VERSION ""

NS_ :

BS_:

BU_: WPC2 PSB SHVU_RR FCS EMCU SLB GW_APSU GW_DLBCU ARS RCM CGW_CCU GW_RLPSU ATS RLHV SGU PFSU ALBCU GW_RRPSU DSAU SWRC SHVU_FR RCS GW_DPSU BLTN_CAM SCM OHCL RWPC RRHV WPC HOD ASAU

BO_ 2214658050 EMS_02_10ms_2: 8 CGW_CCU
 SG_ ENG_AccelPdlVal : 24|10@1+ (0.09784,0) [0|0] "%"  BLTN_CAM,EMCU

BO_ 2210462210 HCU_03_10ms_2: 8 CGW_CCU
 SG_ HCU_HevRdySta : 6|2@1+ (1,0) [0|0] ""  BLTN_CAM,GW_APSU,GW_DLBCU,GW_DPSU,GW_RLPSU,GW_RRPSU,HOD,PFSU,PSB,RCM,RLHV,RRHV,RWPC,SCM,SHVU_FR,SHVU_RR,SWRC,WPC,WPC2

BO_ 1167 ICU_11_1000ms: 8 CGW_CCU
 SG_ ICU_BattAutoCutPreWrng : 36|2@1+ (1,0) [0|0] ""  BLTN_CAM

BO_ 1015 HU_GNSS_13_1000ms: 8 CGW_CCU
 SG_ HU_MM_Altitude : 0|32@1- (0.01,0) [0|0] "m"  BLTN_CAM
 SG_ HU_MM_Heading : 32|32@1+ (1,0) [0|0] "˚"  BLTN_CAM

BO_ 763 SBCM_DRV_03_200ms: 8 CGW_CCU
 SG_ Warn_HoodSwSta_SBCM : 36|2@1+ (1,0) [0|0] ""  BLTN_CAM
 SG_ Hood_TypeOption : 38|2@1+ (1,0) [0|0] ""  BLTN_CAM

BO_ 1048 ICU_08_200ms: 8 CGW_CCU
 SG_ DriveTypeOption : 16|2@1+ (1,0) [0|0] ""  ATS,BLTN_CAM,GW_APSU,GW_DLBCU,GW_DPSU,GW_RLPSU,GW_RRPSU,SHVU_FR,SHVU_RR
 SG_ ICU_PowerAutoCutModSta : 35|2@1+ (1,0) [0|0] ""  BLTN_CAM,GW_APSU,GW_DPSU,GW_RLPSU,GW_RRPSU,PFSU,RLHV,RRHV,SHVU_FR,SHVU_RR

BO_ 1050 BCM_07_200ms: 8 CGW_CCU
 SG_ Lamp_ExtrnlTailLmpOnReq : 38|2@1+ (1,0) [0|0] ""  BLTN_CAM

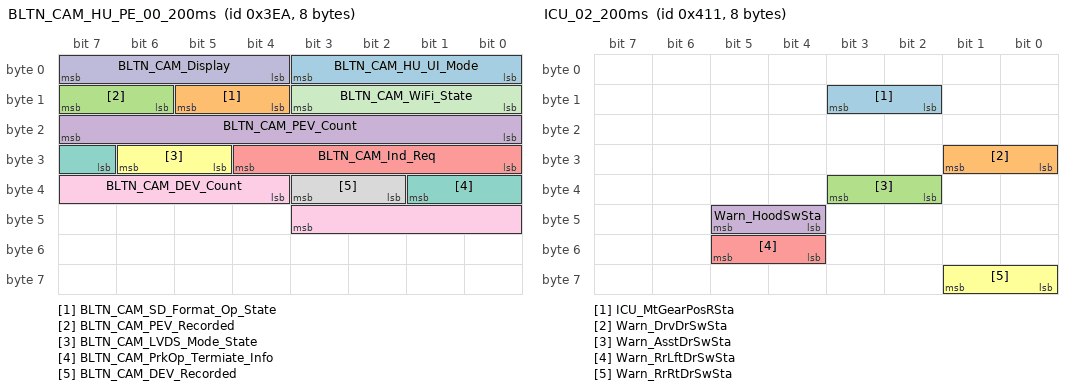
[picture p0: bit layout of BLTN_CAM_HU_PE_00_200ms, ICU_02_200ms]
BO_ 1002 BLTN_CAM_HU_PE_00_200ms: 8 BLTN_CAM
 SG_ BLTN_CAM_HU_UI_Mode : 0|4@1+ (1,0) [0|0] ""  CGW_CCU
 SG_ BLTN_CAM_SD_Format_Op_State : 12|2@1+ (1,0) [0|0] ""  CGW_CCU
 SG_ BLTN_CAM_PEV_Recorded : 14|2@1+ (1,0) [0|0] ""  CGW_CCU
 SG_ BLTN_CAM_PEV_Count : 16|8@1+ (1,0) [0|0] ""  CGW_CCU
 SG_ BLTN_CAM_Ind_Req : 24|5@1+ (1,0) [0|0] ""  CGW_CCU
 SG_ BLTN_CAM_LVDS_Mode_State : 29|2@1+ (1,0) [0|0] ""  CGW_CCU
 SG_ BLTN_CAM_PrkOp_Termiate_Info : 31|3@1+ (1,0) [0|0] ""  CGW_CCU
 SG_ BLTN_CAM_DEV_Recorded : 34|2@1+ (1,0) [0|0] ""  CGW_CCU
 SG_ BLTN_CAM_DEV_Count : 36|8@1+ (1,0) [0|0] ""  CGW_CCU
 SG_ BLTN_CAM_Display : 4|4@1+ (1,0) [0|0] ""  CGW_CCU
 SG_ BLTN_CAM_WiFi_State : 8|4@1+ (1,0) [0|0] ""  CGW_CCU

BO_ 1041 ICU_02_200ms: 8 CGW_CCU
 SG_ ICU_MtGearPosRSta : 10|2@1+ (1,0) [0|0] ""  BLTN_CAM
 SG_ Warn_DrvDrSwSta : 24|2@1+ (1,0) [0|0] ""  BLTN_CAM,GW_DPSU,PSB,RWPC,WPC,WPC2
 SG_ Warn_AsstDrSwSta : 34|2@1+ (1,0) [0|0] ""  ALBCU,BLTN_CAM,GW_APSU,GW_RLPSU,GW_RRPSU,PSB,RWPC,WPC,WPC2
 SG_ Warn_HoodSwSta : 44|2@1+ (1,0) [0|0] ""  BLTN_CAM
 SG_ Warn_RrLftDrSwSta : 52|2@1+ (1,0) [0|0] ""  BLTN_CAM,GW_APSU,GW_RLPSU,GW_RRPSU,RLHV,RWPC,WPC,WPC2
 SG_ Warn_RrRtDrSwSta : 56|2@1+ (1,0) [0|0] ""  BLTN_CAM,GW_APSU,GW_RLPSU,GW_RRPSU,RRHV,RWPC,WPC,WPC2

BO_ 992 BCM_02_200ms: 8 CGW_CCU
 SG_ BAlarm_BglrAlrmCurrentSta : 16|4@1+ (1,0) [0|0] ""  BLTN_CAM

BO_ 1040 ICU_10_200ms: 8 CGW_CCU
 SG_ ICU_BS2SoC : 16|8@1+ (1,0) [0|0] ""  BLTN_CAM

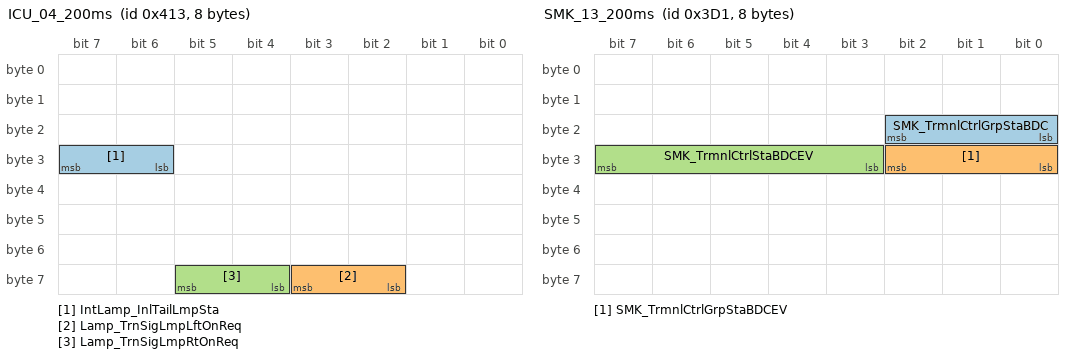
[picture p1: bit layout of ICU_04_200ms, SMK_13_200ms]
BO_ 1043 ICU_04_200ms: 8 CGW_CCU
 SG_ IntLamp_InlTailLmpSta : 30|2@1+ (1,0) [0|0] ""  SWRC,BLTN_CAM,WPC2
 SG_ Lamp_TrnSigLmpLftOnReq : 58|2@1+ (1,0) [0|0] ""  BLTN_CAM
 SG_ Lamp_TrnSigLmpRtOnReq : 60|2@1+ (1,0) [0|0] ""  BLTN_CAM

BO_ 1044 ICU_05_200ms: 8 CGW_CCU
 SG_ Trunk_TrnkTlgtSwSta : 20|2@1+ (1,0) [0|0] ""  BLTN_CAM,GW_APSU,GW_RLPSU,GW_RRPSU,PFSU,RLHV,RRHV
 SG_ C_CrashUnlockState : 58|2@1+ (1,0) [0|0] ""  BLTN_CAM

BO_ 1186 HU_GW_E_02: 8 CGW_CCU
 SG_ C_PreCrankReq : 30|2@1+ (1,0) [0|0] ""  BLTN_CAM

BO_ 1058 BCM_10_200ms: 8 CGW_CCU
 SG_ Wiper_PrkngPosSta : 16|2@1+ (1,0) [0|0] ""  BLTN_CAM
 SG_ Wiper_RainSnsrSta : 22|4@1+ (1,0) [0|0] ""  BLTN_CAM

BO_ 1195 HU_USM_E_04: 8 CGW_CCU
 SG_ CF_AVN_CluUSMReset : 62|2@1+ (1,0) [0|0] ""  ALBCU,ARS,ASAU,ATS,BLTN_CAM,DSAU,GW_APSU,GW_DLBCU,GW_DPSU,GW_RLPSU,GW_RRPSU,PFSU,RCM,RLHV,RRHV,RWPC,SGU,SHVU_FR,SHVU_RR,SLB,WPC,WPC2

BO_ 858 SBCM_AST_02_200ms: 8 CGW_CCU
 SG_ AST_CrashUnlockCmd : 10|1@1+ (1,0) [0|0] ""  BLTN_CAM
 SG_ Warn_AsstDrSwSta_SBCM : 20|2@1+ (1,0) [0|0] ""  ALBCU,ATS,BLTN_CAM,GW_APSU,GW_RLPSU,GW_RRPSU,PSB,RWPC,WPC,WPC2

BO_ 977 SMK_13_200ms: 8 CGW_CCU
 SG_ SMK_TrmnlCtrlGrpStaBDC : 16|3@1+ (1,0) [0|0] ""  BLTN_CAM
 SG_ SMK_TrmnlCtrlGrpStaBDCEV : 24|3@1+ (1,0) [0|0] ""  BLTN_CAM
 SG_ SMK_TrmnlCtrlStaBDCEV : 27|5@1+ (1,0) [0|0] ""  BLTN_CAM

BO_ 862 SBCM_RL_01_200ms: 8 CGW_CCU
 SG_ RL_CrashUnlockCmd : 10|1@1+ (1,0) [0|0] ""  BLTN_CAM
 SG_ Warn_RrLftDrSwSta_SBCM : 16|2@1+ (1,0) [0|0] ""  ATS,BLTN_CAM,GW_APSU,GW_RLPSU,GW_RRPSU,RWPC,WPC,WPC2

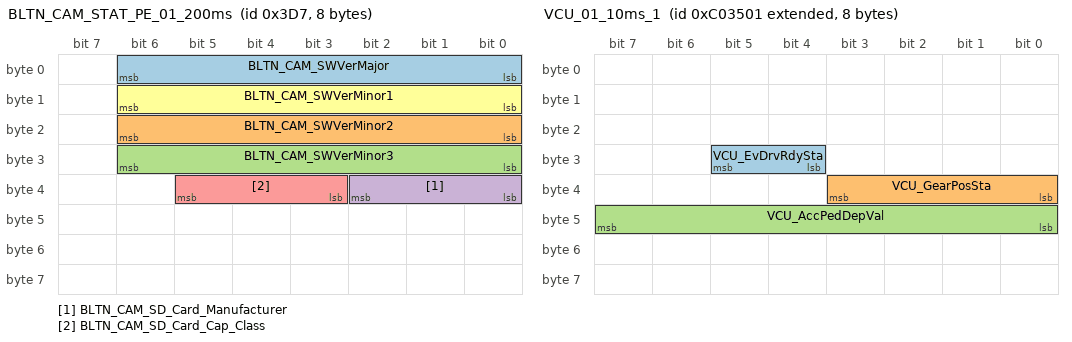
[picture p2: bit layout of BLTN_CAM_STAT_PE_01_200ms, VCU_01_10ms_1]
BO_ 983 BLTN_CAM_STAT_PE_01_200ms: 8 BLTN_CAM
 SG_ BLTN_CAM_SWVerMajor : 0|7@1+ (1,0) [0|0] ""  CGW_CCU
 SG_ BLTN_CAM_SWVerMinor2 : 16|7@1+ (1,0) [0|0] ""  CGW_CCU
 SG_ BLTN_CAM_SWVerMinor3 : 24|7@1+ (1,0) [0|0] ""  CGW_CCU
 SG_ BLTN_CAM_SD_Card_Manufacturer : 32|3@1+ (1,0) [0|0] ""  CGW_CCU
 SG_ BLTN_CAM_SD_Card_Cap_Class : 35|3@1+ (1,1) [0|0] ""  CGW_CCU
 SG_ BLTN_CAM_SWVerMinor1 : 8|7@1+ (1,0) [0|0] ""  CGW_CCU

BO_ 2160080132 VCU_01_10ms_4: 8 CGW_CCU
 SG_ VCU_GearPosStaDisp : 0|4@1+ (1,0) [0|0] ""  SWRC,BLTN_CAM

BO_ 721 HU_GNSS_15_100ms: 8 CGW_CCU
 SG_ HU_DR_Altitude : 17|16@1- (1,0) [0|0] "m"  BLTN_CAM

BO_ 722 HU_GNSS_16_100ms: 8 CGW_CCU
 SG_ HU_DR_Latitude : 0|32@1- (1,0) [0|0] "˚"  BLTN_CAM
 SG_ HU_DR_Longitude : 32|32@1- (1,0) [0|0] "˚"  BLTN_CAM

BO_ 723 HU_GNSS_17_100ms: 8 CGW_CCU
 SG_ HU_DR_Heading : 0|16@1+ (1,0) [0|0] "˚"  BLTN_CAM

BO_ 2160080129 VCU_01_10ms_1: 8 CGW_CCU
 SG_ VCU_EvDrvRdySta : 28|2@1+ (1,0) [0|3] ""  BLTN_CAM,GW_APSU,GW_DLBCU,GW_DPSU,GW_RLPSU,GW_RRPSU,HOD,PFSU,PSB,RCM,RLHV,RRHV,RWPC,SCM,SHVU_FR,SHVU_RR,SWRC,WPC,WPC2
 SG_ VCU_GearPosSta : 32|4@1+ (1,0) [0|15] ""  BLTN_CAM,GW_APSU,GW_DPSU,GW_RLPSU,GW_RRPSU,PFSU,SGU,WPC2
 SG_ VCU_AccPedDepVal : 40|8@1+ (0.3921568627,0) [0|100] "%"  BLTN_CAM

BO_ 1079 CTM_01_200ms: 8 CGW_CCU
 SG_ CTM_TrailerAct : 0|2@1+ (1,0) [0|0] ""  BLTN_CAM

BO_ 2164278529 HTCU_04_10ms_1: 8 CGW_CCU
 SG_ HTCU_GearSlctrDis : 44|4@1+ (1,0) [0|0] ""  BLTN_CAM,GW_APSU,GW_DPSU,GW_RLPSU,GW_RRPSU,PFSU,SWRC

BO_ 1076 IAU_16_200ms: 8 CGW_CCU
 SG_ IAU_ProfileIDRVal : 10|4@1+ (1,0) [0|0] ""  BLTN_CAM,GW_DLBCU,GW_DPSU,RCM,RWPC,SGU,WPC,WPC2

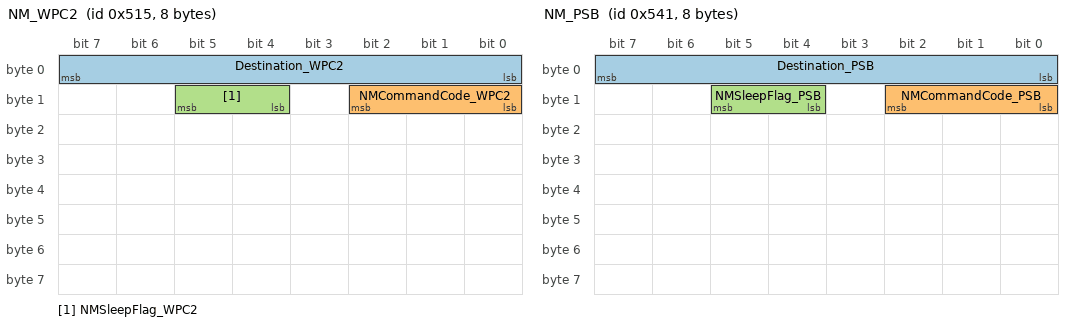
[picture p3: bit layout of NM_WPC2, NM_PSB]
BO_ 1301 NM_WPC2: 8 WPC2
 SG_ Destination_WPC2 : 0|8@1+ (1,0) [0|0] ""  PSB,SHVU_RR,FCS,EMCU,SLB,GW_APSU,GW_DLBCU,ARS,RCM,CGW_CCU,GW_RLPSU,ATS,RLHV,SGU,PFSU,ALBCU,GW_RRPSU,DSAU,SWRC,SHVU_FR,RCS,GW_DPSU,BLTN_CAM,SCM,OHCL,RWPC,RRHV,WPC,HOD,ASAU
 SG_ NMCommandCode_WPC2 : 8|3@1+ (1,0) [0|0] ""  PSB,SHVU_RR,FCS,EMCU,SLB,GW_APSU,GW_DLBCU,ARS,RCM,CGW_CCU,GW_RLPSU,ATS,RLHV,SGU,PFSU,ALBCU,GW_RRPSU,DSAU,SWRC,SHVU_FR,RCS,GW_DPSU,BLTN_CAM,SCM,OHCL,RWPC,RRHV,WPC,HOD,ASAU
 SG_ NMSleepFlag_WPC2 : 12|2@1+ (1,0) [0|0] ""  PSB,SHVU_RR,FCS,EMCU,SLB,GW_APSU,GW_DLBCU,ARS,RCM,CGW_CCU,GW_RLPSU,ATS,RLHV,SGU,PFSU,ALBCU,GW_RRPSU,DSAU,SWRC,SHVU_FR,RCS,GW_DPSU,BLTN_CAM,SCM,OHCL,RWPC,RRHV,WPC,HOD,ASAU

BO_ 1345 NM_PSB: 8 PSB
 SG_ Destination_PSB : 0|8@1+ (1,0) [0|0] ""  WPC2,SHVU_RR,FCS,EMCU,SLB,GW_APSU,GW_DLBCU,ARS,RCM,CGW_CCU,GW_RLPSU,ATS,RLHV,SGU,PFSU,ALBCU,GW_RRPSU,DSAU,SWRC,SHVU_FR,RCS,GW_DPSU,BLTN_CAM,SCM,OHCL,RWPC,RRHV,WPC,HOD,ASAU
 SG_ NMCommandCode_PSB : 8|3@1+ (1,0) [0|0] ""  WPC2,SHVU_RR,FCS,EMCU,SLB,GW_APSU,GW_DLBCU,ARS,RCM,CGW_CCU,GW_RLPSU,ATS,RLHV,SGU,PFSU,ALBCU,GW_RRPSU,DSAU,SWRC,SHVU_FR,RCS,GW_DPSU,BLTN_CAM,SCM,OHCL,RWPC,RRHV,WPC,HOD,ASAU
 SG_ NMSleepFlag_PSB : 12|2@1+ (1,0) [0|0] ""  WPC2,SHVU_RR,FCS,EMCU,SLB,GW_APSU,GW_DLBCU,ARS,RCM,CGW_CCU,GW_RLPSU,ATS,RLHV,SGU,PFSU,ALBCU,GW_RRPSU,DSAU,SWRC,SHVU_FR,RCS,GW_DPSU,BLTN_CAM,SCM,OHCL,RWPC,RRHV,WPC,HOD,ASAU

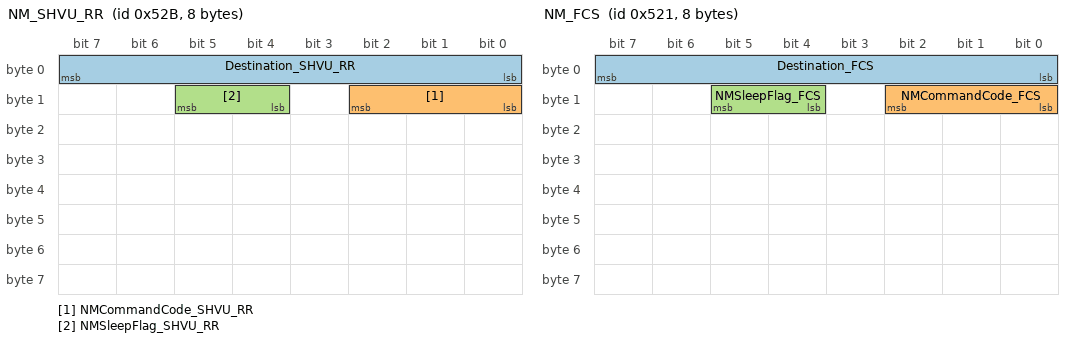
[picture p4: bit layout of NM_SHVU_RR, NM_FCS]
BO_ 1323 NM_SHVU_RR: 8 SHVU_RR
 SG_ Destination_SHVU_RR : 0|8@1+ (1,0) [0|0] ""  WPC2,PSB,FCS,EMCU,SLB,GW_APSU,GW_DLBCU,ARS,RCM,CGW_CCU,GW_RLPSU,ATS,RLHV,SGU,PFSU,ALBCU,GW_RRPSU,DSAU,SWRC,SHVU_FR,RCS,GW_DPSU,BLTN_CAM,SCM,OHCL,RWPC,RRHV,WPC,HOD,ASAU
 SG_ NMCommandCode_SHVU_RR : 8|3@1+ (1,0) [0|0] ""  WPC2,PSB,FCS,EMCU,SLB,GW_APSU,GW_DLBCU,ARS,RCM,CGW_CCU,GW_RLPSU,ATS,RLHV,SGU,PFSU,ALBCU,GW_RRPSU,DSAU,SWRC,SHVU_FR,RCS,GW_DPSU,BLTN_CAM,SCM,OHCL,RWPC,RRHV,WPC,HOD,ASAU
 SG_ NMSleepFlag_SHVU_RR : 12|2@1+ (1,0) [0|0] ""  WPC2,PSB,FCS,EMCU,SLB,GW_APSU,GW_DLBCU,ARS,RCM,CGW_CCU,GW_RLPSU,ATS,RLHV,SGU,PFSU,ALBCU,GW_RRPSU,DSAU,SWRC,SHVU_FR,RCS,GW_DPSU,BLTN_CAM,SCM,OHCL,RWPC,RRHV,WPC,HOD,ASAU

BO_ 1313 NM_FCS: 8 FCS
 SG_ Destination_FCS : 0|8@1+ (1,0) [0|0] ""  WPC2,PSB,SHVU_RR,EMCU,SLB,GW_APSU,GW_DLBCU,ARS,RCM,CGW_CCU,GW_RLPSU,ATS,RLHV,SGU,PFSU,ALBCU,GW_RRPSU,DSAU,SWRC,SHVU_FR,RCS,GW_DPSU,BLTN_CAM,SCM,OHCL,RWPC,RRHV,WPC,HOD,ASAU
 SG_ NMCommandCode_FCS : 8|3@1+ (1,0) [0|0] ""  WPC2,PSB,SHVU_RR,EMCU,SLB,GW_APSU,GW_DLBCU,ARS,RCM,CGW_CCU,GW_RLPSU,ATS,RLHV,SGU,PFSU,ALBCU,GW_RRPSU,DSAU,SWRC,SHVU_FR,RCS,GW_DPSU,BLTN_CAM,SCM,OHCL,RWPC,RRHV,WPC,HOD,ASAU
 SG_ NMSleepFlag_FCS : 12|2@1+ (1,0) [0|0] ""  WPC2,PSB,SHVU_RR,EMCU,SLB,GW_APSU,GW_DLBCU,ARS,RCM,CGW_CCU,GW_RLPSU,ATS,RLHV,SGU,PFSU,ALBCU,GW_RRPSU,DSAU,SWRC,SHVU_FR,RCS,GW_DPSU,BLTN_CAM,SCM,OHCL,RWPC,RRHV,WPC,HOD,ASAU

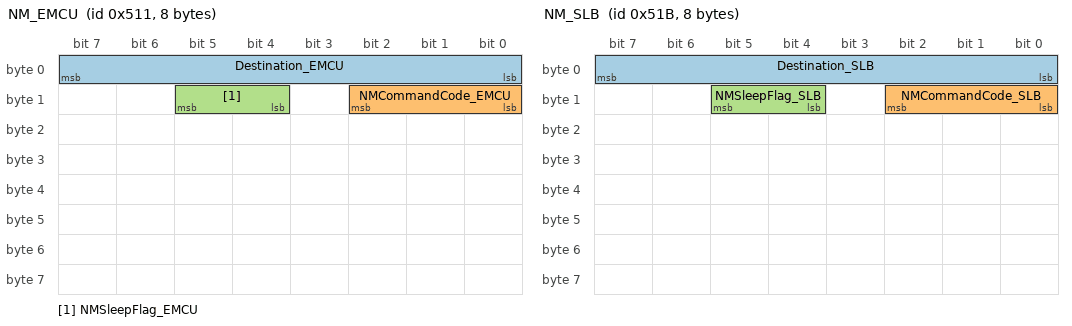
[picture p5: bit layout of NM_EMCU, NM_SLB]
BO_ 1297 NM_EMCU: 8 EMCU
 SG_ Destination_EMCU : 0|8@1+ (1,0) [0|0] ""  WPC2,PSB,SHVU_RR,FCS,SLB,GW_APSU,GW_DLBCU,ARS,RCM,CGW_CCU,GW_RLPSU,ATS,RLHV,SGU,PFSU,ALBCU,GW_RRPSU,DSAU,SWRC,SHVU_FR,RCS,GW_DPSU,BLTN_CAM,SCM,OHCL,RWPC,RRHV,WPC,HOD,ASAU
 SG_ NMCommandCode_EMCU : 8|3@1+ (1,0) [0|0] ""  WPC2,PSB,SHVU_RR,FCS,SLB,GW_APSU,GW_DLBCU,ARS,RCM,CGW_CCU,GW_RLPSU,ATS,RLHV,SGU,PFSU,ALBCU,GW_RRPSU,DSAU,SWRC,SHVU_FR,RCS,GW_DPSU,BLTN_CAM,SCM,OHCL,RWPC,RRHV,WPC,HOD,ASAU
 SG_ NMSleepFlag_EMCU : 12|2@1+ (1,0) [0|0] ""  WPC2,PSB,SHVU_RR,FCS,SLB,GW_APSU,GW_DLBCU,ARS,RCM,CGW_CCU,GW_RLPSU,ATS,RLHV,SGU,PFSU,ALBCU,GW_RRPSU,DSAU,SWRC,SHVU_FR,RCS,GW_DPSU,BLTN_CAM,SCM,OHCL,RWPC,RRHV,WPC,HOD,ASAU

BO_ 1307 NM_SLB: 8 SLB
 SG_ Destination_SLB : 0|8@1+ (1,0) [0|0] ""  WPC2,PSB,SHVU_RR,FCS,EMCU,GW_APSU,GW_DLBCU,ARS,RCM,CGW_CCU,GW_RLPSU,ATS,RLHV,SGU,PFSU,ALBCU,GW_RRPSU,DSAU,SWRC,SHVU_FR,RCS,GW_DPSU,BLTN_CAM,SCM,OHCL,RWPC,RRHV,WPC,HOD,ASAU
 SG_ NMCommandCode_SLB : 8|3@1+ (1,0) [0|0] ""  WPC2,PSB,SHVU_RR,FCS,EMCU,GW_APSU,GW_DLBCU,ARS,RCM,CGW_CCU,GW_RLPSU,ATS,RLHV,SGU,PFSU,ALBCU,GW_RRPSU,DSAU,SWRC,SHVU_FR,RCS,GW_DPSU,BLTN_CAM,SCM,OHCL,RWPC,RRHV,WPC,HOD,ASAU
 SG_ NMSleepFlag_SLB : 12|2@1+ (1,0) [0|0] ""  WPC2,PSB,SHVU_RR,FCS,EMCU,GW_APSU,GW_DLBCU,ARS,RCM,CGW_CCU,GW_RLPSU,ATS,RLHV,SGU,PFSU,ALBCU,GW_RRPSU,DSAU,SWRC,SHVU_FR,RCS,GW_DPSU,BLTN_CAM,SCM,OHCL,RWPC,RRHV,WPC,HOD,ASAU

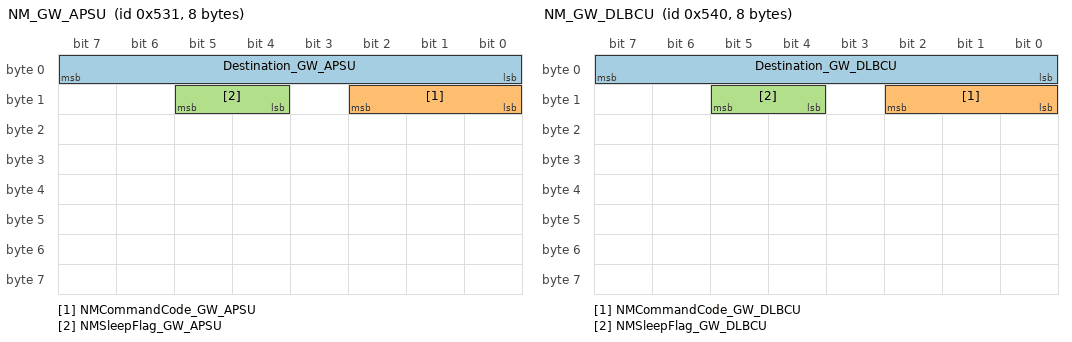
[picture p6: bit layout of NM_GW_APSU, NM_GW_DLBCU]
BO_ 1329 NM_GW_APSU: 8 GW_APSU
 SG_ Destination_GW_APSU : 0|8@1+ (1,0) [0|0] ""  WPC2,PSB,SHVU_RR,FCS,EMCU,SLB,GW_DLBCU,ARS,RCM,CGW_CCU,GW_RLPSU,ATS,RLHV,SGU,PFSU,ALBCU,GW_RRPSU,DSAU,SWRC,SHVU_FR,RCS,GW_DPSU,BLTN_CAM,SCM,OHCL,RWPC,RRHV,WPC,HOD,ASAU
 SG_ NMCommandCode_GW_APSU : 8|3@1+ (1,0) [0|0] ""  WPC2,PSB,SHVU_RR,FCS,EMCU,SLB,GW_DLBCU,ARS,RCM,CGW_CCU,GW_RLPSU,ATS,RLHV,SGU,PFSU,ALBCU,GW_RRPSU,DSAU,SWRC,SHVU_FR,RCS,GW_DPSU,BLTN_CAM,SCM,OHCL,RWPC,RRHV,WPC,HOD,ASAU
 SG_ NMSleepFlag_GW_APSU : 12|2@1+ (1,0) [0|0] ""  WPC2,PSB,SHVU_RR,FCS,EMCU,SLB,GW_DLBCU,ARS,RCM,CGW_CCU,GW_RLPSU,ATS,RLHV,SGU,PFSU,ALBCU,GW_RRPSU,DSAU,SWRC,SHVU_FR,RCS,GW_DPSU,BLTN_CAM,SCM,OHCL,RWPC,RRHV,WPC,HOD,ASAU

BO_ 1344 NM_GW_DLBCU: 8 GW_DLBCU
 SG_ Destination_GW_DLBCU : 0|8@1+ (1,0) [0|0] ""  WPC2,PSB,SHVU_RR,FCS,EMCU,SLB,GW_APSU,ARS,RCM,CGW_CCU,GW_RLPSU,ATS,RLHV,SGU,PFSU,ALBCU,GW_RRPSU,DSAU,SWRC,SHVU_FR,RCS,GW_DPSU,BLTN_CAM,SCM,OHCL,RWPC,RRHV,WPC,HOD,ASAU
 SG_ NMCommandCode_GW_DLBCU : 8|3@1+ (1,0) [0|0] ""  WPC2,PSB,SHVU_RR,FCS,EMCU,SLB,GW_APSU,ARS,RCM,CGW_CCU,GW_RLPSU,ATS,RLHV,SGU,PFSU,ALBCU,GW_RRPSU,DSAU,SWRC,SHVU_FR,RCS,GW_DPSU,BLTN_CAM,SCM,OHCL,RWPC,RRHV,WPC,HOD,ASAU
 SG_ NMSleepFlag_GW_DLBCU : 12|2@1+ (1,0) [0|0] ""  WPC2,PSB,SHVU_RR,FCS,EMCU,SLB,GW_APSU,ARS,RCM,CGW_CCU,GW_RLPSU,ATS,RLHV,SGU,PFSU,ALBCU,GW_RRPSU,DSAU,SWRC,SHVU_FR,RCS,GW_DPSU,BLTN_CAM,SCM,OHCL,RWPC,RRHV,WPC,HOD,ASAU

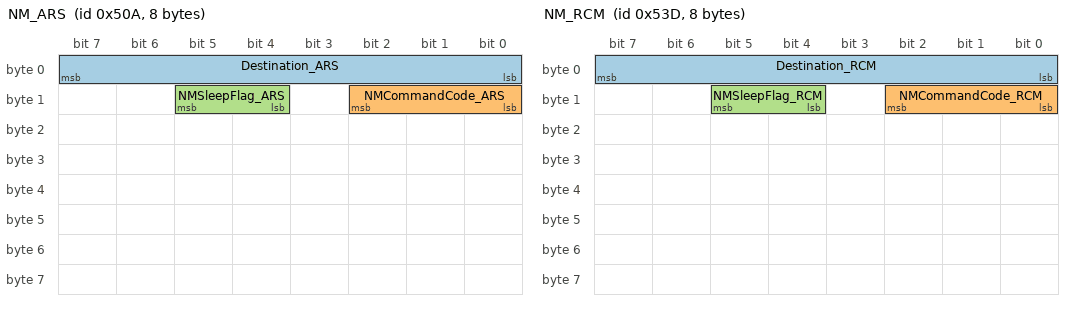
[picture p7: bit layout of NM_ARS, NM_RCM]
BO_ 1290 NM_ARS: 8 ARS
 SG_ Destination_ARS : 0|8@1+ (1,0) [0|0] ""  WPC2,PSB,SHVU_RR,FCS,EMCU,SLB,GW_APSU,GW_DLBCU,RCM,CGW_CCU,GW_RLPSU,ATS,RLHV,SGU,PFSU,ALBCU,GW_RRPSU,DSAU,SWRC,SHVU_FR,RCS,GW_DPSU,BLTN_CAM,SCM,OHCL,RWPC,RRHV,WPC,HOD,ASAU
 SG_ NMCommandCode_ARS : 8|3@1+ (1,0) [0|0] ""  WPC2,PSB,SHVU_RR,FCS,EMCU,SLB,GW_APSU,GW_DLBCU,RCM,CGW_CCU,GW_RLPSU,ATS,RLHV,SGU,PFSU,ALBCU,GW_RRPSU,DSAU,SWRC,SHVU_FR,RCS,GW_DPSU,BLTN_CAM,SCM,OHCL,RWPC,RRHV,WPC,HOD,ASAU
 SG_ NMSleepFlag_ARS : 12|2@1+ (1,0) [0|0] ""  WPC2,PSB,SHVU_RR,FCS,EMCU,SLB,GW_APSU,GW_DLBCU,RCM,CGW_CCU,GW_RLPSU,ATS,RLHV,SGU,PFSU,ALBCU,GW_RRPSU,DSAU,SWRC,SHVU_FR,RCS,GW_DPSU,BLTN_CAM,SCM,OHCL,RWPC,RRHV,WPC,HOD,ASAU

BO_ 1341 NM_RCM: 8 RCM
 SG_ Destination_RCM : 0|8@1+ (1,0) [0|0] ""  WPC2,PSB,SHVU_RR,FCS,EMCU,SLB,GW_APSU,GW_DLBCU,ARS,CGW_CCU,GW_RLPSU,ATS,RLHV,SGU,PFSU,ALBCU,GW_RRPSU,DSAU,SWRC,SHVU_FR,RCS,GW_DPSU,BLTN_CAM,SCM,OHCL,RWPC,RRHV,WPC,HOD,ASAU
 SG_ NMCommandCode_RCM : 8|3@1+ (1,0) [0|0] ""  WPC2,PSB,SHVU_RR,FCS,EMCU,SLB,GW_APSU,GW_DLBCU,ARS,CGW_CCU,GW_RLPSU,ATS,RLHV,SGU,PFSU,ALBCU,GW_RRPSU,DSAU,SWRC,SHVU_FR,RCS,GW_DPSU,BLTN_CAM,SCM,OHCL,RWPC,RRHV,WPC,HOD,ASAU
 SG_ NMSleepFlag_RCM : 12|2@1+ (1,0) [0|0] ""  WPC2,PSB,SHVU_RR,FCS,EMCU,SLB,GW_APSU,GW_DLBCU,ARS,CGW_CCU,GW_RLPSU,ATS,RLHV,SGU,PFSU,ALBCU,GW_RRPSU,DSAU,SWRC,SHVU_FR,RCS,GW_DPSU,BLTN_CAM,SCM,OHCL,RWPC,RRHV,WPC,HOD,ASAU

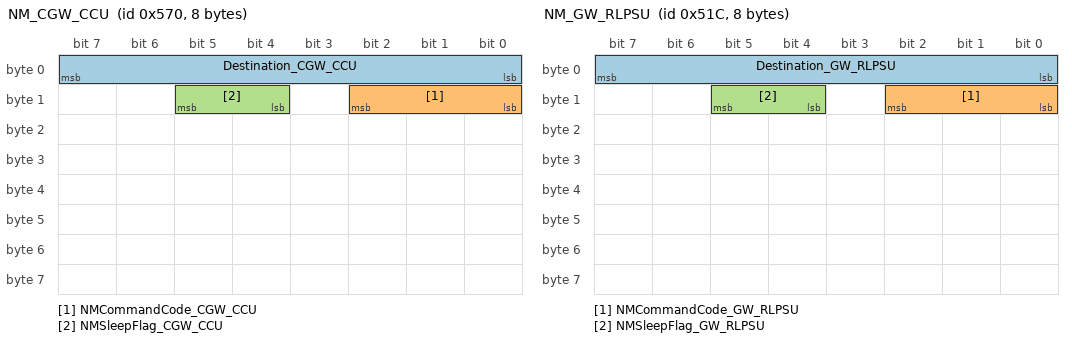
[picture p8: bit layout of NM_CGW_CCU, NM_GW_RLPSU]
BO_ 1392 NM_CGW_CCU: 8 CGW_CCU
 SG_ Destination_CGW_CCU : 0|8@1+ (1,0) [0|0] ""  WPC2,PSB,SHVU_RR,FCS,EMCU,SLB,GW_APSU,GW_DLBCU,ARS,RCM,GW_RLPSU,ATS,RLHV,SGU,PFSU,ALBCU,GW_RRPSU,DSAU,SWRC,SHVU_FR,RCS,GW_DPSU,BLTN_CAM,SCM,OHCL,RWPC,RRHV,WPC,HOD,ASAU
 SG_ NMCommandCode_CGW_CCU : 8|3@1+ (1,0) [0|0] ""  WPC2,PSB,SHVU_RR,FCS,EMCU,SLB,GW_APSU,GW_DLBCU,ARS,RCM,GW_RLPSU,ATS,RLHV,SGU,PFSU,ALBCU,GW_RRPSU,DSAU,SWRC,SHVU_FR,RCS,GW_DPSU,BLTN_CAM,SCM,OHCL,RWPC,RRHV,WPC,HOD,ASAU
 SG_ NMSleepFlag_CGW_CCU : 12|2@1+ (1,0) [0|0] ""  WPC2,PSB,SHVU_RR,FCS,EMCU,SLB,GW_APSU,GW_DLBCU,ARS,RCM,GW_RLPSU,ATS,RLHV,SGU,PFSU,ALBCU,GW_RRPSU,DSAU,SWRC,SHVU_FR,RCS,GW_DPSU,BLTN_CAM,SCM,OHCL,RWPC,RRHV,WPC,HOD,ASAU

BO_ 1308 NM_GW_RLPSU: 8 GW_RLPSU
 SG_ Destination_GW_RLPSU : 0|8@1+ (1,0) [0|0] ""  WPC2,PSB,SHVU_RR,FCS,EMCU,SLB,GW_APSU,GW_DLBCU,ARS,RCM,CGW_CCU,ATS,RLHV,SGU,PFSU,ALBCU,GW_RRPSU,DSAU,SWRC,SHVU_FR,RCS,GW_DPSU,BLTN_CAM,SCM,OHCL,RWPC,RRHV,WPC,HOD,ASAU
 SG_ NMCommandCode_GW_RLPSU : 8|3@1+ (1,0) [0|0] ""  WPC2,PSB,SHVU_RR,FCS,EMCU,SLB,GW_APSU,GW_DLBCU,ARS,RCM,CGW_CCU,ATS,RLHV,SGU,PFSU,ALBCU,GW_RRPSU,DSAU,SWRC,SHVU_FR,RCS,GW_DPSU,BLTN_CAM,SCM,OHCL,RWPC,RRHV,WPC,HOD,ASAU
 SG_ NMSleepFlag_GW_RLPSU : 12|2@1+ (1,0) [0|0] ""  WPC2,PSB,SHVU_RR,FCS,EMCU,SLB,GW_APSU,GW_DLBCU,ARS,RCM,CGW_CCU,ATS,RLHV,SGU,PFSU,ALBCU,GW_RRPSU,DSAU,SWRC,SHVU_FR,RCS,GW_DPSU,BLTN_CAM,SCM,OHCL,RWPC,RRHV,WPC,HOD,ASAU

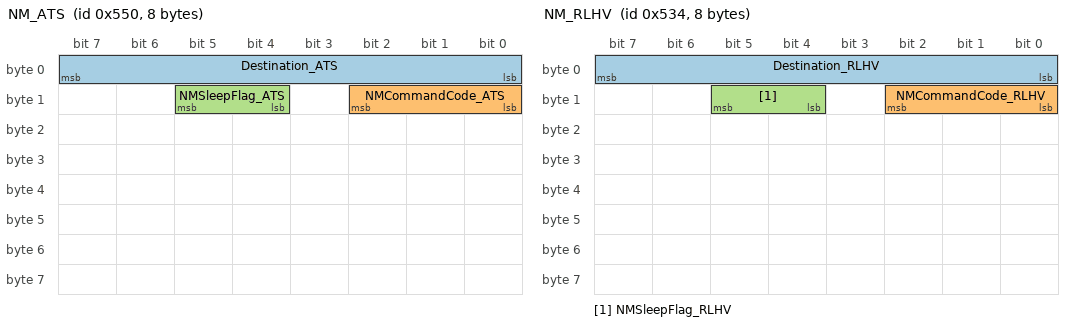
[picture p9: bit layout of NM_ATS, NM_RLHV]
BO_ 1360 NM_ATS: 8 ATS
 SG_ Destination_ATS : 0|8@1+ (1,0) [0|0] ""  WPC2,PSB,SHVU_RR,FCS,EMCU,SLB,GW_APSU,GW_DLBCU,ARS,RCM,CGW_CCU,GW_RLPSU,RLHV,SGU,PFSU,ALBCU,GW_RRPSU,DSAU,SWRC,SHVU_FR,RCS,GW_DPSU,BLTN_CAM,SCM,OHCL,RWPC,RRHV,WPC,HOD,ASAU
 SG_ NMCommandCode_ATS : 8|3@1+ (1,0) [0|0] ""  WPC2,PSB,SHVU_RR,FCS,EMCU,SLB,GW_APSU,GW_DLBCU,ARS,RCM,CGW_CCU,GW_RLPSU,RLHV,SGU,PFSU,ALBCU,GW_RRPSU,DSAU,SWRC,SHVU_FR,RCS,GW_DPSU,BLTN_CAM,SCM,OHCL,RWPC,RRHV,WPC,HOD,ASAU
 SG_ NMSleepFlag_ATS : 12|2@1+ (1,0) [0|0] ""  WPC2,PSB,SHVU_RR,FCS,EMCU,SLB,GW_APSU,GW_DLBCU,ARS,RCM,CGW_CCU,GW_RLPSU,RLHV,SGU,PFSU,ALBCU,GW_RRPSU,DSAU,SWRC,SHVU_FR,RCS,GW_DPSU,BLTN_CAM,SCM,OHCL,RWPC,RRHV,WPC,HOD,ASAU

BO_ 1332 NM_RLHV: 8 RLHV
 SG_ Destination_RLHV : 0|8@1+ (1,0) [0|0] ""  WPC2,PSB,SHVU_RR,FCS,EMCU,SLB,GW_APSU,GW_DLBCU,ARS,RCM,CGW_CCU,GW_RLPSU,ATS,SGU,PFSU,ALBCU,GW_RRPSU,DSAU,SWRC,SHVU_FR,RCS,GW_DPSU,BLTN_CAM,SCM,OHCL,RWPC,RRHV,WPC,HOD,ASAU
 SG_ NMCommandCode_RLHV : 8|3@1+ (1,0) [0|0] ""  WPC2,PSB,SHVU_RR,FCS,EMCU,SLB,GW_APSU,GW_DLBCU,ARS,RCM,CGW_CCU,GW_RLPSU,ATS,SGU,PFSU,ALBCU,GW_RRPSU,DSAU,SWRC,SHVU_FR,RCS,GW_DPSU,BLTN_CAM,SCM,OHCL,RWPC,RRHV,WPC,HOD,ASAU
 SG_ NMSleepFlag_RLHV : 12|2@1+ (1,0) [0|0] ""  WPC2,PSB,SHVU_RR,FCS,EMCU,SLB,GW_APSU,GW_DLBCU,ARS,RCM,CGW_CCU,GW_RLPSU,ATS,SGU,PFSU,ALBCU,GW_RRPSU,DSAU,SWRC,SHVU_FR,RCS,GW_DPSU,BLTN_CAM,SCM,OHCL,RWPC,RRHV,WPC,HOD,ASAU

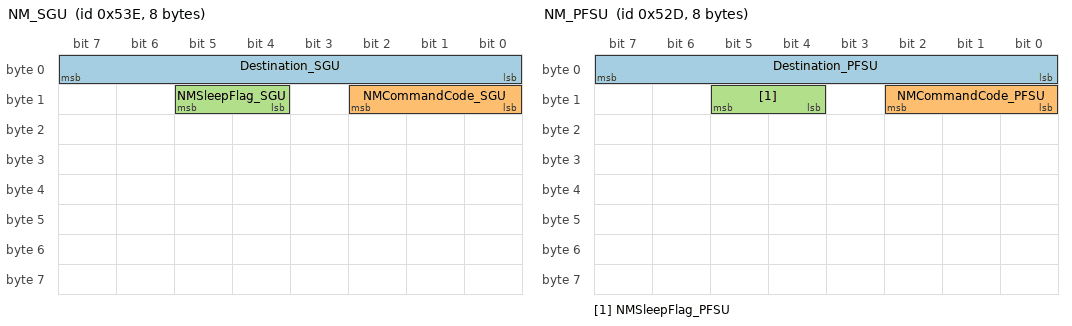
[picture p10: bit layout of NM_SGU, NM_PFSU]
BO_ 1342 NM_SGU: 8 SGU
 SG_ Destination_SGU : 0|8@1+ (1,0) [0|0] ""  WPC2,PSB,SHVU_RR,FCS,EMCU,SLB,GW_APSU,GW_DLBCU,ARS,RCM,CGW_CCU,GW_RLPSU,ATS,RLHV,PFSU,ALBCU,GW_RRPSU,DSAU,SWRC,SHVU_FR,RCS,GW_DPSU,BLTN_CAM,SCM,OHCL,RWPC,RRHV,WPC,HOD,ASAU
 SG_ NMCommandCode_SGU : 8|3@1+ (1,0) [0|0] ""  WPC2,PSB,SHVU_RR,FCS,EMCU,SLB,GW_APSU,GW_DLBCU,ARS,RCM,CGW_CCU,GW_RLPSU,ATS,RLHV,PFSU,ALBCU,GW_RRPSU,DSAU,SWRC,SHVU_FR,RCS,GW_DPSU,BLTN_CAM,SCM,OHCL,RWPC,RRHV,WPC,HOD,ASAU
 SG_ NMSleepFlag_SGU : 12|2@1+ (1,0) [0|0] ""  WPC2,PSB,SHVU_RR,FCS,EMCU,SLB,GW_APSU,GW_DLBCU,ARS,RCM,CGW_CCU,GW_RLPSU,ATS,RLHV,PFSU,ALBCU,GW_RRPSU,DSAU,SWRC,SHVU_FR,RCS,GW_DPSU,BLTN_CAM,SCM,OHCL,RWPC,RRHV,WPC,HOD,ASAU

BO_ 1325 NM_PFSU: 8 PFSU
 SG_ Destination_PFSU : 0|8@1+ (1,0) [0|0] ""  WPC2,PSB,SHVU_RR,FCS,EMCU,SLB,GW_APSU,GW_DLBCU,ARS,RCM,CGW_CCU,GW_RLPSU,ATS,RLHV,SGU,ALBCU,GW_RRPSU,DSAU,SWRC,SHVU_FR,RCS,GW_DPSU,BLTN_CAM,SCM,OHCL,RWPC,RRHV,WPC,HOD,ASAU
 SG_ NMCommandCode_PFSU : 8|3@1+ (1,0) [0|0] ""  WPC2,PSB,SHVU_RR,FCS,EMCU,SLB,GW_APSU,GW_DLBCU,ARS,RCM,CGW_CCU,GW_RLPSU,ATS,RLHV,SGU,ALBCU,GW_RRPSU,DSAU,SWRC,SHVU_FR,RCS,GW_DPSU,BLTN_CAM,SCM,OHCL,RWPC,RRHV,WPC,HOD,ASAU
 SG_ NMSleepFlag_PFSU : 12|2@1+ (1,0) [0|0] ""  WPC2,PSB,SHVU_RR,FCS,EMCU,SLB,GW_APSU,GW_DLBCU,ARS,RCM,CGW_CCU,GW_RLPSU,ATS,RLHV,SGU,ALBCU,GW_RRPSU,DSAU,SWRC,SHVU_FR,RCS,GW_DPSU,BLTN_CAM,SCM,OHCL,RWPC,RRHV,WPC,HOD,ASAU

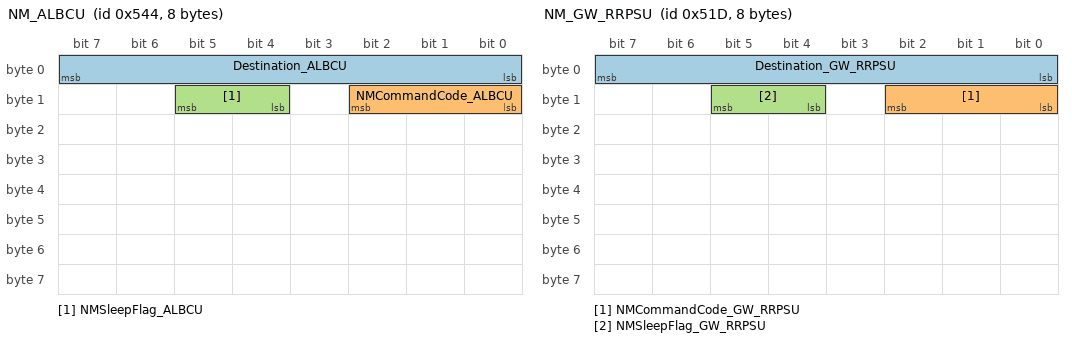
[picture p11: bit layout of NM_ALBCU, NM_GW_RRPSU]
BO_ 1348 NM_ALBCU: 8 ALBCU
 SG_ Destination_ALBCU : 0|8@1+ (1,0) [0|0] ""  WPC2,PSB,SHVU_RR,FCS,EMCU,SLB,GW_APSU,GW_DLBCU,ARS,RCM,CGW_CCU,GW_RLPSU,ATS,RLHV,SGU,PFSU,GW_RRPSU,DSAU,SWRC,SHVU_FR,RCS,GW_DPSU,BLTN_CAM,SCM,OHCL,RWPC,RRHV,WPC,HOD,ASAU
 SG_ NMCommandCode_ALBCU : 8|3@1+ (1,0) [0|0] ""  WPC2,PSB,SHVU_RR,FCS,EMCU,SLB,GW_APSU,GW_DLBCU,ARS,RCM,CGW_CCU,GW_RLPSU,ATS,RLHV,SGU,PFSU,GW_RRPSU,DSAU,SWRC,SHVU_FR,RCS,GW_DPSU,BLTN_CAM,SCM,OHCL,RWPC,RRHV,WPC,HOD,ASAU
 SG_ NMSleepFlag_ALBCU : 12|2@1+ (1,0) [0|0] ""  WPC2,PSB,SHVU_RR,FCS,EMCU,SLB,GW_APSU,GW_DLBCU,ARS,RCM,CGW_CCU,GW_RLPSU,ATS,RLHV,SGU,PFSU,GW_RRPSU,DSAU,SWRC,SHVU_FR,RCS,GW_DPSU,BLTN_CAM,SCM,OHCL,RWPC,RRHV,WPC,HOD,ASAU

BO_ 1309 NM_GW_RRPSU: 8 GW_RRPSU
 SG_ Destination_GW_RRPSU : 0|8@1+ (1,0) [0|0] ""  WPC2,PSB,SHVU_RR,FCS,EMCU,SLB,GW_APSU,GW_DLBCU,ARS,RCM,CGW_CCU,GW_RLPSU,ATS,RLHV,SGU,PFSU,ALBCU,DSAU,SWRC,SHVU_FR,RCS,GW_DPSU,BLTN_CAM,SCM,OHCL,RWPC,RRHV,WPC,HOD,ASAU
 SG_ NMCommandCode_GW_RRPSU : 8|3@1+ (1,0) [0|0] ""  WPC2,PSB,SHVU_RR,FCS,EMCU,SLB,GW_APSU,GW_DLBCU,ARS,RCM,CGW_CCU,GW_RLPSU,ATS,RLHV,SGU,PFSU,ALBCU,DSAU,SWRC,SHVU_FR,RCS,GW_DPSU,BLTN_CAM,SCM,OHCL,RWPC,RRHV,WPC,HOD,ASAU
 SG_ NMSleepFlag_GW_RRPSU : 12|2@1+ (1,0) [0|0] ""  WPC2,PSB,SHVU_RR,FCS,EMCU,SLB,GW_APSU,GW_DLBCU,ARS,RCM,CGW_CCU,GW_RLPSU,ATS,RLHV,SGU,PFSU,ALBCU,DSAU,SWRC,SHVU_FR,RCS,GW_DPSU,BLTN_CAM,SCM,OHCL,RWPC,RRHV,WPC,HOD,ASAU

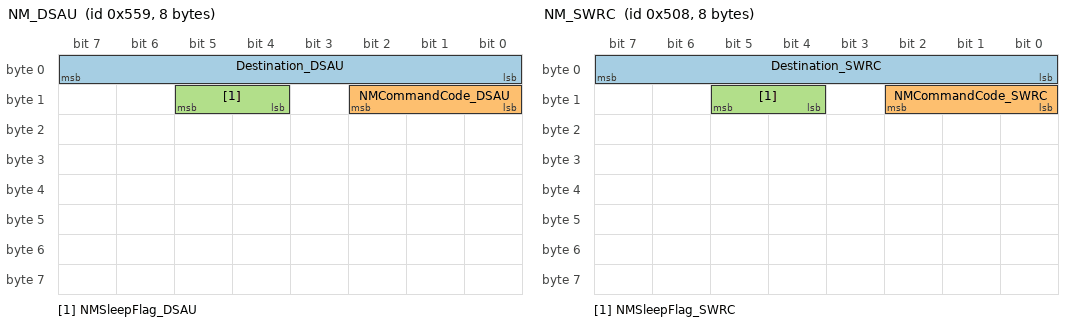
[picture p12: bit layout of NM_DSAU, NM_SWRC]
BO_ 1369 NM_DSAU: 8 DSAU
 SG_ Destination_DSAU : 0|8@1+ (1,0) [0|0] ""  WPC2,PSB,SHVU_RR,FCS,EMCU,SLB,GW_APSU,GW_DLBCU,ARS,RCM,CGW_CCU,GW_RLPSU,ATS,RLHV,SGU,PFSU,ALBCU,GW_RRPSU,SWRC,SHVU_FR,RCS,GW_DPSU,BLTN_CAM,SCM,OHCL,RWPC,RRHV,WPC,HOD,ASAU
 SG_ NMCommandCode_DSAU : 8|3@1+ (1,0) [0|0] ""  WPC2,PSB,SHVU_RR,FCS,EMCU,SLB,GW_APSU,GW_DLBCU,ARS,RCM,CGW_CCU,GW_RLPSU,ATS,RLHV,SGU,PFSU,ALBCU,GW_RRPSU,SWRC,SHVU_FR,RCS,GW_DPSU,BLTN_CAM,SCM,OHCL,RWPC,RRHV,WPC,HOD,ASAU
 SG_ NMSleepFlag_DSAU : 12|2@1+ (1,0) [0|0] ""  WPC2,PSB,SHVU_RR,FCS,EMCU,SLB,GW_APSU,GW_DLBCU,ARS,RCM,CGW_CCU,GW_RLPSU,ATS,RLHV,SGU,PFSU,ALBCU,GW_RRPSU,SWRC,SHVU_FR,RCS,GW_DPSU,BLTN_CAM,SCM,OHCL,RWPC,RRHV,WPC,HOD,ASAU

BO_ 1288 NM_SWRC: 8 SWRC
 SG_ Destination_SWRC : 0|8@1+ (1,0) [0|0] ""  WPC2,PSB,SHVU_RR,FCS,EMCU,SLB,GW_APSU,GW_DLBCU,ARS,RCM,CGW_CCU,GW_RLPSU,ATS,RLHV,SGU,PFSU,ALBCU,GW_RRPSU,DSAU,SHVU_FR,RCS,GW_DPSU,BLTN_CAM,SCM,OHCL,RWPC,RRHV,WPC,HOD,ASAU
 SG_ NMCommandCode_SWRC : 8|3@1+ (1,0) [0|0] ""  WPC2,PSB,SHVU_RR,FCS,EMCU,SLB,GW_APSU,GW_DLBCU,ARS,RCM,CGW_CCU,GW_RLPSU,ATS,RLHV,SGU,PFSU,ALBCU,GW_RRPSU,DSAU,SHVU_FR,RCS,GW_DPSU,BLTN_CAM,SCM,OHCL,RWPC,RRHV,WPC,HOD,ASAU
 SG_ NMSleepFlag_SWRC : 12|2@1+ (1,0) [0|0] ""  WPC2,PSB,SHVU_RR,FCS,EMCU,SLB,GW_APSU,GW_DLBCU,ARS,RCM,CGW_CCU,GW_RLPSU,ATS,RLHV,SGU,PFSU,ALBCU,GW_RRPSU,DSAU,SHVU_FR,RCS,GW_DPSU,BLTN_CAM,SCM,OHCL,RWPC,RRHV,WPC,HOD,ASAU

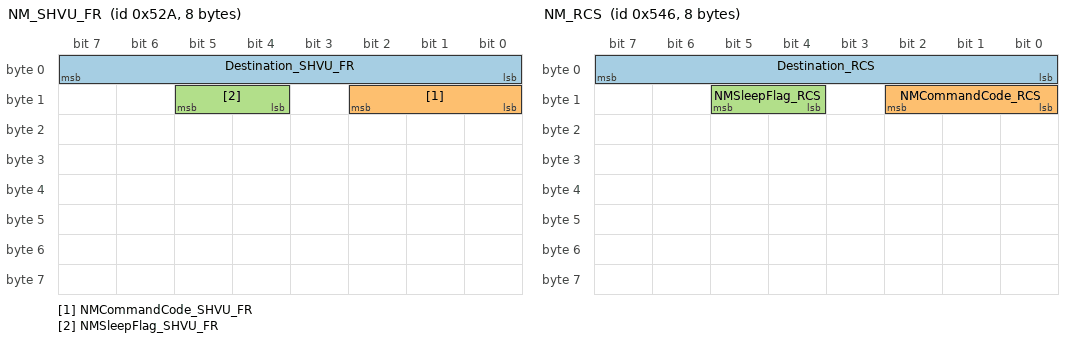
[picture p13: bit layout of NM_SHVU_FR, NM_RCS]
BO_ 1322 NM_SHVU_FR: 8 SHVU_FR
 SG_ Destination_SHVU_FR : 0|8@1+ (1,0) [0|0] ""  WPC2,PSB,SHVU_RR,FCS,EMCU,SLB,GW_APSU,GW_DLBCU,ARS,RCM,CGW_CCU,GW_RLPSU,ATS,RLHV,SGU,PFSU,ALBCU,GW_RRPSU,DSAU,SWRC,RCS,GW_DPSU,BLTN_CAM,SCM,OHCL,RWPC,RRHV,WPC,HOD,ASAU
 SG_ NMCommandCode_SHVU_FR : 8|3@1+ (1,0) [0|0] ""  WPC2,PSB,SHVU_RR,FCS,EMCU,SLB,GW_APSU,GW_DLBCU,ARS,RCM,CGW_CCU,GW_RLPSU,ATS,RLHV,SGU,PFSU,ALBCU,GW_RRPSU,DSAU,SWRC,RCS,GW_DPSU,BLTN_CAM,SCM,OHCL,RWPC,RRHV,WPC,HOD,ASAU
 SG_ NMSleepFlag_SHVU_FR : 12|2@1+ (1,0) [0|0] ""  WPC2,PSB,SHVU_RR,FCS,EMCU,SLB,GW_APSU,GW_DLBCU,ARS,RCM,CGW_CCU,GW_RLPSU,ATS,RLHV,SGU,PFSU,ALBCU,GW_RRPSU,DSAU,SWRC,RCS,GW_DPSU,BLTN_CAM,SCM,OHCL,RWPC,RRHV,WPC,HOD,ASAU

BO_ 1350 NM_RCS: 8 RCS
 SG_ Destination_RCS : 0|8@1+ (1,0) [0|0] ""  WPC2,PSB,SHVU_RR,FCS,EMCU,SLB,GW_APSU,GW_DLBCU,ARS,RCM,CGW_CCU,GW_RLPSU,ATS,RLHV,SGU,PFSU,ALBCU,GW_RRPSU,DSAU,SWRC,SHVU_FR,GW_DPSU,BLTN_CAM,SCM,OHCL,RWPC,RRHV,WPC,HOD,ASAU
 SG_ NMCommandCode_RCS : 8|3@1+ (1,0) [0|0] ""  WPC2,PSB,SHVU_RR,FCS,EMCU,SLB,GW_APSU,GW_DLBCU,ARS,RCM,CGW_CCU,GW_RLPSU,ATS,RLHV,SGU,PFSU,ALBCU,GW_RRPSU,DSAU,SWRC,SHVU_FR,GW_DPSU,BLTN_CAM,SCM,OHCL,RWPC,RRHV,WPC,HOD,ASAU
 SG_ NMSleepFlag_RCS : 12|2@1+ (1,0) [0|0] ""  WPC2,PSB,SHVU_RR,FCS,EMCU,SLB,GW_APSU,GW_DLBCU,ARS,RCM,CGW_CCU,GW_RLPSU,ATS,RLHV,SGU,PFSU,ALBCU,GW_RRPSU,DSAU,SWRC,SHVU_FR,GW_DPSU,BLTN_CAM,SCM,OHCL,RWPC,RRHV,WPC,HOD,ASAU

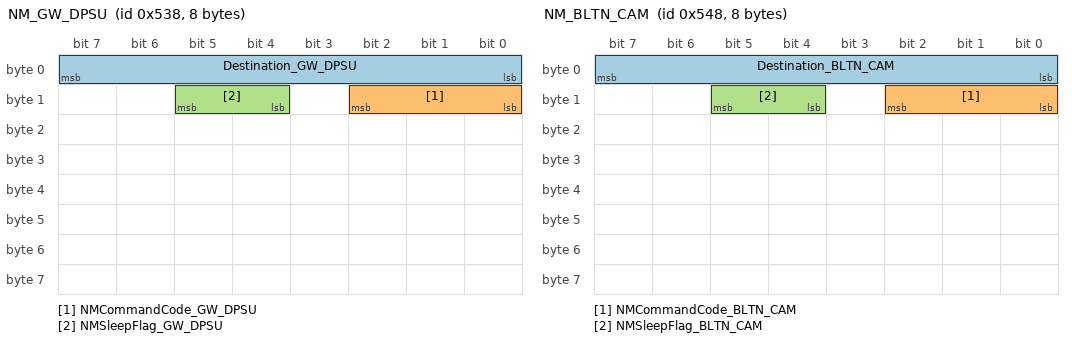
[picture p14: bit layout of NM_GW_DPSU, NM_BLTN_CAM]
BO_ 1336 NM_GW_DPSU: 8 GW_DPSU
 SG_ Destination_GW_DPSU : 0|8@1+ (1,0) [0|0] ""  WPC2,PSB,SHVU_RR,FCS,EMCU,SLB,GW_APSU,GW_DLBCU,ARS,RCM,CGW_CCU,GW_RLPSU,ATS,RLHV,SGU,PFSU,ALBCU,GW_RRPSU,DSAU,SWRC,SHVU_FR,RCS,BLTN_CAM,SCM,OHCL,RWPC,RRHV,WPC,HOD,ASAU
 SG_ NMCommandCode_GW_DPSU : 8|3@1+ (1,0) [0|0] ""  WPC2,PSB,SHVU_RR,FCS,EMCU,SLB,GW_APSU,GW_DLBCU,ARS,RCM,CGW_CCU,GW_RLPSU,ATS,RLHV,SGU,PFSU,ALBCU,GW_RRPSU,DSAU,SWRC,SHVU_FR,RCS,BLTN_CAM,SCM,OHCL,RWPC,RRHV,WPC,HOD,ASAU
 SG_ NMSleepFlag_GW_DPSU : 12|2@1+ (1,0) [0|0] ""  WPC2,PSB,SHVU_RR,FCS,EMCU,SLB,GW_APSU,GW_DLBCU,ARS,RCM,CGW_CCU,GW_RLPSU,ATS,RLHV,SGU,PFSU,ALBCU,GW_RRPSU,DSAU,SWRC,SHVU_FR,RCS,BLTN_CAM,SCM,OHCL,RWPC,RRHV,WPC,HOD,ASAU

BO_ 1352 NM_BLTN_CAM: 8 BLTN_CAM
 SG_ Destination_BLTN_CAM : 0|8@1+ (1,0) [0|0] ""  WPC2,PSB,SHVU_RR,FCS,EMCU,SLB,GW_APSU,GW_DLBCU,ARS,RCM,CGW_CCU,GW_RLPSU,ATS,RLHV,SGU,PFSU,ALBCU,GW_RRPSU,DSAU,SWRC,SHVU_FR,RCS,GW_DPSU,SCM,OHCL,RWPC,RRHV,WPC,HOD,ASAU
 SG_ NMCommandCode_BLTN_CAM : 8|3@1+ (1,0) [0|0] ""  WPC2,PSB,SHVU_RR,FCS,EMCU,SLB,GW_APSU,GW_DLBCU,ARS,RCM,CGW_CCU,GW_RLPSU,ATS,RLHV,SGU,PFSU,ALBCU,GW_RRPSU,DSAU,SWRC,SHVU_FR,RCS,GW_DPSU,SCM,OHCL,RWPC,RRHV,WPC,HOD,ASAU
 SG_ NMSleepFlag_BLTN_CAM : 12|2@1+ (1,0) [0|0] ""  WPC2,PSB,SHVU_RR,FCS,EMCU,SLB,GW_APSU,GW_DLBCU,ARS,RCM,CGW_CCU,GW_RLPSU,ATS,RLHV,SGU,PFSU,ALBCU,GW_RRPSU,DSAU,SWRC,SHVU_FR,RCS,GW_DPSU,SCM,OHCL,RWPC,RRHV,WPC,HOD,ASAU

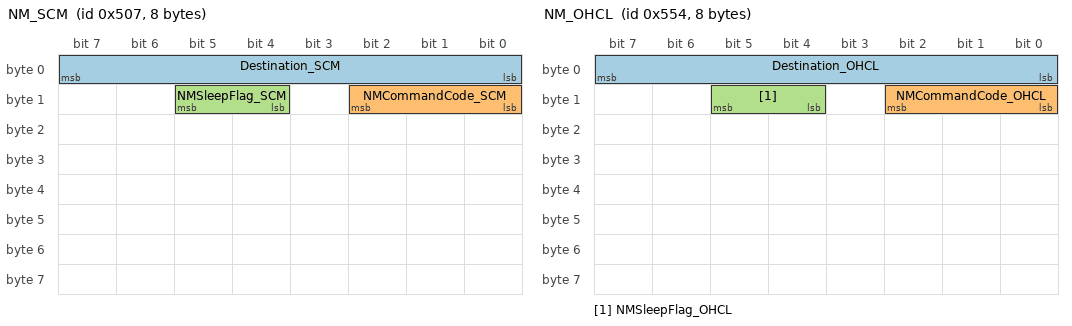
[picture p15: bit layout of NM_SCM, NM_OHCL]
BO_ 1287 NM_SCM: 8 SCM
 SG_ Destination_SCM : 0|8@1+ (1,0) [0|0] ""  WPC2,PSB,SHVU_RR,FCS,EMCU,SLB,GW_APSU,GW_DLBCU,ARS,RCM,CGW_CCU,GW_RLPSU,ATS,RLHV,SGU,PFSU,ALBCU,GW_RRPSU,DSAU,SWRC,SHVU_FR,RCS,GW_DPSU,BLTN_CAM,OHCL,RWPC,RRHV,WPC,HOD,ASAU
 SG_ NMCommandCode_SCM : 8|3@1+ (1,0) [0|0] ""  WPC2,PSB,SHVU_RR,FCS,EMCU,SLB,GW_APSU,GW_DLBCU,ARS,RCM,CGW_CCU,GW_RLPSU,ATS,RLHV,SGU,PFSU,ALBCU,GW_RRPSU,DSAU,SWRC,SHVU_FR,RCS,GW_DPSU,BLTN_CAM,OHCL,RWPC,RRHV,WPC,HOD,ASAU
 SG_ NMSleepFlag_SCM : 12|2@1+ (1,0) [0|0] ""  WPC2,PSB,SHVU_RR,FCS,EMCU,SLB,GW_APSU,GW_DLBCU,ARS,RCM,CGW_CCU,GW_RLPSU,ATS,RLHV,SGU,PFSU,ALBCU,GW_RRPSU,DSAU,SWRC,SHVU_FR,RCS,GW_DPSU,BLTN_CAM,OHCL,RWPC,RRHV,WPC,HOD,ASAU

BO_ 1364 NM_OHCL: 8 OHCL
 SG_ Destination_OHCL : 0|8@1+ (1,0) [0|0] ""  WPC2,PSB,SHVU_RR,FCS,EMCU,SLB,GW_APSU,GW_DLBCU,ARS,RCM,CGW_CCU,GW_RLPSU,ATS,RLHV,SGU,PFSU,ALBCU,GW_RRPSU,DSAU,SWRC,SHVU_FR,RCS,GW_DPSU,BLTN_CAM,SCM,RWPC,RRHV,WPC,HOD,ASAU
 SG_ NMCommandCode_OHCL : 8|3@1+ (1,0) [0|0] ""  WPC2,PSB,SHVU_RR,FCS,EMCU,SLB,GW_APSU,GW_DLBCU,ARS,RCM,CGW_CCU,GW_RLPSU,ATS,RLHV,SGU,PFSU,ALBCU,GW_RRPSU,DSAU,SWRC,SHVU_FR,RCS,GW_DPSU,BLTN_CAM,SCM,RWPC,RRHV,WPC,HOD,ASAU
 SG_ NMSleepFlag_OHCL : 12|2@1+ (1,0) [0|0] ""  WPC2,PSB,SHVU_RR,FCS,EMCU,SLB,GW_APSU,GW_DLBCU,ARS,RCM,CGW_CCU,GW_RLPSU,ATS,RLHV,SGU,PFSU,ALBCU,GW_RRPSU,DSAU,SWRC,SHVU_FR,RCS,GW_DPSU,BLTN_CAM,SCM,RWPC,RRHV,WPC,HOD,ASAU

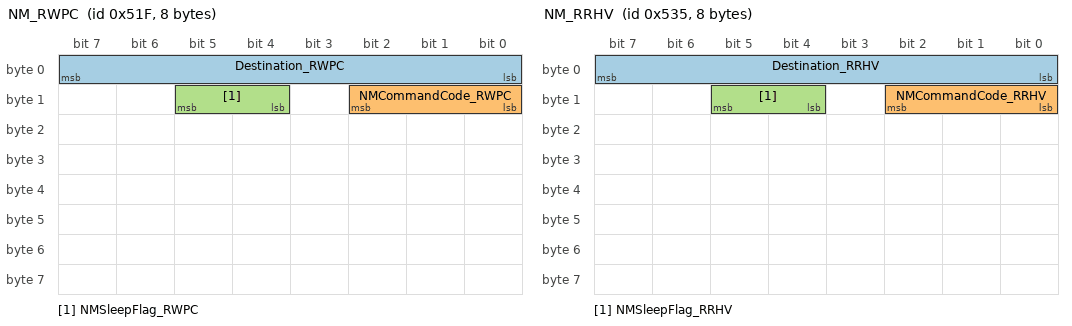
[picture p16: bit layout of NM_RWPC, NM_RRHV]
BO_ 1311 NM_RWPC: 8 RWPC
 SG_ Destination_RWPC : 0|8@1+ (1,0) [0|0] ""  WPC2,PSB,SHVU_RR,FCS,EMCU,SLB,GW_APSU,GW_DLBCU,ARS,RCM,CGW_CCU,GW_RLPSU,ATS,RLHV,SGU,PFSU,ALBCU,GW_RRPSU,DSAU,SWRC,SHVU_FR,RCS,GW_DPSU,BLTN_CAM,SCM,OHCL,RRHV,WPC,HOD,ASAU
 SG_ NMCommandCode_RWPC : 8|3@1+ (1,0) [0|0] ""  WPC2,PSB,SHVU_RR,FCS,EMCU,SLB,GW_APSU,GW_DLBCU,ARS,RCM,CGW_CCU,GW_RLPSU,ATS,RLHV,SGU,PFSU,ALBCU,GW_RRPSU,DSAU,SWRC,SHVU_FR,RCS,GW_DPSU,BLTN_CAM,SCM,OHCL,RRHV,WPC,HOD,ASAU
 SG_ NMSleepFlag_RWPC : 12|2@1+ (1,0) [0|0] ""  WPC2,PSB,SHVU_RR,FCS,EMCU,SLB,GW_APSU,GW_DLBCU,ARS,RCM,CGW_CCU,GW_RLPSU,ATS,RLHV,SGU,PFSU,ALBCU,GW_RRPSU,DSAU,SWRC,SHVU_FR,RCS,GW_DPSU,BLTN_CAM,SCM,OHCL,RRHV,WPC,HOD,ASAU

BO_ 1333 NM_RRHV: 8 RRHV
 SG_ Destination_RRHV : 0|8@1+ (1,0) [0|0] ""  WPC2,PSB,SHVU_RR,FCS,EMCU,SLB,GW_APSU,GW_DLBCU,ARS,RCM,CGW_CCU,GW_RLPSU,ATS,RLHV,SGU,PFSU,ALBCU,GW_RRPSU,DSAU,SWRC,SHVU_FR,RCS,GW_DPSU,BLTN_CAM,SCM,OHCL,RWPC,WPC,HOD,ASAU
 SG_ NMCommandCode_RRHV : 8|3@1+ (1,0) [0|0] ""  WPC2,PSB,SHVU_RR,FCS,EMCU,SLB,GW_APSU,GW_DLBCU,ARS,RCM,CGW_CCU,GW_RLPSU,ATS,RLHV,SGU,PFSU,ALBCU,GW_RRPSU,DSAU,SWRC,SHVU_FR,RCS,GW_DPSU,BLTN_CAM,SCM,OHCL,RWPC,WPC,HOD,ASAU
 SG_ NMSleepFlag_RRHV : 12|2@1+ (1,0) [0|0] ""  WPC2,PSB,SHVU_RR,FCS,EMCU,SLB,GW_APSU,GW_DLBCU,ARS,RCM,CGW_CCU,GW_RLPSU,ATS,RLHV,SGU,PFSU,ALBCU,GW_RRPSU,DSAU,SWRC,SHVU_FR,RCS,GW_DPSU,BLTN_CAM,SCM,OHCL,RWPC,WPC,HOD,ASAU

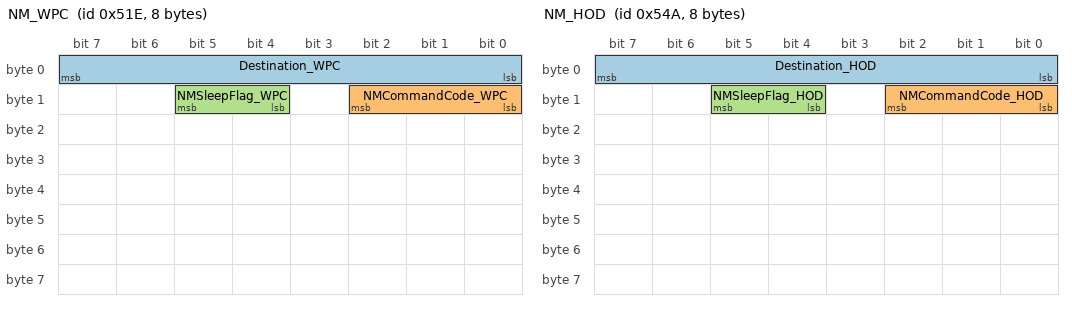
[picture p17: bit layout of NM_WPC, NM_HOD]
BO_ 1310 NM_WPC: 8 WPC
 SG_ Destination_WPC : 0|8@1+ (1,0) [0|0] ""  WPC2,PSB,SHVU_RR,FCS,EMCU,SLB,GW_APSU,GW_DLBCU,ARS,RCM,CGW_CCU,GW_RLPSU,ATS,RLHV,SGU,PFSU,ALBCU,GW_RRPSU,DSAU,SWRC,SHVU_FR,RCS,GW_DPSU,BLTN_CAM,SCM,OHCL,RWPC,RRHV,HOD,ASAU
 SG_ NMCommandCode_WPC : 8|3@1+ (1,0) [0|0] ""  WPC2,PSB,SHVU_RR,FCS,EMCU,SLB,GW_APSU,GW_DLBCU,ARS,RCM,CGW_CCU,GW_RLPSU,ATS,RLHV,SGU,PFSU,ALBCU,GW_RRPSU,DSAU,SWRC,SHVU_FR,RCS,GW_DPSU,BLTN_CAM,SCM,OHCL,RWPC,RRHV,HOD,ASAU
 SG_ NMSleepFlag_WPC : 12|2@1+ (1,0) [0|0] ""  WPC2,PSB,SHVU_RR,FCS,EMCU,SLB,GW_APSU,GW_DLBCU,ARS,RCM,CGW_CCU,GW_RLPSU,ATS,RLHV,SGU,PFSU,ALBCU,GW_RRPSU,DSAU,SWRC,SHVU_FR,RCS,GW_DPSU,BLTN_CAM,SCM,OHCL,RWPC,RRHV,HOD,ASAU

BO_ 1354 NM_HOD: 8 HOD
 SG_ Destination_HOD : 0|8@1+ (1,0) [0|0] ""  WPC2,PSB,SHVU_RR,FCS,EMCU,SLB,GW_APSU,GW_DLBCU,ARS,RCM,CGW_CCU,GW_RLPSU,ATS,RLHV,SGU,PFSU,ALBCU,GW_RRPSU,DSAU,SWRC,SHVU_FR,RCS,GW_DPSU,BLTN_CAM,SCM,OHCL,RWPC,RRHV,WPC,ASAU
 SG_ NMCommandCode_HOD : 8|3@1+ (1,0) [0|0] ""  WPC2,PSB,SHVU_RR,FCS,EMCU,SLB,GW_APSU,GW_DLBCU,ARS,RCM,CGW_CCU,GW_RLPSU,ATS,RLHV,SGU,PFSU,ALBCU,GW_RRPSU,DSAU,SWRC,SHVU_FR,RCS,GW_DPSU,BLTN_CAM,SCM,OHCL,RWPC,RRHV,WPC,ASAU
 SG_ NMSleepFlag_HOD : 12|2@1+ (1,0) [0|0] ""  WPC2,PSB,SHVU_RR,FCS,EMCU,SLB,GW_APSU,GW_DLBCU,ARS,RCM,CGW_CCU,GW_RLPSU,ATS,RLHV,SGU,PFSU,ALBCU,GW_RRPSU,DSAU,SWRC,SHVU_FR,RCS,GW_DPSU,BLTN_CAM,SCM,OHCL,RWPC,RRHV,WPC,ASAU

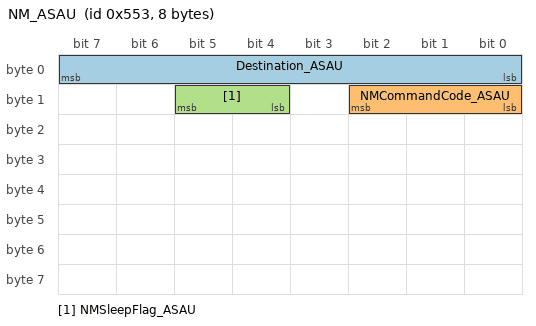
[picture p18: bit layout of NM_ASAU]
BO_ 1363 NM_ASAU: 8 ASAU
 SG_ Destination_ASAU : 0|8@1+ (1,0) [0|0] ""  WPC2,PSB,SHVU_RR,FCS,EMCU,SLB,GW_APSU,GW_DLBCU,ARS,RCM,CGW_CCU,GW_RLPSU,ATS,RLHV,SGU,PFSU,ALBCU,GW_RRPSU,DSAU,SWRC,SHVU_FR,RCS,GW_DPSU,BLTN_CAM,SCM,OHCL,RWPC,RRHV,WPC,HOD
 SG_ NMCommandCode_ASAU : 8|3@1+ (1,0) [0|0] ""  WPC2,PSB,SHVU_RR,FCS,EMCU,SLB,GW_APSU,GW_DLBCU,ARS,RCM,CGW_CCU,GW_RLPSU,ATS,RLHV,SGU,PFSU,ALBCU,GW_RRPSU,DSAU,SWRC,SHVU_FR,RCS,GW_DPSU,BLTN_CAM,SCM,OHCL,RWPC,RRHV,WPC,HOD
 SG_ NMSleepFlag_ASAU : 12|2@1+ (1,0) [0|0] ""  WPC2,PSB,SHVU_RR,FCS,EMCU,SLB,GW_APSU,GW_DLBCU,ARS,RCM,CGW_CCU,GW_RLPSU,ATS,RLHV,SGU,PFSU,ALBCU,GW_RRPSU,DSAU,SWRC,SHVU_FR,RCS,GW_DPSU,BLTN_CAM,SCM,OHCL,RWPC,RRHV,WPC,HOD

CM_ BO_ 2214658050 "[P] Periodic";
CM_ SG_ 2214658050 ENG_AccelPdlVal "ENG_AcceleratorPedalValue ##2G##EMS - EMS12 - PV_AV_CAN";
CM_ BO_ 2210462210 "[P] Periodic";
CM_ SG_ 2210462210 HCU_HevRdySta "HCU_HybridVehicleReadyStatus ##2G##HCU - HCU1 - CF_Hcu_HevRdy";
CM_ BO_ 1167 "[PE] Periodic and On Event";
CM_ SG_ 1167 ICU_BattAutoCutPreWrng "This is a warning signal before blocking the dark current of the ICU by the battery SOC.";
CM_ BO_ 1015 "[P] Periodic";
CM_ SG_ 1015 HU_MM_Altitude "Mapmatching Altitude";
CM_ SG_ 1015 HU_MM_Heading "Map matching heading";
CM_ BO_ 763 "[PE] Periodic and On Event";
CM_ SG_ 763 Hood_TypeOption "E-Hood_Option Type";
CM_ BO_ 1048 "[PE] Periodic and On Event";
CM_ SG_ 1048 DriveTypeOption "##2G## -  - C_DriveTypeOption,CF_Gway_DriveTypeOption";
CM_ SG_ 1048 ICU_PowerAutoCutModSta "##2G## -  - CF_Gway_ICUPowerAutoCutMode";
CM_ BO_ 1050 "[PE] Periodic and On Event";
CM_ SG_ 1050 Lamp_ExtrnlTailLmpOnReq "Lamp_ExternalTailLampOnRequest ##2G##BCM - BCMmsg19 - C_ExtTailOn";
CM_ BO_ 1002 "[PE] Periodic and On Event";
CM_ SG_ 1002 BLTN_CAM_HU_UI_Mode "Display control of Built-in Cam UI mode. This Signal for Ethernet Type Built-in Cam.";
CM_ SG_ 1002 BLTN_CAM_SD_Format_Op_State "BLTN_CAM SD card format operation status.";
CM_ SG_ 1002 BLTN_CAM_PEV_Recorded "This Signal is sent just after the park event recorded.";
CM_ SG_ 1002 BLTN_CAM_PEV_Count "This Signal is count of park event record.";
CM_ SG_ 1002 BLTN_CAM_Ind_Req "This Signal is for HU Display Built-in Cam Indicator.";
CM_ SG_ 1002 BLTN_CAM_LVDS_Mode_State "This Signal is for LVDS output status";
CM_ SG_ 1002 BLTN_CAM_PrkOp_Termiate_Info "0x0:Default/0x01: Park operation terminated earlier than user set because of Bat. SoC/0x2 : Park operation terminated earlier than user set because of SD Card Problem /0x3 : Park operation terminated earlier than user set because of Built-in Cam internal Error /0x04~0x6:Reserved/0x07 : Park operation terminate on time which user se";
CM_ SG_ 1002 BLTN_CAM_DEV_Recorded "This Signal is sent just after the drive event recorded.";
CM_ SG_ 1002 BLTN_CAM_DEV_Count "This Signal is count of drive event record.";
CM_ SG_ 1002 BLTN_CAM_Display "Display control of Built-in Cam UI mode. This Signal for CAN Type Built-in Cam.(with Standard 5th Wide AVNT)";
CM_ SG_ 1002 BLTN_CAM_WiFi_State "BLTN_CAM WiFi Stattus";
CM_ BO_ 1041 "[PE] Periodic and On Event";
CM_ SG_ 1041 ICU_MtGearPosRSta "##2G## -  - C_InhibitRMT,CF_Gway_InhibitRMT";
CM_ SG_ 1041 Warn_DrvDrSwSta "DoorLock_DriverDoorSwitchStatus ##2G## -  - C_DrvDrSw,CF_Gway_DrvDrSw,Warn_DrvDrSwSta";
CM_ SG_ 1041 Warn_AsstDrSwSta "Warn_AssistDoorSwitchStatus ##2G## -  - C_AstDrSw,CF_Gway_AstDrSw,Warn_AsstDrSwSta";
CM_ SG_ 1041 Warn_HoodSwSta "Warn_HoodSwitchStatus ##2G## -  - C_HoodSw,CF_Gway_HoodSw";
CM_ SG_ 1041 Warn_RrLftDrSwSta "Warn_RearLeftDoorSwitchStatus ##2G## -  - C_RLDrSw,CF_Gway_RLDrSw,Warn_RrLftDrSwSta";
CM_ SG_ 1041 Warn_RrRtDrSwSta "Warn_RearRightDoorSwitchStatus ##2G## -  - C_RRDrSw,CF_Gway_RRDrSw,Warn_RrRtDrSwSta";
CM_ BO_ 992 "[PE] Periodic and On Event";
CM_ SG_ 992 BAlarm_BglrAlrmCurrentSta "BAlarm_BuglarAlarmCurrentStatus ##2G##BCM - BCMmsg17 - C_BAlarmState";
CM_ BO_ 1040 "[PE] Periodic and On Event";
CM_ SG_ 1040 ICU_BS2SoC "This signal is battery State of Charge as calculated by battery sensor. ##2G## -  - BS2_SOC,Batt_SoC";
CM_ BO_ 1043 "[PE] Periodic and On Event";
CM_ SG_ 1043 IntLamp_InlTailLmpSta "IntLamp_InternalTailLampStatus ##2G## -  - C_IntTailAct,CF_Gway_IntTailAct";
CM_ SG_ 1043 Lamp_TrnSigLmpLftOnReq "Lamp_TurnSignalLampLeftOnRequest ##2G## -  - Lamp_TsigLmpFrtLftOnReq";
CM_ SG_ 1043 Lamp_TrnSigLmpRtOnReq "Lamp_TurnSignalLampRightOnRequest ##2G## -  - Lamp_TSigLmpRtLftOnReq";
CM_ BO_ 1044 "[PE] Periodic and On Event";
CM_ SG_ 1044 Trunk_TrnkTlgtSwSta "Trunk_TrunkTailgateSwitchStatus ##2G## -  - C_TrunkTgSw,CF_Gway_TrunkTgSw,Trunk_TrnkTlgtSwSta";
CM_ SG_ 1044 C_CrashUnlockState "Crash Unlock Active State";
CM_ BO_ 1186 "[EC] On Event and On Change";
CM_ SG_ 1186 C_PreCrankReq "Command for B-CAN wake up signal
(Need to send this signal before other remote commands)";
CM_ BO_ 1058 "[PE] Periodic and On Event";
CM_ SG_ 1058 Wiper_PrkngPosSta "Wiper_ParkingPositionStatus ##2G##BCM - BCMmsg22 - C_WiperParkPosition";
CM_ SG_ 1058 Wiper_RainSnsrSta "Wiper_RainSensorStatus ##2G##BCM - BCMmsg24 - C_RainSnsState";
CM_ BO_ 1195 "[EC] On Event and On Change";
CM_ SG_ 1195 CF_AVN_CluUSMReset "Request to reset all USM service";
CM_ BO_ 858 "[PE] Periodic and On Event";
CM_ SG_ 858 AST_CrashUnlockCmd "AssistCrashUnlockCommand";
CM_ SG_ 858 Warn_AsstDrSwSta_SBCM "Warn_AssistDoorSwitchStatus ##2G## -  - C_AstDrSw,CF_Gway_AstDrSw,Warn_AsstDrSwSta";
CM_ BO_ 977 "[PE] Periodic and On Event";
CM_ SG_ 977 SMK_TrmnlCtrlGrpStaBDC "SMK_TerminalControlStatus";
CM_ SG_ 977 SMK_TrmnlCtrlGrpStaBDCEV "SMK_TerminalControlStatus";
CM_ SG_ 977 SMK_TrmnlCtrlStaBDCEV "SMK_TerminalControlStatus";
CM_ BO_ 862 "[PE] Periodic and On Event";
CM_ SG_ 862 RL_CrashUnlockCmd "Rear Lefr Crash Unlock Command";
CM_ SG_ 862 Warn_RrLftDrSwSta_SBCM "Warn_RearLeftDoorSwitchStatus ##2G## -  - C_RLDrSw,CF_Gway_RLDrSw,Warn_RrLftDrSwSta";
CM_ BO_ 983 "[PE] Periodic and On Event";
CM_ SG_ 983 BLTN_CAM_SWVerMajor "First Word(ASCII) in Built-in Cam S/W Ver";
CM_ SG_ 983 BLTN_CAM_SWVerMinor2 "Minor2 in Built-in Cam S/W Ver";
CM_ SG_ 983 BLTN_CAM_SWVerMinor3 "Minor3 in Built-in Cam S/W Ver";
CM_ SG_ 983 BLTN_CAM_SD_Card_Manufacturer "0x0(SD Card not found), 0x1(Micron-Genuine part), 0x2~0x5(Reserved), 0x6(Unknown), 0x7(Invalid)";
CM_ SG_ 983 BLTN_CAM_SD_Card_Cap_Class "0x0(SD Card not found), 0x1(64Gbyte Class), 0x2(128Gbyte Class), 0x3(256Gbyte Class), 0x4(512Gbyte Class), 0x5(1Tbyte Class), 0x6(2Tbyte Class), 0x7(Invalid)";
CM_ SG_ 983 BLTN_CAM_SWVerMinor1 "Minor1 in Built-in Cam S/W Ver";
CM_ BO_ 2160080132 "[P] Periodic";
CM_ SG_ 2160080132 VCU_GearPosStaDisp "VCU_GearPositionStatusDisp";
CM_ BO_ 721 "[P] Periodic";
CM_ SG_ 721 HU_DR_Altitude "range [-400,10000]";
CM_ BO_ 722 "[P] Periodic";
CM_ SG_ 722 HU_DR_Latitude "1sc(semi-cicle)= pi rad=180  /   unit : 2^-31sc  /  range [-1/2~1/2] sc";
CM_ SG_ 722 HU_DR_Longitude "1sc(semi-circle)=pi rad=180 / unit:2^-31sc / range:[-1, 1]sc";
CM_ BO_ 723 "[P] Periodic";
CM_ SG_ 723 HU_DR_Heading "1sc(semi-circle)=pi rad=180 / unit=2^-15sc / range:[0,2]SC";
CM_ BO_ 2160080129 "[P] Periodic";
CM_ SG_ 2160080129 VCU_EvDrvRdySta "VCU_EvDriveReadyStatus ##2G##VCU - VCU1 - CF_Vcu_EvRdy";
CM_ SG_ 2160080129 VCU_GearPosSta "VCU_GearPositionStatus ##2G##VCU - VCU1 - CF_Vcu_GarSelDisp";
CM_ SG_ 2160080129 VCU_AccPedDepVal "VCU_AcceleratorPedalDepthValue ##2G##VCU - VCU1 - CR_Vcu_AccPedDep_Pc";
CM_ BO_ 1079 "[PE] Periodic and On Event";
CM_ SG_ 1079 CTM_TrailerAct "This signal is used for control the Trailer Act function.";
CM_ BO_ 2164278529 "[P] Periodic";
CM_ SG_ 2164278529 HTCU_GearSlctrDis "HTCU_GearSelectDisplay";
CM_ BO_ 1076 "[PE] Periodic and On Event";
CM_ SG_ 1076 IAU_ProfileIDRVal "This signal Indicate the Current detected Profile ID by IAU.";
CM_ BO_ 1301 "NM Message";
CM_ SG_ 1301 Destination_WPC2 "NM Source Node Identifier";
CM_ SG_ 1301 NMCommandCode_WPC2 "NM Control Bit Vector - Repeat Message Request";
CM_ SG_ 1301 NMSleepFlag_WPC2 "NM Control Bit Vector - NM Coordinator ID";
CM_ BO_ 1345 "NM Message";
CM_ SG_ 1345 Destination_PSB "NM Source Node Identifier";
CM_ SG_ 1345 NMCommandCode_PSB "NM Control Bit Vector - Repeat Message Request";
CM_ SG_ 1345 NMSleepFlag_PSB "NM Control Bit Vector - NM Coordinator ID";
CM_ BO_ 1323 "NM Message";
CM_ SG_ 1323 Destination_SHVU_RR "NM Source Node Identifier";
CM_ SG_ 1323 NMCommandCode_SHVU_RR "NM Control Bit Vector - Repeat Message Request";
CM_ SG_ 1323 NMSleepFlag_SHVU_RR "NM Control Bit Vector - NM Coordinator ID";
CM_ BO_ 1313 "NM Message";
CM_ SG_ 1313 Destination_FCS "NM Source Node Identifier";
CM_ SG_ 1313 NMCommandCode_FCS "NM Control Bit Vector - Repeat Message Request";
CM_ SG_ 1313 NMSleepFlag_FCS "NM Control Bit Vector - NM Coordinator ID";
CM_ BO_ 1297 "NM Message";
CM_ SG_ 1297 Destination_EMCU "NM Source Node Identifier";
CM_ SG_ 1297 NMCommandCode_EMCU "NM Control Bit Vector - Repeat Message Request";
CM_ SG_ 1297 NMSleepFlag_EMCU "NM Control Bit Vector - NM Coordinator ID";
CM_ BO_ 1307 "NM Message";
CM_ SG_ 1307 Destination_SLB "NM Source Node Identifier";
CM_ SG_ 1307 NMCommandCode_SLB "NM Control Bit Vector - Repeat Message Request";
CM_ SG_ 1307 NMSleepFlag_SLB "NM Control Bit Vector - NM Coordinator ID";
CM_ BO_ 1329 "NM Message";
CM_ SG_ 1329 Destination_GW_APSU "NM Source Node Identifier";
CM_ SG_ 1329 NMCommandCode_GW_APSU "NM Control Bit Vector - Repeat Message Request";
CM_ SG_ 1329 NMSleepFlag_GW_APSU "NM Control Bit Vector - NM Coordinator ID";
CM_ BO_ 1344 "NM Message";
CM_ SG_ 1344 Destination_GW_DLBCU "NM Source Node Identifier";
CM_ SG_ 1344 NMCommandCode_GW_DLBCU "NM Control Bit Vector - Repeat Message Request";
CM_ SG_ 1344 NMSleepFlag_GW_DLBCU "NM Control Bit Vector - NM Coordinator ID";
CM_ BO_ 1290 "NM Message";
CM_ SG_ 1290 Destination_ARS "NM Source Node Identifier";
CM_ SG_ 1290 NMCommandCode_ARS "NM Control Bit Vector - Repeat Message Request";
CM_ SG_ 1290 NMSleepFlag_ARS "NM Control Bit Vector - NM Coordinator ID";
CM_ BO_ 1341 "NM Message";
CM_ SG_ 1341 Destination_RCM "NM Source Node Identifier";
CM_ SG_ 1341 NMCommandCode_RCM "NM Control Bit Vector - Repeat Message Request";
CM_ SG_ 1341 NMSleepFlag_RCM "NM Control Bit Vector - NM Coordinator ID";
CM_ BO_ 1392 "NM Message";
CM_ SG_ 1392 Destination_CGW_CCU "NM Source Node Identifier";
CM_ SG_ 1392 NMCommandCode_CGW_CCU "NM Control Bit Vector - Repeat Message Request";
CM_ SG_ 1392 NMSleepFlag_CGW_CCU "NM Control Bit Vector - NM Coordinator ID";
CM_ BO_ 1308 "NM Message";
CM_ SG_ 1308 Destination_GW_RLPSU "NM Source Node Identifier";
CM_ SG_ 1308 NMCommandCode_GW_RLPSU "NM Control Bit Vector - Repeat Message Request";
CM_ SG_ 1308 NMSleepFlag_GW_RLPSU "NM Control Bit Vector - NM Coordinator ID";
CM_ BO_ 1360 "NM Message";
CM_ SG_ 1360 Destination_ATS "NM Source Node Identifier";
CM_ SG_ 1360 NMCommandCode_ATS "NM Control Bit Vector - Repeat Message Request";
CM_ SG_ 1360 NMSleepFlag_ATS "NM Control Bit Vector - NM Coordinator ID";
CM_ BO_ 1332 "NM Message";
CM_ SG_ 1332 Destination_RLHV "NM Source Node Identifier";
CM_ SG_ 1332 NMCommandCode_RLHV "NM Control Bit Vector - Repeat Message Request";
CM_ SG_ 1332 NMSleepFlag_RLHV "NM Control Bit Vector - NM Coordinator ID";
CM_ BO_ 1342 "NM Message";
CM_ SG_ 1342 Destination_SGU "NM Source Node Identifier";
CM_ SG_ 1342 NMCommandCode_SGU "NM Control Bit Vector - Repeat Message Request";
CM_ SG_ 1342 NMSleepFlag_SGU "NM Control Bit Vector - NM Coordinator ID";
CM_ BO_ 1325 "NM Message";
CM_ SG_ 1325 Destination_PFSU "NM Source Node Identifier";
CM_ SG_ 1325 NMCommandCode_PFSU "NM Control Bit Vector - Repeat Message Request";
CM_ SG_ 1325 NMSleepFlag_PFSU "NM Control Bit Vector - NM Coordinator ID";
CM_ BO_ 1348 "NM Message";
CM_ SG_ 1348 Destination_ALBCU "NM Source Node Identifier";
CM_ SG_ 1348 NMCommandCode_ALBCU "NM Control Bit Vector - Repeat Message Request";
CM_ SG_ 1348 NMSleepFlag_ALBCU "NM Control Bit Vector - NM Coordinator ID";
CM_ BO_ 1309 "NM Message";
CM_ SG_ 1309 Destination_GW_RRPSU "NM Source Node Identifier";
CM_ SG_ 1309 NMCommandCode_GW_RRPSU "NM Control Bit Vector - Repeat Message Request";
CM_ SG_ 1309 NMSleepFlag_GW_RRPSU "NM Control Bit Vector - NM Coordinator ID";
CM_ BO_ 1369 "NM Message";
CM_ SG_ 1369 Destination_DSAU "NM Source Node Identifier";
CM_ SG_ 1369 NMCommandCode_DSAU "NM Control Bit Vector - Repeat Message Request";
CM_ SG_ 1369 NMSleepFlag_DSAU "NM Control Bit Vector - NM Coordinator ID";
CM_ BO_ 1288 "NM Message";
CM_ SG_ 1288 Destination_SWRC "NM Source Node Identifier";
CM_ SG_ 1288 NMCommandCode_SWRC "NM Control Bit Vector - Repeat Message Request";
CM_ SG_ 1288 NMSleepFlag_SWRC "NM Control Bit Vector - NM Coordinator ID";
CM_ BO_ 1322 "NM Message";
CM_ SG_ 1322 Destination_SHVU_FR "NM Source Node Identifier";
CM_ SG_ 1322 NMCommandCode_SHVU_FR "NM Control Bit Vector - Repeat Message Request";
CM_ SG_ 1322 NMSleepFlag_SHVU_FR "NM Control Bit Vector - NM Coordinator ID";
CM_ BO_ 1350 "NM Message";
CM_ SG_ 1350 Destination_RCS "NM Source Node Identifier";
CM_ SG_ 1350 NMCommandCode_RCS "NM Control Bit Vector - Repeat Message Request";
CM_ SG_ 1350 NMSleepFlag_RCS "NM Control Bit Vector - NM Coordinator ID";
CM_ BO_ 1336 "NM Message";
CM_ SG_ 1336 Destination_GW_DPSU "NM Source Node Identifier";
CM_ SG_ 1336 NMCommandCode_GW_DPSU "NM Control Bit Vector - Repeat Message Request";
CM_ SG_ 1336 NMSleepFlag_GW_DPSU "NM Control Bit Vector - NM Coordinator ID";
CM_ BO_ 1352 "NM Message";
CM_ SG_ 1352 Destination_BLTN_CAM "NM Source Node Identifier";
CM_ SG_ 1352 NMCommandCode_BLTN_CAM "NM Control Bit Vector - Repeat Message Request";
CM_ SG_ 1352 NMSleepFlag_BLTN_CAM "NM Control Bit Vector - NM Coordinator ID";
CM_ BO_ 1287 "NM Message";
CM_ SG_ 1287 Destination_SCM "NM Source Node Identifier";
CM_ SG_ 1287 NMCommandCode_SCM "NM Control Bit Vector - Repeat Message Request";
CM_ SG_ 1287 NMSleepFlag_SCM "NM Control Bit Vector - NM Coordinator ID";
CM_ BO_ 1364 "NM Message";
CM_ SG_ 1364 Destination_OHCL "NM Source Node Identifier";
CM_ SG_ 1364 NMCommandCode_OHCL "NM Control Bit Vector - Repeat Message Request";
CM_ SG_ 1364 NMSleepFlag_OHCL "NM Control Bit Vector - NM Coordinator ID";
CM_ BO_ 1311 "NM Message";
CM_ SG_ 1311 Destination_RWPC "NM Source Node Identifier";
CM_ SG_ 1311 NMCommandCode_RWPC "NM Control Bit Vector - Repeat Message Request";
CM_ SG_ 1311 NMSleepFlag_RWPC "NM Control Bit Vector - NM Coordinator ID";
CM_ BO_ 1333 "NM Message";
CM_ SG_ 1333 Destination_RRHV "NM Source Node Identifier";
CM_ SG_ 1333 NMCommandCode_RRHV "NM Control Bit Vector - Repeat Message Request";
CM_ SG_ 1333 NMSleepFlag_RRHV "NM Control Bit Vector - NM Coordinator ID";
CM_ BO_ 1310 "NM Message";
CM_ SG_ 1310 Destination_WPC "NM Source Node Identifier";
CM_ SG_ 1310 NMCommandCode_WPC "NM Control Bit Vector - Repeat Message Request";
CM_ SG_ 1310 NMSleepFlag_WPC "NM Control Bit Vector - NM Coordinator ID";
CM_ BO_ 1354 "NM Message";
CM_ SG_ 1354 Destination_HOD "NM Source Node Identifier";
CM_ SG_ 1354 NMCommandCode_HOD "NM Control Bit Vector - Repeat Message Request";
CM_ SG_ 1354 NMSleepFlag_HOD "NM Control Bit Vector - NM Coordinator ID";
CM_ BO_ 1363 "NM Message";
CM_ SG_ 1363 Destination_ASAU "NM Source Node Identifier";
CM_ SG_ 1363 NMCommandCode_ASAU "NM Control Bit Vector - Repeat Message Request";
CM_ SG_ 1363 NMSleepFlag_ASAU "NM Control Bit Vector - NM Coordinator ID";
BA_DEF_ BO_  "DiagState" ENUM  "No","Yes";
BA_DEF_ BO_  "DiagResponse" ENUM  "No","Yes";
BA_DEF_ BO_  "DiagRequest" ENUM  "No","Yes";
BA_DEF_ BO_  "TpMessage" ENUM  "No","Yes";
BA_DEF_ BO_  "UsrMsgIDSforwardDeviation" INT 0 100;
BA_DEF_ BO_  "UsrMsgIDSbackwardDeviation" INT 50 1000;
BA_DEF_ BO_  "GenMsgCycleTime" INT 0 2000;
BA_DEF_ BO_  "GenMsgStartDelayTime" INT 0 2000;
BA_DEF_ BO_  "GenMsgSendType" ENUM  "Cyclic","NoMsgSendType";
BA_DEF_ BO_  "GenMsgCycleTimeFast" INT 0 500;
BA_DEF_ BO_  "GenMsgDelayTime" INT 0 20;
BA_DEF_ BO_  "GenMsgFastOnStart" INT 0 0;
BA_DEF_ BO_  "GenMsgILSupport" ENUM  "No","Yes";
BA_DEF_ BO_  "GenMsgNrOfRepetition" INT 0 3;
BA_DEF_ BO_  "NmMessage" ENUM  "No","Yes";
BA_DEF_ BO_  "NWM-Botschaft" ENUM  "No","Yes";
BA_DEF_ BO_  "TpTxIndex" INT 0 65535;
BA_DEF_ BO_  "VFrameFormat" ENUM  "StandardCAN","ExtendedCAN","reserved","reserved","reserved","reserved","reserved","reserved","reserved","reserved","reserved","reserved","reserved","reserved","StandardCAN_FD","ExtendedCAN_FD";
BA_DEF_ SG_  "UserSigValidity" ENUM  "B+","ACC","IG","IG1","IG2","IG3","IG1 or IG2","IG1 or IG3","Undef";
BA_DEF_ SG_  "UsrSigPurpose" ENUM  "Undef","FN","DIAG","DIAG(Req)","DIAG(Res)","DIAG(Phy)","DEV","CCP(Req)","CCP(Res)","NM","TP";
BA_DEF_ SG_  "GenSigStartValue" INT 0 1215752192;
BA_DEF_ SG_  "NetworkRequest" ENUM  "Yes","No";
BA_DEF_ SG_  "NetworkRequestHoldingTime" INT 0 65535;
BA_DEF_ SG_  "Description" STRING ;
BA_DEF_ SG_  "Version" STRING ;
BA_DEF_ SG_  "GenSigEnvVarType" ENUM  "Int","Float","Undef";
BA_DEF_ SG_  "GenSigSendType" ENUM  "Cyclic","OnWrite","OnWriteWithRepetition","OnChange","OnChangeWithRepetition","IfActive","IfActiveWithRepetition","NoSigSendType","OnChangeAndIfActive","OnChangeAndIfActiveWithRepetition";
BA_DEF_ SG_  "GwSigLatencyTime" INT 0 65536;
BA_DEF_ SG_  "GwSigMissingSourceType" ENUM  "Undef","OldValue","DefaultValue","InitialValue";
BA_DEF_ SG_  "NWM-WakeupAllowed" ENUM  "<n.a.>";
BA_DEF_ SG_  "RoutingFactor" INT 1 1215752192;
BA_DEF_REL_ BU_SG_REL_  "GenSigTimeoutTime" INT 0 7000;
BA_DEF_DEF_  "DiagState" "No";
BA_DEF_DEF_  "DiagResponse" "No";
BA_DEF_DEF_  "DiagRequest" "No";
BA_DEF_DEF_  "TpMessage" "No";
BA_DEF_DEF_  "UsrMsgIDSforwardDeviation" 10;
BA_DEF_DEF_  "UsrMsgIDSbackwardDeviation" 100;
BA_DEF_DEF_  "GenMsgCycleTime" 200;
BA_DEF_DEF_  "GenMsgStartDelayTime" 0;
BA_DEF_DEF_  "GenMsgSendType" "NoMsgSendType";
BA_DEF_DEF_  "GenMsgCycleTimeFast" 40;
BA_DEF_DEF_  "GenMsgDelayTime" 20;
BA_DEF_DEF_  "GenMsgFastOnStart" 0;
BA_DEF_DEF_  "GenMsgILSupport" "Yes";
BA_DEF_DEF_  "GenMsgNrOfRepetition" 3;
BA_DEF_DEF_  "NmMessage" "No";
BA_DEF_DEF_  "NWM-Botschaft" "No";
BA_DEF_DEF_  "TpTxIndex" 0;
BA_DEF_DEF_  "VFrameFormat" "StandardCAN";
BA_DEF_DEF_  "UserSigValidity" "IG";
BA_DEF_DEF_  "UsrSigPurpose" "FN";
BA_DEF_DEF_  "GenSigStartValue" 0;
BA_DEF_DEF_  "NetworkRequest" "No";
BA_DEF_DEF_  "NetworkRequestHoldingTime" 0;
BA_DEF_DEF_  "Description" "";
BA_DEF_DEF_  "Version" "";
BA_DEF_DEF_  "GenSigEnvVarType" "Undef";
BA_DEF_DEF_  "GenSigSendType" "NoSigSendType";
BA_DEF_DEF_  "GwSigLatencyTime" 40;
BA_DEF_DEF_  "GwSigMissingSourceType" "Undef";
BA_DEF_DEF_  "NWM-WakeupAllowed" "<n.a.>";
BA_DEF_DEF_  "RoutingFactor" 1;
BA_DEF_DEF_REL_ "GenSigTimeoutTime" 500;
BA_ "VFrameFormat" BO_ 2214658050 1;
BA_ "GenMsgNrOfRepetition" BO_ 2214658050 0;
BA_ "GenMsgCycleTimeFast" BO_ 2214658050 0;
BA_ "GenMsgCycleTime" BO_ 2214658050 50;
BA_ "GenMsgSendType" BO_ 2214658050 0;
BA_ "VFrameFormat" BO_ 2210462210 1;
BA_ "GenMsgNrOfRepetition" BO_ 2210462210 0;
BA_ "GenMsgCycleTimeFast" BO_ 2210462210 0;
BA_ "GenMsgCycleTime" BO_ 2210462210 50;
BA_ "GenMsgSendType" BO_ 2210462210 0;
BA_ "GenMsgCycleTime" BO_ 1167 1000;
BA_ "GenMsgSendType" BO_ 1167 0;
BA_ "GenMsgNrOfRepetition" BO_ 1015 0;
BA_ "GenMsgCycleTimeFast" BO_ 1015 0;
BA_ "GenMsgCycleTime" BO_ 1015 1000;
BA_ "GenMsgSendType" BO_ 1015 0;
BA_ "GenMsgSendType" BO_ 763 0;
BA_ "GenMsgSendType" BO_ 1048 0;
BA_ "GenMsgSendType" BO_ 1050 0;
BA_ "GenMsgSendType" BO_ 1002 0;
BA_ "GenMsgSendType" BO_ 1041 0;
BA_ "GenMsgSendType" BO_ 992 0;
BA_ "GenMsgSendType" BO_ 1040 0;
BA_ "GenMsgSendType" BO_ 1043 0;
BA_ "GenMsgSendType" BO_ 1044 0;
BA_ "GenMsgCycleTime" BO_ 1186 0;
BA_ "GenMsgSendType" BO_ 1058 0;
BA_ "GenMsgCycleTime" BO_ 1195 0;
BA_ "GenMsgSendType" BO_ 858 0;
BA_ "GenMsgSendType" BO_ 977 0;
BA_ "GenMsgSendType" BO_ 862 0;
BA_ "GenMsgSendType" BO_ 983 0;
BA_ "VFrameFormat" BO_ 2160080132 1;
BA_ "GenMsgNrOfRepetition" BO_ 2160080132 0;
BA_ "GenMsgCycleTimeFast" BO_ 2160080132 0;
BA_ "GenMsgCycleTime" BO_ 2160080132 50;
BA_ "GenMsgSendType" BO_ 2160080132 0;
BA_ "GenMsgNrOfRepetition" BO_ 721 0;
BA_ "GenMsgCycleTimeFast" BO_ 721 0;
BA_ "GenMsgCycleTime" BO_ 721 100;
BA_ "GenMsgSendType" BO_ 721 0;
BA_ "GenMsgNrOfRepetition" BO_ 722 0;
BA_ "GenMsgCycleTimeFast" BO_ 722 0;
BA_ "GenMsgCycleTime" BO_ 722 100;
BA_ "GenMsgSendType" BO_ 722 0;
BA_ "GenMsgNrOfRepetition" BO_ 723 0;
BA_ "GenMsgCycleTimeFast" BO_ 723 0;
BA_ "GenMsgCycleTime" BO_ 723 100;
BA_ "GenMsgSendType" BO_ 723 0;
BA_ "VFrameFormat" BO_ 2160080129 1;
BA_ "GenMsgNrOfRepetition" BO_ 2160080129 0;
BA_ "GenMsgCycleTimeFast" BO_ 2160080129 0;
BA_ "GenMsgCycleTime" BO_ 2160080129 50;
BA_ "GenMsgSendType" BO_ 2160080129 0;
BA_ "GenMsgSendType" BO_ 1079 0;
BA_ "VFrameFormat" BO_ 2164278529 1;
BA_ "GenMsgNrOfRepetition" BO_ 2164278529 0;
BA_ "GenMsgCycleTimeFast" BO_ 2164278529 0;
BA_ "GenMsgCycleTime" BO_ 2164278529 50;
BA_ "GenMsgSendType" BO_ 2164278529 0;
BA_ "GenMsgSendType" BO_ 1076 0;
BA_ "NWM-Botschaft" BO_ 1301 1;
BA_ "GenMsgILSupport" BO_ 1301 0;
BA_ "NmMessage" BO_ 1301 1;
BA_ "NWM-Botschaft" BO_ 1345 1;
BA_ "GenMsgILSupport" BO_ 1345 0;
BA_ "NmMessage" BO_ 1345 1;
BA_ "NWM-Botschaft" BO_ 1323 1;
BA_ "GenMsgILSupport" BO_ 1323 0;
BA_ "NmMessage" BO_ 1323 1;
BA_ "NWM-Botschaft" BO_ 1313 1;
BA_ "GenMsgILSupport" BO_ 1313 0;
BA_ "NmMessage" BO_ 1313 1;
BA_ "NWM-Botschaft" BO_ 1297 1;
BA_ "GenMsgILSupport" BO_ 1297 0;
BA_ "NmMessage" BO_ 1297 1;
BA_ "NWM-Botschaft" BO_ 1307 1;
BA_ "GenMsgILSupport" BO_ 1307 0;
BA_ "NmMessage" BO_ 1307 1;
BA_ "NWM-Botschaft" BO_ 1329 1;
BA_ "GenMsgILSupport" BO_ 1329 0;
BA_ "NmMessage" BO_ 1329 1;
BA_ "NWM-Botschaft" BO_ 1344 1;
BA_ "GenMsgILSupport" BO_ 1344 0;
BA_ "NmMessage" BO_ 1344 1;
BA_ "NWM-Botschaft" BO_ 1290 1;
BA_ "GenMsgILSupport" BO_ 1290 0;
BA_ "NmMessage" BO_ 1290 1;
BA_ "NWM-Botschaft" BO_ 1341 1;
BA_ "GenMsgILSupport" BO_ 1341 0;
BA_ "NmMessage" BO_ 1341 1;
BA_ "NWM-Botschaft" BO_ 1392 1;
BA_ "GenMsgILSupport" BO_ 1392 0;
BA_ "NmMessage" BO_ 1392 1;
BA_ "NWM-Botschaft" BO_ 1308 1;
BA_ "GenMsgILSupport" BO_ 1308 0;
BA_ "NmMessage" BO_ 1308 1;
BA_ "NWM-Botschaft" BO_ 1360 1;
BA_ "GenMsgILSupport" BO_ 1360 0;
BA_ "NmMessage" BO_ 1360 1;
BA_ "NWM-Botschaft" BO_ 1332 1;
BA_ "GenMsgILSupport" BO_ 1332 0;
BA_ "NmMessage" BO_ 1332 1;
BA_ "NWM-Botschaft" BO_ 1342 1;
BA_ "GenMsgILSupport" BO_ 1342 0;
BA_ "NmMessage" BO_ 1342 1;
BA_ "NWM-Botschaft" BO_ 1325 1;
BA_ "GenMsgILSupport" BO_ 1325 0;
BA_ "NmMessage" BO_ 1325 1;
BA_ "NWM-Botschaft" BO_ 1348 1;
BA_ "GenMsgILSupport" BO_ 1348 0;
BA_ "NmMessage" BO_ 1348 1;
BA_ "NWM-Botschaft" BO_ 1309 1;
BA_ "GenMsgILSupport" BO_ 1309 0;
BA_ "NmMessage" BO_ 1309 1;
BA_ "NWM-Botschaft" BO_ 1369 1;
BA_ "GenMsgILSupport" BO_ 1369 0;
BA_ "NmMessage" BO_ 1369 1;
BA_ "NWM-Botschaft" BO_ 1288 1;
BA_ "GenMsgILSupport" BO_ 1288 0;
BA_ "NmMessage" BO_ 1288 1;
BA_ "NWM-Botschaft" BO_ 1322 1;
BA_ "GenMsgILSupport" BO_ 1322 0;
BA_ "NmMessage" BO_ 1322 1;
BA_ "NWM-Botschaft" BO_ 1350 1;
BA_ "GenMsgILSupport" BO_ 1350 0;
BA_ "NmMessage" BO_ 1350 1;
BA_ "NWM-Botschaft" BO_ 1336 1;
BA_ "GenMsgILSupport" BO_ 1336 0;
BA_ "NmMessage" BO_ 1336 1;
BA_ "NWM-Botschaft" BO_ 1352 1;
BA_ "GenMsgILSupport" BO_ 1352 0;
BA_ "NmMessage" BO_ 1352 1;
BA_ "NWM-Botschaft" BO_ 1287 1;
BA_ "GenMsgILSupport" BO_ 1287 0;
BA_ "NmMessage" BO_ 1287 1;
BA_ "NWM-Botschaft" BO_ 1364 1;
BA_ "GenMsgILSupport" BO_ 1364 0;
BA_ "NmMessage" BO_ 1364 1;
BA_ "NWM-Botschaft" BO_ 1311 1;
BA_ "GenMsgILSupport" BO_ 1311 0;
BA_ "NmMessage" BO_ 1311 1;
BA_ "NWM-Botschaft" BO_ 1333 1;
BA_ "GenMsgILSupport" BO_ 1333 0;
BA_ "NmMessage" BO_ 1333 1;
BA_ "NWM-Botschaft" BO_ 1310 1;
BA_ "GenMsgILSupport" BO_ 1310 0;
BA_ "NmMessage" BO_ 1310 1;
BA_ "NWM-Botschaft" BO_ 1354 1;
BA_ "GenMsgILSupport" BO_ 1354 0;
BA_ "NmMessage" BO_ 1354 1;
BA_ "NWM-Botschaft" BO_ 1363 1;
BA_ "GenMsgILSupport" BO_ 1363 0;
BA_ "NmMessage" BO_ 1363 1;
BA_ "Version" SG_ 2214658050 ENG_AccelPdlVal "18.01.01";
BA_ "RoutingFactor" SG_ 2214658050 ENG_AccelPdlVal 5;
BA_ "UserSigValidity" SG_ 2214658050 ENG_AccelPdlVal 3;
BA_ "Description" SG_ 2214658050 ENG_AccelPdlVal "The signal PV_AV_CAN is a measure of the Accelerator Pedal value.

The accelerator pedal value is determined via 2 pedal sensors, which are connected mechanically to the

accelerator pedal. If the EMS-ECU recognizes that the accelerator pedal is not acti";
BA_ "Version" SG_ 2210462210 HCU_HevRdySta "18.08.02";
BA_ "RoutingFactor" SG_ 2210462210 HCU_HevRdySta 5;
BA_ "UserSigValidity" SG_ 2210462210 HCU_HevRdySta 3;
BA_ "Description" SG_ 2210462210 HCU_HevRdySta "Hybrid Vehicle Drivable ready";
BA_ "Version" SG_ 1167 ICU_BattAutoCutPreWrng "20.04.06";
BA_ "UserSigValidity" SG_ 1167 ICU_BattAutoCutPreWrng 0;
BA_ "GenSigStartValue" SG_ 1167 ICU_BattAutoCutPreWrng 3;
BA_ "GenSigSendType" SG_ 1167 ICU_BattAutoCutPreWrng 4;
BA_ "Description" SG_ 1167 ICU_BattAutoCutPreWrng "This is a warning signal before blocking the dark current of the ICU by the battery SOC.";
BA_ "Version" SG_ 1015 HU_MM_Altitude "22.07.05";
BA_ "UserSigValidity" SG_ 1015 HU_MM_Altitude 1;
BA_ "Description" SG_ 1015 HU_MM_Altitude "MSL

range = -40000 <= Value <= 1000000

unit = cm";
BA_ "Version" SG_ 1015 HU_MM_Heading "22.07.05";
BA_ "UserSigValidity" SG_ 1015 HU_MM_Heading 1;
BA_ "Description" SG_ 1015 HU_MM_Heading "range = 0<=Valud <360";
BA_ "Version" SG_ 763 Warn_HoodSwSta_SBCM "21.09.08";
BA_ "NetworkRequestHoldingTime" SG_ 763 Warn_HoodSwSta_SBCM 5000;
BA_ "NetworkRequest" SG_ 763 Warn_HoodSwSta_SBCM 0;
BA_ "UserSigValidity" SG_ 763 Warn_HoodSwSta_SBCM 0;
BA_ "GenSigSendType" SG_ 763 Warn_HoodSwSta_SBCM 4;
BA_ "Version" SG_ 763 Hood_TypeOption "22.03.01";
BA_ "NetworkRequestHoldingTime" SG_ 763 Hood_TypeOption 5000;
BA_ "NetworkRequest" SG_ 763 Hood_TypeOption 0;
BA_ "UserSigValidity" SG_ 763 Hood_TypeOption 0;
BA_ "GenSigSendType" SG_ 763 Hood_TypeOption 4;
BA_ "Description" SG_ 763 Hood_TypeOption "If the E-Hood is applied, the signal will be send.";
BA_ "Version" SG_ 1048 DriveTypeOption "21.11.00";
BA_ "NetworkRequestHoldingTime" SG_ 1048 DriveTypeOption 5000;
BA_ "NetworkRequest" SG_ 1048 DriveTypeOption 0;
BA_ "UserSigValidity" SG_ 1048 DriveTypeOption 0;
BA_ "GenSigSendType" SG_ 1048 DriveTypeOption 4;
BA_ "Description" SG_ 1048 DriveTypeOption "Drive Type Option

This signal is used to determine driver's seat position('Drive Type') about this vehicle.";
BA_ "Version" SG_ 1048 ICU_PowerAutoCutModSta "22.06.05";
BA_ "UserSigValidity" SG_ 1048 ICU_PowerAutoCutModSta 0;
BA_ "GenSigSendType" SG_ 1048 ICU_PowerAutoCutModSta 4;
BA_ "Description" SG_ 1048 ICU_PowerAutoCutModSta "ICU Delivery Mode State";
BA_ "Version" SG_ 1050 Lamp_ExtrnlTailLmpOnReq "17.12.00";
BA_ "NetworkRequestHoldingTime" SG_ 1050 Lamp_ExtrnlTailLmpOnReq 5000;
BA_ "NetworkRequest" SG_ 1050 Lamp_ExtrnlTailLmpOnReq 0;
BA_ "UserSigValidity" SG_ 1050 Lamp_ExtrnlTailLmpOnReq 0;
BA_ "GenSigSendType" SG_ 1050 Lamp_ExtrnlTailLmpOnReq 4;
BA_ "Description" SG_ 1050 Lamp_ExtrnlTailLmpOnReq "-(Old)C_EXTTailOn";
BA_ "Version" SG_ 1002 BLTN_CAM_HU_UI_Mode "22.05.02";
BA_ "UserSigValidity" SG_ 1002 BLTN_CAM_HU_UI_Mode 0;
BA_ "GenSigSendType" SG_ 1002 BLTN_CAM_HU_UI_Mode 4;
BA_ "Description" SG_ 1002 BLTN_CAM_HU_UI_Mode "Display control of Built-in Cam UI mode. This Signal for Ethernet Type Built-in Cam.";
BA_ "Version" SG_ 1002 BLTN_CAM_SD_Format_Op_State "21.07.04";
BA_ "UserSigValidity" SG_ 1002 BLTN_CAM_SD_Format_Op_State 1;
BA_ "GenSigSendType" SG_ 1002 BLTN_CAM_SD_Format_Op_State 4;
BA_ "Description" SG_ 1002 BLTN_CAM_SD_Format_Op_State "BLTN_CAM SD card format operation status.";
BA_ "Version" SG_ 1002 BLTN_CAM_PEV_Recorded "21.12.00";
BA_ "NetworkRequestHoldingTime" SG_ 1002 BLTN_CAM_PEV_Recorded 1000;
BA_ "NetworkRequest" SG_ 1002 BLTN_CAM_PEV_Recorded 0;
BA_ "UserSigValidity" SG_ 1002 BLTN_CAM_PEV_Recorded 1;
BA_ "GenSigSendType" SG_ 1002 BLTN_CAM_PEV_Recorded 4;
BA_ "Description" SG_ 1002 BLTN_CAM_PEV_Recorded "This Signal is sent just after the park event recorded.";
BA_ "Version" SG_ 1002 BLTN_CAM_PEV_Count "21.12.00";
BA_ "NetworkRequestHoldingTime" SG_ 1002 BLTN_CAM_PEV_Count 1000;
BA_ "NetworkRequest" SG_ 1002 BLTN_CAM_PEV_Count 0;
BA_ "UserSigValidity" SG_ 1002 BLTN_CAM_PEV_Count 1;
BA_ "GenSigSendType" SG_ 1002 BLTN_CAM_PEV_Count 4;
BA_ "Description" SG_ 1002 BLTN_CAM_PEV_Count "This Signal is count of park event record.";
BA_ "Version" SG_ 1002 BLTN_CAM_Ind_Req "22.11.00";
BA_ "UserSigValidity" SG_ 1002 BLTN_CAM_Ind_Req 1;
BA_ "GenSigSendType" SG_ 1002 BLTN_CAM_Ind_Req 4;
BA_ "Description" SG_ 1002 BLTN_CAM_Ind_Req "This Signal is for HU Display Built-in Cam Indicator.";
BA_ "Version" SG_ 1002 BLTN_CAM_LVDS_Mode_State "21.07.04";
BA_ "UserSigValidity" SG_ 1002 BLTN_CAM_LVDS_Mode_State 1;
BA_ "GenSigSendType" SG_ 1002 BLTN_CAM_LVDS_Mode_State 4;
BA_ "Description" SG_ 1002 BLTN_CAM_LVDS_Mode_State "This Signal is for LVDS output status";
BA_ "Version" SG_ 1002 BLTN_CAM_PrkOp_Termiate_Info "21.12.00";
BA_ "NetworkRequestHoldingTime" SG_ 1002 BLTN_CAM_PrkOp_Termiate_Info 1000;
BA_ "NetworkRequest" SG_ 1002 BLTN_CAM_PrkOp_Termiate_Info 0;
BA_ "UserSigValidity" SG_ 1002 BLTN_CAM_PrkOp_Termiate_Info 0;
BA_ "GenSigSendType" SG_ 1002 BLTN_CAM_PrkOp_Termiate_Info 4;
BA_ "Description" SG_ 1002 BLTN_CAM_PrkOp_Termiate_Info "The signal for CCS service related with Built-in Cam Park operation termination.";
BA_ "Version" SG_ 1002 BLTN_CAM_DEV_Recorded "23.04.02";
BA_ "NetworkRequestHoldingTime" SG_ 1002 BLTN_CAM_DEV_Recorded 1000;
BA_ "NetworkRequest" SG_ 1002 BLTN_CAM_DEV_Recorded 0;
BA_ "UserSigValidity" SG_ 1002 BLTN_CAM_DEV_Recorded 1;
BA_ "GenSigSendType" SG_ 1002 BLTN_CAM_DEV_Recorded 4;
BA_ "Description" SG_ 1002 BLTN_CAM_DEV_Recorded "This Signal is sent just after the drive event recorded.";
BA_ "Version" SG_ 1002 BLTN_CAM_DEV_Count "23.04.02";
BA_ "NetworkRequestHoldingTime" SG_ 1002 BLTN_CAM_DEV_Count 1000;
BA_ "NetworkRequest" SG_ 1002 BLTN_CAM_DEV_Count 0;
BA_ "UserSigValidity" SG_ 1002 BLTN_CAM_DEV_Count 1;
BA_ "GenSigSendType" SG_ 1002 BLTN_CAM_DEV_Count 4;
BA_ "Description" SG_ 1002 BLTN_CAM_DEV_Count "This Signal is count of drive event record.";
BA_ "Version" SG_ 1002 BLTN_CAM_Display "21.07.04";
BA_ "UserSigValidity" SG_ 1002 BLTN_CAM_Display 1;
BA_ "GenSigSendType" SG_ 1002 BLTN_CAM_Display 4;
BA_ "Description" SG_ 1002 BLTN_CAM_Display "Display control of Built-in Cam UI mode. This Signal for CAN Type Built-in Cam.(with Standard 5th Wide AVNT)";
BA_ "Version" SG_ 1002 BLTN_CAM_WiFi_State "21.07.04";
BA_ "UserSigValidity" SG_ 1002 BLTN_CAM_WiFi_State 1;
BA_ "GenSigSendType" SG_ 1002 BLTN_CAM_WiFi_State 4;
BA_ "Description" SG_ 1002 BLTN_CAM_WiFi_State "BLTN_CAM WiFi Stattus";
BA_ "Version" SG_ 1041 ICU_MtGearPosRSta "21.07.05";
BA_ "UserSigValidity" SG_ 1041 ICU_MtGearPosRSta 3;
BA_ "GenSigSendType" SG_ 1041 ICU_MtGearPosRSta 4;
BA_ "Description" SG_ 1041 ICU_MtGearPosRSta "Manual Shift Lever R Switch Status 0x0:Off/0x1:On";
BA_ "Version" SG_ 1041 Warn_DrvDrSwSta "17.12.00";
BA_ "NetworkRequestHoldingTime" SG_ 1041 Warn_DrvDrSwSta 5000;
BA_ "NetworkRequest" SG_ 1041 Warn_DrvDrSwSta 0;
BA_ "UserSigValidity" SG_ 1041 Warn_DrvDrSwSta 0;
BA_ "GenSigSendType" SG_ 1041 Warn_DrvDrSwSta 4;
BA_ "Version" SG_ 1041 Warn_AsstDrSwSta "17.12.00";
BA_ "NetworkRequestHoldingTime" SG_ 1041 Warn_AsstDrSwSta 5000;
BA_ "NetworkRequest" SG_ 1041 Warn_AsstDrSwSta 0;
BA_ "UserSigValidity" SG_ 1041 Warn_AsstDrSwSta 0;
BA_ "GenSigSendType" SG_ 1041 Warn_AsstDrSwSta 4;
BA_ "Version" SG_ 1041 Warn_HoodSwSta "17.12.00";
BA_ "NetworkRequestHoldingTime" SG_ 1041 Warn_HoodSwSta 5000;
BA_ "NetworkRequest" SG_ 1041 Warn_HoodSwSta 0;
BA_ "UserSigValidity" SG_ 1041 Warn_HoodSwSta 0;
BA_ "GenSigSendType" SG_ 1041 Warn_HoodSwSta 4;
BA_ "Version" SG_ 1041 Warn_RrLftDrSwSta "17.12.00";
BA_ "NetworkRequestHoldingTime" SG_ 1041 Warn_RrLftDrSwSta 5000;
BA_ "NetworkRequest" SG_ 1041 Warn_RrLftDrSwSta 0;
BA_ "UserSigValidity" SG_ 1041 Warn_RrLftDrSwSta 0;
BA_ "GenSigSendType" SG_ 1041 Warn_RrLftDrSwSta 4;
BA_ "Version" SG_ 1041 Warn_RrRtDrSwSta "17.12.00";
BA_ "NetworkRequestHoldingTime" SG_ 1041 Warn_RrRtDrSwSta 5000;
BA_ "NetworkRequest" SG_ 1041 Warn_RrRtDrSwSta 0;
BA_ "UserSigValidity" SG_ 1041 Warn_RrRtDrSwSta 0;
BA_ "GenSigSendType" SG_ 1041 Warn_RrRtDrSwSta 4;
BA_ "Version" SG_ 992 BAlarm_BglrAlrmCurrentSta "21.09.05";
BA_ "NetworkRequestHoldingTime" SG_ 992 BAlarm_BglrAlrmCurrentSta 5000;
BA_ "NetworkRequest" SG_ 992 BAlarm_BglrAlrmCurrentSta 0;
BA_ "UserSigValidity" SG_ 992 BAlarm_BglrAlrmCurrentSta 0;
BA_ "GenSigSendType" SG_ 992 BAlarm_BglrAlrmCurrentSta 4;
BA_ "Version" SG_ 1040 ICU_BS2SoC "21.09.05";
BA_ "UserSigValidity" SG_ 1040 ICU_BS2SoC 3;
BA_ "GenSigStartValue" SG_ 1040 ICU_BS2SoC 255;
BA_ "GenSigSendType" SG_ 1040 ICU_BS2SoC 4;
BA_ "Description" SG_ 1040 ICU_BS2SoC "This signal is battery State of Charge as calculated by battery sensor.";
BA_ "Version" SG_ 1043 IntLamp_InlTailLmpSta "17.12.00";
BA_ "NetworkRequestHoldingTime" SG_ 1043 IntLamp_InlTailLmpSta 5000;
BA_ "NetworkRequest" SG_ 1043 IntLamp_InlTailLmpSta 0;
BA_ "UserSigValidity" SG_ 1043 IntLamp_InlTailLmpSta 0;
BA_ "GenSigSendType" SG_ 1043 IntLamp_InlTailLmpSta 4;
BA_ "Description" SG_ 1043 IntLamp_InlTailLmpSta "-(Old)C_INTTail_Act";
BA_ "Version" SG_ 1043 Lamp_TrnSigLmpLftOnReq "22.05.04";
BA_ "NetworkRequestHoldingTime" SG_ 1043 Lamp_TrnSigLmpLftOnReq 5000;
BA_ "NetworkRequest" SG_ 1043 Lamp_TrnSigLmpLftOnReq 0;
BA_ "UserSigValidity" SG_ 1043 Lamp_TrnSigLmpLftOnReq 0;
BA_ "GenSigSendType" SG_ 1043 Lamp_TrnSigLmpLftOnReq 4;
BA_ "Version" SG_ 1043 Lamp_TrnSigLmpRtOnReq "22.05.04";
BA_ "NetworkRequestHoldingTime" SG_ 1043 Lamp_TrnSigLmpRtOnReq 5000;
BA_ "NetworkRequest" SG_ 1043 Lamp_TrnSigLmpRtOnReq 0;
BA_ "UserSigValidity" SG_ 1043 Lamp_TrnSigLmpRtOnReq 0;
BA_ "GenSigSendType" SG_ 1043 Lamp_TrnSigLmpRtOnReq 4;
BA_ "Version" SG_ 1044 Trunk_TrnkTlgtSwSta "17.12.00";
BA_ "NetworkRequestHoldingTime" SG_ 1044 Trunk_TrnkTlgtSwSta 5000;
BA_ "NetworkRequest" SG_ 1044 Trunk_TrnkTlgtSwSta 0;
BA_ "UserSigValidity" SG_ 1044 Trunk_TrnkTlgtSwSta 0;
BA_ "GenSigSendType" SG_ 1044 Trunk_TrnkTlgtSwSta 4;
BA_ "Description" SG_ 1044 Trunk_TrnkTlgtSwSta "Full Lock SW Status Signal



(TailGate/TrunkLid Tpye all)



1. Luggage or Trunkroom Lamp On/Off



2. TailGate/TrunkLid Open Ind in cluster



3. Normal Open SW



  - SW Off: Full Lock(Full Close state)



  - SW On: ^Full Lock";
BA_ "Version" SG_ 1044 C_CrashUnlockState "21.07.05";
BA_ "NetworkRequest" SG_ 1044 C_CrashUnlockState 0;
BA_ "UserSigValidity" SG_ 1044 C_CrashUnlockState 0;
BA_ "GenSigSendType" SG_ 1044 C_CrashUnlockState 4;
BA_ "Description" SG_ 1044 C_CrashUnlockState "Crash Unlock Active State

-0x0:Off

-0x1:Unlock(crash)";
BA_ "Version" SG_ 1186 C_PreCrankReq "18.09.04";
BA_ "NetworkRequest" SG_ 1186 C_PreCrankReq 0;
BA_ "UserSigValidity" SG_ 1186 C_PreCrankReq 0;
BA_ "GenSigSendType" SG_ 1186 C_PreCrankReq 4;
BA_ "Description" SG_ 1186 C_PreCrankReq "18.08.09_Remote Control message";
BA_ "Version" SG_ 1058 Wiper_PrkngPosSta "17.12.00";
BA_ "NetworkRequestHoldingTime" SG_ 1058 Wiper_PrkngPosSta 5000;
BA_ "NetworkRequest" SG_ 1058 Wiper_PrkngPosSta 0;
BA_ "UserSigValidity" SG_ 1058 Wiper_PrkngPosSta 0;
BA_ "GenSigSendType" SG_ 1058 Wiper_PrkngPosSta 4;
BA_ "Version" SG_ 1058 Wiper_RainSnsrSta "20.08.00";
BA_ "NetworkRequestHoldingTime" SG_ 1058 Wiper_RainSnsrSta 5000;
BA_ "NetworkRequest" SG_ 1058 Wiper_RainSnsrSta 0;
BA_ "UserSigValidity" SG_ 1058 Wiper_RainSnsrSta 0;
BA_ "GenSigSendType" SG_ 1058 Wiper_RainSnsrSta 4;
BA_ "Description" SG_ 1058 Wiper_RainSnsrSta "This signal represents the status of Rain Sensor signal state. 

- '20. 8/3 : Changed value table (0x5, 0x6 : Fault2/3 → Reserved)";
BA_ "Version" SG_ 1195 CF_AVN_CluUSMReset "21.01.08";
BA_ "UserSigValidity" SG_ 1195 CF_AVN_CluUSMReset 3;
BA_ "GenSigSendType" SG_ 1195 CF_AVN_CluUSMReset 4;
BA_ "Version" SG_ 858 AST_CrashUnlockCmd "21.07.07";
BA_ "NetworkRequest" SG_ 858 AST_CrashUnlockCmd 0;
BA_ "UserSigValidity" SG_ 858 AST_CrashUnlockCmd 0;
BA_ "GenSigSendType" SG_ 858 AST_CrashUnlockCmd 4;
BA_ "Description" SG_ 858 AST_CrashUnlockCmd "Assist Crash Unlock Command";
BA_ "Version" SG_ 858 Warn_AsstDrSwSta_SBCM "21.09.05";
BA_ "NetworkRequest" SG_ 858 Warn_AsstDrSwSta_SBCM 0;
BA_ "UserSigValidity" SG_ 858 Warn_AsstDrSwSta_SBCM 0;
BA_ "GenSigSendType" SG_ 858 Warn_AsstDrSwSta_SBCM 4;
BA_ "Description" SG_ 858 Warn_AsstDrSwSta_SBCM "Warning Assist Door Switch Status";
BA_ "Version" SG_ 977 SMK_TrmnlCtrlGrpStaBDC "22.01.06";
BA_ "UserSigValidity" SG_ 977 SMK_TrmnlCtrlGrpStaBDC 0;
BA_ "GenSigSendType" SG_ 977 SMK_TrmnlCtrlGrpStaBDC 4;
BA_ "Description" SG_ 977 SMK_TrmnlCtrlGrpStaBDC "Mirror Value of TerminalControlGroupState(BDC)";
BA_ "Version" SG_ 977 SMK_TrmnlCtrlGrpStaBDCEV "22.05.02";
BA_ "UserSigValidity" SG_ 977 SMK_TrmnlCtrlGrpStaBDCEV 0;
BA_ "GenSigSendType" SG_ 977 SMK_TrmnlCtrlGrpStaBDCEV 4;
BA_ "Description" SG_ 977 SMK_TrmnlCtrlGrpStaBDCEV "Mirror Value of TerminalControlGroupState(BDC-EV)";
BA_ "Version" SG_ 977 SMK_TrmnlCtrlStaBDCEV "22.05.02";
BA_ "UserSigValidity" SG_ 977 SMK_TrmnlCtrlStaBDCEV 0;
BA_ "GenSigSendType" SG_ 977 SMK_TrmnlCtrlStaBDCEV 4;
BA_ "Description" SG_ 977 SMK_TrmnlCtrlStaBDCEV "Mirror Value of TerminalControlState(BDC EV)";
BA_ "Version" SG_ 862 RL_CrashUnlockCmd "21.07.07";
BA_ "NetworkRequest" SG_ 862 RL_CrashUnlockCmd 0;
BA_ "UserSigValidity" SG_ 862 RL_CrashUnlockCmd 0;
BA_ "GenSigSendType" SG_ 862 RL_CrashUnlockCmd 4;
BA_ "Description" SG_ 862 RL_CrashUnlockCmd "RearLefrCrashUnlockCommand";
BA_ "Version" SG_ 862 Warn_RrLftDrSwSta_SBCM "21.09.05";
BA_ "NetworkRequest" SG_ 862 Warn_RrLftDrSwSta_SBCM 0;
BA_ "UserSigValidity" SG_ 862 Warn_RrLftDrSwSta_SBCM 0;
BA_ "GenSigSendType" SG_ 862 Warn_RrLftDrSwSta_SBCM 4;
BA_ "Description" SG_ 862 Warn_RrLftDrSwSta_SBCM "Warning Rear Left Door Switch Status";
BA_ "Version" SG_ 983 BLTN_CAM_SWVerMajor "21.07.05";
BA_ "RoutingFactor" SG_ 983 BLTN_CAM_SWVerMajor 0;
BA_ "UserSigValidity" SG_ 983 BLTN_CAM_SWVerMajor 0;
BA_ "GenSigSendType" SG_ 983 BLTN_CAM_SWVerMajor 4;
BA_ "Description" SG_ 983 BLTN_CAM_SWVerMajor "Indicate the Built-in Cam software version as follows:

- The software version is displayed in seven digits.

- The Major, Minor1, Minor2, Minor3 digits are separated by '.'

- Major Signal value is transmitted to ASCII codes.

- Minor1/Minor2/Minor2 Sig";
BA_ "Version" SG_ 983 BLTN_CAM_SWVerMinor2 "21.07.05";
BA_ "RoutingFactor" SG_ 983 BLTN_CAM_SWVerMinor2 0;
BA_ "UserSigValidity" SG_ 983 BLTN_CAM_SWVerMinor2 0;
BA_ "GenSigSendType" SG_ 983 BLTN_CAM_SWVerMinor2 4;
BA_ "Description" SG_ 983 BLTN_CAM_SWVerMinor2 "Indicate the Built-in Cam software version as follows:

- The software version is displayed in seven digits.

- The Major, Minor1, Minor2, Minor3 digits are separated by '.'

- Major Signal value is transmitted to ASCII codes.

- Minor1/Minor2/Minor2 Sig";
BA_ "Version" SG_ 983 BLTN_CAM_SWVerMinor3 "21.07.05";
BA_ "RoutingFactor" SG_ 983 BLTN_CAM_SWVerMinor3 0;
BA_ "UserSigValidity" SG_ 983 BLTN_CAM_SWVerMinor3 0;
BA_ "GenSigSendType" SG_ 983 BLTN_CAM_SWVerMinor3 4;
BA_ "Description" SG_ 983 BLTN_CAM_SWVerMinor3 "Indicate the Built-in Cam software version as follows:

- The software version is displayed in seven digits.

- The Major, Minor1, Minor2, Minor3 digits are separated by '.'

- Major Signal value is transmitted to ASCII codes.

- Minor1/Minor2/Minor2 Sig";
BA_ "Version" SG_ 983 BLTN_CAM_SD_Card_Manufacturer "22.07.05";
BA_ "RoutingFactor" SG_ 983 BLTN_CAM_SD_Card_Manufacturer 0;
BA_ "UserSigValidity" SG_ 983 BLTN_CAM_SD_Card_Manufacturer 0;
BA_ "GenSigSendType" SG_ 983 BLTN_CAM_SD_Card_Manufacturer 4;
BA_ "Description" SG_ 983 BLTN_CAM_SD_Card_Manufacturer "Built-in Cam SD Card Manufacturer Information";
BA_ "Version" SG_ 983 BLTN_CAM_SD_Card_Cap_Class "22.07.05";
BA_ "RoutingFactor" SG_ 983 BLTN_CAM_SD_Card_Cap_Class 0;
BA_ "UserSigValidity" SG_ 983 BLTN_CAM_SD_Card_Cap_Class 0;
BA_ "GenSigSendType" SG_ 983 BLTN_CAM_SD_Card_Cap_Class 4;
BA_ "Description" SG_ 983 BLTN_CAM_SD_Card_Cap_Class "SD Card Storage Capacity Class";
BA_ "Version" SG_ 983 BLTN_CAM_SWVerMinor1 "21.07.05";
BA_ "RoutingFactor" SG_ 983 BLTN_CAM_SWVerMinor1 0;
BA_ "UserSigValidity" SG_ 983 BLTN_CAM_SWVerMinor1 0;
BA_ "GenSigSendType" SG_ 983 BLTN_CAM_SWVerMinor1 4;
BA_ "Description" SG_ 983 BLTN_CAM_SWVerMinor1 "Indicate the Built-in Cam software version as follows:

- The software version is displayed in seven digits.

- The Major, Minor1, Minor2, Minor3 digits are separated by '.'

- Major Signal value is transmitted to ASCII codes.

- Minor1/Minor2/Minor2 Sig";
BA_ "Version" SG_ 2160080132 VCU_GearPosStaDisp "20.12.04";
BA_ "RoutingFactor" SG_ 2160080132 VCU_GearPosStaDisp 5;
BA_ "UserSigValidity" SG_ 2160080132 VCU_GearPosStaDisp 7;
BA_ "GenSigStartValue" SG_ 2160080132 VCU_GearPosStaDisp 9;
BA_ "Description" SG_ 2160080132 VCU_GearPosStaDisp "Gear Position Status for CLU display";
BA_ "Version" SG_ 721 HU_DR_Altitude "22.07.05";
BA_ "UserSigValidity" SG_ 721 HU_DR_Altitude 1;
BA_ "Description" SG_ 721 HU_DR_Altitude "MSL";
BA_ "Version" SG_ 722 HU_DR_Latitude "22.07.05";
BA_ "UserSigValidity" SG_ 722 HU_DR_Latitude 1;
BA_ "Version" SG_ 722 HU_DR_Longitude "22.07.05";
BA_ "UserSigValidity" SG_ 722 HU_DR_Longitude 1;
BA_ "Version" SG_ 723 HU_DR_Heading "22.07.05";
BA_ "UserSigValidity" SG_ 723 HU_DR_Heading 1;
BA_ "Version" SG_ 2160080129 VCU_EvDrvRdySta "20.04.05";
BA_ "RoutingFactor" SG_ 2160080129 VCU_EvDrvRdySta 5;
BA_ "UserSigValidity" SG_ 2160080129 VCU_EvDrvRdySta 7;
BA_ "Description" SG_ 2160080129 VCU_EvDrvRdySta "EV Ready";
BA_ "Version" SG_ 2160080129 VCU_GearPosSta "21.05.01";
BA_ "RoutingFactor" SG_ 2160080129 VCU_GearPosSta 5;
BA_ "UserSigValidity" SG_ 2160080129 VCU_GearPosSta 7;
BA_ "GenSigStartValue" SG_ 2160080129 VCU_GearPosSta 9;
BA_ "Description" SG_ 2160080129 VCU_GearPosSta "Gear Position Status";
BA_ "Version" SG_ 2160080129 VCU_AccPedDepVal "20.04.05";
BA_ "RoutingFactor" SG_ 2160080129 VCU_AccPedDepVal 5;
BA_ "UserSigValidity" SG_ 2160080129 VCU_AccPedDepVal 7;
BA_ "Description" SG_ 2160080129 VCU_AccPedDepVal "Accelerator Pedal Depth Value";
BA_ "Version" SG_ 1079 CTM_TrailerAct "18.04.01";
BA_ "NetworkRequest" SG_ 1079 CTM_TrailerAct 0;
BA_ "UserSigValidity" SG_ 1079 CTM_TrailerAct 3;
BA_ "GenSigSendType" SG_ 1079 CTM_TrailerAct 4;
BA_ "Description" SG_ 1079 CTM_TrailerAct "This signal is used for control the Trailer Act function.";
BA_ "Version" SG_ 2164278529 HTCU_GearSlctrDis "18.08.02";
BA_ "RoutingFactor" SG_ 2164278529 HTCU_GearSlctrDis 5;
BA_ "UserSigValidity" SG_ 2164278529 HTCU_GearSlctrDis 3;
BA_ "GenSigStartValue" SG_ 2164278529 HTCU_GearSlctrDis 9;
BA_ "Description" SG_ 2164278529 HTCU_GearSlctrDis "Position (P, R, N..), which was identified by the gear selector.

In case the gear selector is in a intermediate position, the last clear recognized position is used.

There is no specific phase relationship between the output and any other signal.";
BA_ "Version" SG_ 1076 IAU_ProfileIDRVal "23.02.02";
BA_ "NetworkRequestHoldingTime" SG_ 1076 IAU_ProfileIDRVal 5000;
BA_ "NetworkRequest" SG_ 1076 IAU_ProfileIDRVal 0;
BA_ "UserSigValidity" SG_ 1076 IAU_ProfileIDRVal 0;
BA_ "GenSigSendType" SG_ 1076 IAU_ProfileIDRVal 4;
BA_ "UserSigValidity" SG_ 1301 Destination_WPC2 0;
BA_ "UsrSigPurpose" SG_ 1301 Destination_WPC2 9;
BA_ "UserSigValidity" SG_ 1301 NMCommandCode_WPC2 0;
BA_ "UsrSigPurpose" SG_ 1301 NMCommandCode_WPC2 9;
BA_ "UserSigValidity" SG_ 1301 NMSleepFlag_WPC2 0;
BA_ "UsrSigPurpose" SG_ 1301 NMSleepFlag_WPC2 9;
BA_ "UserSigValidity" SG_ 1345 Destination_PSB 0;
BA_ "UsrSigPurpose" SG_ 1345 Destination_PSB 9;
BA_ "UserSigValidity" SG_ 1345 NMCommandCode_PSB 0;
BA_ "UsrSigPurpose" SG_ 1345 NMCommandCode_PSB 9;
BA_ "UserSigValidity" SG_ 1345 NMSleepFlag_PSB 0;
BA_ "UsrSigPurpose" SG_ 1345 NMSleepFlag_PSB 9;
BA_ "UserSigValidity" SG_ 1323 Destination_SHVU_RR 0;
BA_ "UsrSigPurpose" SG_ 1323 Destination_SHVU_RR 9;
BA_ "UserSigValidity" SG_ 1323 NMCommandCode_SHVU_RR 0;
BA_ "UsrSigPurpose" SG_ 1323 NMCommandCode_SHVU_RR 9;
BA_ "UserSigValidity" SG_ 1323 NMSleepFlag_SHVU_RR 0;
BA_ "UsrSigPurpose" SG_ 1323 NMSleepFlag_SHVU_RR 9;
BA_ "UserSigValidity" SG_ 1313 Destination_FCS 0;
BA_ "UsrSigPurpose" SG_ 1313 Destination_FCS 9;
BA_ "UserSigValidity" SG_ 1313 NMCommandCode_FCS 0;
BA_ "UsrSigPurpose" SG_ 1313 NMCommandCode_FCS 9;
BA_ "UserSigValidity" SG_ 1313 NMSleepFlag_FCS 0;
BA_ "UsrSigPurpose" SG_ 1313 NMSleepFlag_FCS 9;
BA_ "UserSigValidity" SG_ 1297 Destination_EMCU 0;
BA_ "UsrSigPurpose" SG_ 1297 Destination_EMCU 9;
BA_ "UserSigValidity" SG_ 1297 NMCommandCode_EMCU 0;
BA_ "UsrSigPurpose" SG_ 1297 NMCommandCode_EMCU 9;
BA_ "UserSigValidity" SG_ 1297 NMSleepFlag_EMCU 0;
BA_ "UsrSigPurpose" SG_ 1297 NMSleepFlag_EMCU 9;
BA_ "UserSigValidity" SG_ 1307 Destination_SLB 0;
BA_ "UsrSigPurpose" SG_ 1307 Destination_SLB 9;
BA_ "UserSigValidity" SG_ 1307 NMCommandCode_SLB 0;
BA_ "UsrSigPurpose" SG_ 1307 NMCommandCode_SLB 9;
BA_ "UserSigValidity" SG_ 1307 NMSleepFlag_SLB 0;
BA_ "UsrSigPurpose" SG_ 1307 NMSleepFlag_SLB 9;
BA_ "UserSigValidity" SG_ 1329 Destination_GW_APSU 0;
BA_ "UsrSigPurpose" SG_ 1329 Destination_GW_APSU 9;
BA_ "UserSigValidity" SG_ 1329 NMCommandCode_GW_APSU 0;
BA_ "UsrSigPurpose" SG_ 1329 NMCommandCode_GW_APSU 9;
BA_ "UserSigValidity" SG_ 1329 NMSleepFlag_GW_APSU 0;
BA_ "UsrSigPurpose" SG_ 1329 NMSleepFlag_GW_APSU 9;
BA_ "UserSigValidity" SG_ 1344 Destination_GW_DLBCU 0;
BA_ "UsrSigPurpose" SG_ 1344 Destination_GW_DLBCU 9;
BA_ "UserSigValidity" SG_ 1344 NMCommandCode_GW_DLBCU 0;
BA_ "UsrSigPurpose" SG_ 1344 NMCommandCode_GW_DLBCU 9;
BA_ "UserSigValidity" SG_ 1344 NMSleepFlag_GW_DLBCU 0;
BA_ "UsrSigPurpose" SG_ 1344 NMSleepFlag_GW_DLBCU 9;
BA_ "UserSigValidity" SG_ 1290 Destination_ARS 0;
BA_ "UsrSigPurpose" SG_ 1290 Destination_ARS 9;
BA_ "UserSigValidity" SG_ 1290 NMCommandCode_ARS 0;
BA_ "UsrSigPurpose" SG_ 1290 NMCommandCode_ARS 9;
BA_ "UserSigValidity" SG_ 1290 NMSleepFlag_ARS 0;
BA_ "UsrSigPurpose" SG_ 1290 NMSleepFlag_ARS 9;
BA_ "UserSigValidity" SG_ 1341 Destination_RCM 0;
BA_ "UsrSigPurpose" SG_ 1341 Destination_RCM 9;
BA_ "UserSigValidity" SG_ 1341 NMCommandCode_RCM 0;
BA_ "UsrSigPurpose" SG_ 1341 NMCommandCode_RCM 9;
BA_ "UserSigValidity" SG_ 1341 NMSleepFlag_RCM 0;
BA_ "UsrSigPurpose" SG_ 1341 NMSleepFlag_RCM 9;
BA_ "UserSigValidity" SG_ 1392 Destination_CGW_CCU 0;
BA_ "UsrSigPurpose" SG_ 1392 Destination_CGW_CCU 9;
BA_ "UserSigValidity" SG_ 1392 NMCommandCode_CGW_CCU 0;
BA_ "UsrSigPurpose" SG_ 1392 NMCommandCode_CGW_CCU 9;
BA_ "UserSigValidity" SG_ 1392 NMSleepFlag_CGW_CCU 0;
BA_ "UsrSigPurpose" SG_ 1392 NMSleepFlag_CGW_CCU 9;
BA_ "UserSigValidity" SG_ 1308 Destination_GW_RLPSU 0;
BA_ "UsrSigPurpose" SG_ 1308 Destination_GW_RLPSU 9;
BA_ "UserSigValidity" SG_ 1308 NMCommandCode_GW_RLPSU 0;
BA_ "UsrSigPurpose" SG_ 1308 NMCommandCode_GW_RLPSU 9;
BA_ "UserSigValidity" SG_ 1308 NMSleepFlag_GW_RLPSU 0;
BA_ "UsrSigPurpose" SG_ 1308 NMSleepFlag_GW_RLPSU 9;
BA_ "UserSigValidity" SG_ 1360 Destination_ATS 0;
BA_ "UsrSigPurpose" SG_ 1360 Destination_ATS 9;
BA_ "UserSigValidity" SG_ 1360 NMCommandCode_ATS 0;
BA_ "UsrSigPurpose" SG_ 1360 NMCommandCode_ATS 9;
BA_ "UserSigValidity" SG_ 1360 NMSleepFlag_ATS 0;
BA_ "UsrSigPurpose" SG_ 1360 NMSleepFlag_ATS 9;
BA_ "UserSigValidity" SG_ 1332 Destination_RLHV 0;
BA_ "UsrSigPurpose" SG_ 1332 Destination_RLHV 9;
BA_ "UserSigValidity" SG_ 1332 NMCommandCode_RLHV 0;
BA_ "UsrSigPurpose" SG_ 1332 NMCommandCode_RLHV 9;
BA_ "UserSigValidity" SG_ 1332 NMSleepFlag_RLHV 0;
BA_ "UsrSigPurpose" SG_ 1332 NMSleepFlag_RLHV 9;
BA_ "UserSigValidity" SG_ 1342 Destination_SGU 0;
BA_ "UsrSigPurpose" SG_ 1342 Destination_SGU 9;
BA_ "UserSigValidity" SG_ 1342 NMCommandCode_SGU 0;
BA_ "UsrSigPurpose" SG_ 1342 NMCommandCode_SGU 9;
BA_ "UserSigValidity" SG_ 1342 NMSleepFlag_SGU 0;
BA_ "UsrSigPurpose" SG_ 1342 NMSleepFlag_SGU 9;
BA_ "UserSigValidity" SG_ 1325 Destination_PFSU 0;
BA_ "UsrSigPurpose" SG_ 1325 Destination_PFSU 9;
BA_ "UserSigValidity" SG_ 1325 NMCommandCode_PFSU 0;
BA_ "UsrSigPurpose" SG_ 1325 NMCommandCode_PFSU 9;
BA_ "UserSigValidity" SG_ 1325 NMSleepFlag_PFSU 0;
BA_ "UsrSigPurpose" SG_ 1325 NMSleepFlag_PFSU 9;
BA_ "UserSigValidity" SG_ 1348 Destination_ALBCU 0;
BA_ "UsrSigPurpose" SG_ 1348 Destination_ALBCU 9;
BA_ "UserSigValidity" SG_ 1348 NMCommandCode_ALBCU 0;
BA_ "UsrSigPurpose" SG_ 1348 NMCommandCode_ALBCU 9;
BA_ "UserSigValidity" SG_ 1348 NMSleepFlag_ALBCU 0;
BA_ "UsrSigPurpose" SG_ 1348 NMSleepFlag_ALBCU 9;
BA_ "UserSigValidity" SG_ 1309 Destination_GW_RRPSU 0;
BA_ "UsrSigPurpose" SG_ 1309 Destination_GW_RRPSU 9;
BA_ "UserSigValidity" SG_ 1309 NMCommandCode_GW_RRPSU 0;
BA_ "UsrSigPurpose" SG_ 1309 NMCommandCode_GW_RRPSU 9;
BA_ "UserSigValidity" SG_ 1309 NMSleepFlag_GW_RRPSU 0;
BA_ "UsrSigPurpose" SG_ 1309 NMSleepFlag_GW_RRPSU 9;
BA_ "UserSigValidity" SG_ 1369 Destination_DSAU 0;
BA_ "UsrSigPurpose" SG_ 1369 Destination_DSAU 9;
BA_ "UserSigValidity" SG_ 1369 NMCommandCode_DSAU 0;
BA_ "UsrSigPurpose" SG_ 1369 NMCommandCode_DSAU 9;
BA_ "UserSigValidity" SG_ 1369 NMSleepFlag_DSAU 0;
BA_ "UsrSigPurpose" SG_ 1369 NMSleepFlag_DSAU 9;
BA_ "UserSigValidity" SG_ 1288 Destination_SWRC 0;
BA_ "UsrSigPurpose" SG_ 1288 Destination_SWRC 9;
BA_ "UserSigValidity" SG_ 1288 NMCommandCode_SWRC 0;
BA_ "UsrSigPurpose" SG_ 1288 NMCommandCode_SWRC 9;
BA_ "UserSigValidity" SG_ 1288 NMSleepFlag_SWRC 0;
BA_ "UsrSigPurpose" SG_ 1288 NMSleepFlag_SWRC 9;
BA_ "UserSigValidity" SG_ 1322 Destination_SHVU_FR 0;
BA_ "UsrSigPurpose" SG_ 1322 Destination_SHVU_FR 9;
BA_ "UserSigValidity" SG_ 1322 NMCommandCode_SHVU_FR 0;
BA_ "UsrSigPurpose" SG_ 1322 NMCommandCode_SHVU_FR 9;
BA_ "UserSigValidity" SG_ 1322 NMSleepFlag_SHVU_FR 0;
BA_ "UsrSigPurpose" SG_ 1322 NMSleepFlag_SHVU_FR 9;
BA_ "UserSigValidity" SG_ 1350 Destination_RCS 0;
BA_ "UsrSigPurpose" SG_ 1350 Destination_RCS 9;
BA_ "UserSigValidity" SG_ 1350 NMCommandCode_RCS 0;
BA_ "UsrSigPurpose" SG_ 1350 NMCommandCode_RCS 9;
BA_ "UserSigValidity" SG_ 1350 NMSleepFlag_RCS 0;
BA_ "UsrSigPurpose" SG_ 1350 NMSleepFlag_RCS 9;
BA_ "UserSigValidity" SG_ 1336 Destination_GW_DPSU 0;
BA_ "UsrSigPurpose" SG_ 1336 Destination_GW_DPSU 9;
BA_ "UserSigValidity" SG_ 1336 NMCommandCode_GW_DPSU 0;
BA_ "UsrSigPurpose" SG_ 1336 NMCommandCode_GW_DPSU 9;
BA_ "UserSigValidity" SG_ 1336 NMSleepFlag_GW_DPSU 0;
BA_ "UsrSigPurpose" SG_ 1336 NMSleepFlag_GW_DPSU 9;
BA_ "UserSigValidity" SG_ 1352 Destination_BLTN_CAM 0;
BA_ "UsrSigPurpose" SG_ 1352 Destination_BLTN_CAM 9;
BA_ "UserSigValidity" SG_ 1352 NMCommandCode_BLTN_CAM 0;
BA_ "UsrSigPurpose" SG_ 1352 NMCommandCode_BLTN_CAM 9;
BA_ "UserSigValidity" SG_ 1352 NMSleepFlag_BLTN_CAM 0;
BA_ "UsrSigPurpose" SG_ 1352 NMSleepFlag_BLTN_CAM 9;
BA_ "UserSigValidity" SG_ 1287 Destination_SCM 0;
BA_ "UsrSigPurpose" SG_ 1287 Destination_SCM 9;
BA_ "UserSigValidity" SG_ 1287 NMCommandCode_SCM 0;
BA_ "UsrSigPurpose" SG_ 1287 NMCommandCode_SCM 9;
BA_ "UserSigValidity" SG_ 1287 NMSleepFlag_SCM 0;
BA_ "UsrSigPurpose" SG_ 1287 NMSleepFlag_SCM 9;
BA_ "UserSigValidity" SG_ 1364 Destination_OHCL 0;
BA_ "UsrSigPurpose" SG_ 1364 Destination_OHCL 9;
BA_ "UserSigValidity" SG_ 1364 NMCommandCode_OHCL 0;
BA_ "UsrSigPurpose" SG_ 1364 NMCommandCode_OHCL 9;
BA_ "UserSigValidity" SG_ 1364 NMSleepFlag_OHCL 0;
BA_ "UsrSigPurpose" SG_ 1364 NMSleepFlag_OHCL 9;
BA_ "UserSigValidity" SG_ 1311 Destination_RWPC 0;
BA_ "UsrSigPurpose" SG_ 1311 Destination_RWPC 9;
BA_ "UserSigValidity" SG_ 1311 NMCommandCode_RWPC 0;
BA_ "UsrSigPurpose" SG_ 1311 NMCommandCode_RWPC 9;
BA_ "UserSigValidity" SG_ 1311 NMSleepFlag_RWPC 0;
BA_ "UsrSigPurpose" SG_ 1311 NMSleepFlag_RWPC 9;
BA_ "UserSigValidity" SG_ 1333 Destination_RRHV 0;
BA_ "UsrSigPurpose" SG_ 1333 Destination_RRHV 9;
BA_ "UserSigValidity" SG_ 1333 NMCommandCode_RRHV 0;
BA_ "UsrSigPurpose" SG_ 1333 NMCommandCode_RRHV 9;
BA_ "UserSigValidity" SG_ 1333 NMSleepFlag_RRHV 0;
BA_ "UsrSigPurpose" SG_ 1333 NMSleepFlag_RRHV 9;
BA_ "UserSigValidity" SG_ 1310 Destination_WPC 0;
BA_ "UsrSigPurpose" SG_ 1310 Destination_WPC 9;
BA_ "UserSigValidity" SG_ 1310 NMCommandCode_WPC 0;
BA_ "UsrSigPurpose" SG_ 1310 NMCommandCode_WPC 9;
BA_ "UserSigValidity" SG_ 1310 NMSleepFlag_WPC 0;
BA_ "UsrSigPurpose" SG_ 1310 NMSleepFlag_WPC 9;
BA_ "UserSigValidity" SG_ 1354 Destination_HOD 0;
BA_ "UsrSigPurpose" SG_ 1354 Destination_HOD 9;
BA_ "UserSigValidity" SG_ 1354 NMCommandCode_HOD 0;
BA_ "UsrSigPurpose" SG_ 1354 NMCommandCode_HOD 9;
BA_ "UserSigValidity" SG_ 1354 NMSleepFlag_HOD 0;
BA_ "UsrSigPurpose" SG_ 1354 NMSleepFlag_HOD 9;
BA_ "UserSigValidity" SG_ 1363 Destination_ASAU 0;
BA_ "UsrSigPurpose" SG_ 1363 Destination_ASAU 9;
BA_ "UserSigValidity" SG_ 1363 NMCommandCode_ASAU 0;
BA_ "UsrSigPurpose" SG_ 1363 NMCommandCode_ASAU 9;
BA_ "UserSigValidity" SG_ 1363 NMSleepFlag_ASAU 0;
BA_ "UsrSigPurpose" SG_ 1363 NMSleepFlag_ASAU 9;
BA_REL_ "GenSigTimeoutTime" BU_SG_REL_ BLTN_CAM SG_ 1167 ICU_BattAutoCutPreWrng 5000;
BA_REL_ "GenSigTimeoutTime" BU_SG_REL_ BLTN_CAM SG_ 1015 HU_MM_Altitude 5000;
BA_REL_ "GenSigTimeoutTime" BU_SG_REL_ BLTN_CAM SG_ 1015 HU_MM_Heading 5000;
BA_REL_ "GenSigTimeoutTime" BU_SG_REL_ BLTN_CAM SG_ 763 Warn_HoodSwSta_SBCM 1500;
BA_REL_ "GenSigTimeoutTime" BU_SG_REL_ BLTN_CAM SG_ 763 Hood_TypeOption 1500;
BA_REL_ "GenSigTimeoutTime" BU_SG_REL_ ATS SG_ 1048 DriveTypeOption 1500;
BA_REL_ "GenSigTimeoutTime" BU_SG_REL_ BLTN_CAM SG_ 1048 DriveTypeOption 1500;
BA_REL_ "GenSigTimeoutTime" BU_SG_REL_ GW_APSU SG_ 1048 DriveTypeOption 1500;
BA_REL_ "GenSigTimeoutTime" BU_SG_REL_ GW_DLBCU SG_ 1048 DriveTypeOption 1500;
BA_REL_ "GenSigTimeoutTime" BU_SG_REL_ GW_DPSU SG_ 1048 DriveTypeOption 1500;
BA_REL_ "GenSigTimeoutTime" BU_SG_REL_ GW_RLPSU SG_ 1048 DriveTypeOption 1500;
BA_REL_ "GenSigTimeoutTime" BU_SG_REL_ GW_RRPSU SG_ 1048 DriveTypeOption 1500;
BA_REL_ "GenSigTimeoutTime" BU_SG_REL_ SHVU_FR SG_ 1048 DriveTypeOption 1500;
BA_REL_ "GenSigTimeoutTime" BU_SG_REL_ SHVU_RR SG_ 1048 DriveTypeOption 1500;
BA_REL_ "GenSigTimeoutTime" BU_SG_REL_ BLTN_CAM SG_ 1048 ICU_PowerAutoCutModSta 1500;
BA_REL_ "GenSigTimeoutTime" BU_SG_REL_ GW_APSU SG_ 1048 ICU_PowerAutoCutModSta 1500;
BA_REL_ "GenSigTimeoutTime" BU_SG_REL_ GW_DPSU SG_ 1048 ICU_PowerAutoCutModSta 1500;
BA_REL_ "GenSigTimeoutTime" BU_SG_REL_ GW_RLPSU SG_ 1048 ICU_PowerAutoCutModSta 1500;
BA_REL_ "GenSigTimeoutTime" BU_SG_REL_ GW_RRPSU SG_ 1048 ICU_PowerAutoCutModSta 1500;
BA_REL_ "GenSigTimeoutTime" BU_SG_REL_ PFSU SG_ 1048 ICU_PowerAutoCutModSta 1500;
BA_REL_ "GenSigTimeoutTime" BU_SG_REL_ RLHV SG_ 1048 ICU_PowerAutoCutModSta 1500;
BA_REL_ "GenSigTimeoutTime" BU_SG_REL_ RRHV SG_ 1048 ICU_PowerAutoCutModSta 1500;
BA_REL_ "GenSigTimeoutTime" BU_SG_REL_ SHVU_FR SG_ 1048 ICU_PowerAutoCutModSta 1500;
BA_REL_ "GenSigTimeoutTime" BU_SG_REL_ SHVU_RR SG_ 1048 ICU_PowerAutoCutModSta 1500;
BA_REL_ "GenSigTimeoutTime" BU_SG_REL_ BLTN_CAM SG_ 1050 Lamp_ExtrnlTailLmpOnReq 1500;
BA_REL_ "GenSigTimeoutTime" BU_SG_REL_ CGW_CCU SG_ 1002 BLTN_CAM_HU_UI_Mode 1500;
BA_REL_ "GenSigTimeoutTime" BU_SG_REL_ CGW_CCU SG_ 1002 BLTN_CAM_SD_Format_Op_State 1500;
BA_REL_ "GenSigTimeoutTime" BU_SG_REL_ CGW_CCU SG_ 1002 BLTN_CAM_PEV_Recorded 1500;
BA_REL_ "GenSigTimeoutTime" BU_SG_REL_ CGW_CCU SG_ 1002 BLTN_CAM_PEV_Count 1500;
BA_REL_ "GenSigTimeoutTime" BU_SG_REL_ CGW_CCU SG_ 1002 BLTN_CAM_Ind_Req 1500;
BA_REL_ "GenSigTimeoutTime" BU_SG_REL_ CGW_CCU SG_ 1002 BLTN_CAM_LVDS_Mode_State 1500;
BA_REL_ "GenSigTimeoutTime" BU_SG_REL_ CGW_CCU SG_ 1002 BLTN_CAM_PrkOp_Termiate_Info 1500;
BA_REL_ "GenSigTimeoutTime" BU_SG_REL_ CGW_CCU SG_ 1002 BLTN_CAM_DEV_Recorded 1500;
BA_REL_ "GenSigTimeoutTime" BU_SG_REL_ CGW_CCU SG_ 1002 BLTN_CAM_DEV_Count 1500;
BA_REL_ "GenSigTimeoutTime" BU_SG_REL_ CGW_CCU SG_ 1002 BLTN_CAM_Display 1500;
BA_REL_ "GenSigTimeoutTime" BU_SG_REL_ CGW_CCU SG_ 1002 BLTN_CAM_WiFi_State 1500;
BA_REL_ "GenSigTimeoutTime" BU_SG_REL_ BLTN_CAM SG_ 1041 ICU_MtGearPosRSta 1500;
BA_REL_ "GenSigTimeoutTime" BU_SG_REL_ BLTN_CAM SG_ 1041 Warn_DrvDrSwSta 1500;
BA_REL_ "GenSigTimeoutTime" BU_SG_REL_ GW_DPSU SG_ 1041 Warn_DrvDrSwSta 1500;
BA_REL_ "GenSigTimeoutTime" BU_SG_REL_ PSB SG_ 1041 Warn_DrvDrSwSta 1500;
BA_REL_ "GenSigTimeoutTime" BU_SG_REL_ RWPC SG_ 1041 Warn_DrvDrSwSta 1500;
BA_REL_ "GenSigTimeoutTime" BU_SG_REL_ WPC SG_ 1041 Warn_DrvDrSwSta 1500;
BA_REL_ "GenSigTimeoutTime" BU_SG_REL_ WPC2 SG_ 1041 Warn_DrvDrSwSta 1500;
BA_REL_ "GenSigTimeoutTime" BU_SG_REL_ ALBCU SG_ 1041 Warn_AsstDrSwSta 1500;
BA_REL_ "GenSigTimeoutTime" BU_SG_REL_ BLTN_CAM SG_ 1041 Warn_AsstDrSwSta 1500;
BA_REL_ "GenSigTimeoutTime" BU_SG_REL_ GW_APSU SG_ 1041 Warn_AsstDrSwSta 1500;
BA_REL_ "GenSigTimeoutTime" BU_SG_REL_ GW_RLPSU SG_ 1041 Warn_AsstDrSwSta 1500;
BA_REL_ "GenSigTimeoutTime" BU_SG_REL_ GW_RRPSU SG_ 1041 Warn_AsstDrSwSta 1500;
BA_REL_ "GenSigTimeoutTime" BU_SG_REL_ PSB SG_ 1041 Warn_AsstDrSwSta 1500;
BA_REL_ "GenSigTimeoutTime" BU_SG_REL_ RWPC SG_ 1041 Warn_AsstDrSwSta 1500;
BA_REL_ "GenSigTimeoutTime" BU_SG_REL_ WPC SG_ 1041 Warn_AsstDrSwSta 1500;
BA_REL_ "GenSigTimeoutTime" BU_SG_REL_ WPC2 SG_ 1041 Warn_AsstDrSwSta 1500;
BA_REL_ "GenSigTimeoutTime" BU_SG_REL_ BLTN_CAM SG_ 1041 Warn_HoodSwSta 1500;
BA_REL_ "GenSigTimeoutTime" BU_SG_REL_ BLTN_CAM SG_ 1041 Warn_RrLftDrSwSta 1500;
BA_REL_ "GenSigTimeoutTime" BU_SG_REL_ GW_APSU SG_ 1041 Warn_RrLftDrSwSta 1500;
BA_REL_ "GenSigTimeoutTime" BU_SG_REL_ GW_RLPSU SG_ 1041 Warn_RrLftDrSwSta 1500;
BA_REL_ "GenSigTimeoutTime" BU_SG_REL_ GW_RRPSU SG_ 1041 Warn_RrLftDrSwSta 1500;
BA_REL_ "GenSigTimeoutTime" BU_SG_REL_ RLHV SG_ 1041 Warn_RrLftDrSwSta 1500;
BA_REL_ "GenSigTimeoutTime" BU_SG_REL_ RWPC SG_ 1041 Warn_RrLftDrSwSta 1500;
BA_REL_ "GenSigTimeoutTime" BU_SG_REL_ WPC SG_ 1041 Warn_RrLftDrSwSta 1500;
BA_REL_ "GenSigTimeoutTime" BU_SG_REL_ WPC2 SG_ 1041 Warn_RrLftDrSwSta 1500;
BA_REL_ "GenSigTimeoutTime" BU_SG_REL_ BLTN_CAM SG_ 1041 Warn_RrRtDrSwSta 1500;
BA_REL_ "GenSigTimeoutTime" BU_SG_REL_ GW_APSU SG_ 1041 Warn_RrRtDrSwSta 1500;
BA_REL_ "GenSigTimeoutTime" BU_SG_REL_ GW_RLPSU SG_ 1041 Warn_RrRtDrSwSta 1500;
BA_REL_ "GenSigTimeoutTime" BU_SG_REL_ GW_RRPSU SG_ 1041 Warn_RrRtDrSwSta 1500;
BA_REL_ "GenSigTimeoutTime" BU_SG_REL_ RRHV SG_ 1041 Warn_RrRtDrSwSta 1500;
BA_REL_ "GenSigTimeoutTime" BU_SG_REL_ RWPC SG_ 1041 Warn_RrRtDrSwSta 1500;
BA_REL_ "GenSigTimeoutTime" BU_SG_REL_ WPC SG_ 1041 Warn_RrRtDrSwSta 1500;
BA_REL_ "GenSigTimeoutTime" BU_SG_REL_ WPC2 SG_ 1041 Warn_RrRtDrSwSta 1500;
BA_REL_ "GenSigTimeoutTime" BU_SG_REL_ BLTN_CAM SG_ 992 BAlarm_BglrAlrmCurrentSta 1500;
BA_REL_ "GenSigTimeoutTime" BU_SG_REL_ BLTN_CAM SG_ 1040 ICU_BS2SoC 1500;
BA_REL_ "GenSigTimeoutTime" BU_SG_REL_ SWRC SG_ 1043 IntLamp_InlTailLmpSta 1500;
BA_REL_ "GenSigTimeoutTime" BU_SG_REL_ BLTN_CAM SG_ 1043 IntLamp_InlTailLmpSta 1500;
BA_REL_ "GenSigTimeoutTime" BU_SG_REL_ WPC2 SG_ 1043 IntLamp_InlTailLmpSta 1500;
BA_REL_ "GenSigTimeoutTime" BU_SG_REL_ BLTN_CAM SG_ 1043 Lamp_TrnSigLmpLftOnReq 1500;
BA_REL_ "GenSigTimeoutTime" BU_SG_REL_ BLTN_CAM SG_ 1043 Lamp_TrnSigLmpRtOnReq 1500;
BA_REL_ "GenSigTimeoutTime" BU_SG_REL_ BLTN_CAM SG_ 1044 Trunk_TrnkTlgtSwSta 1500;
BA_REL_ "GenSigTimeoutTime" BU_SG_REL_ GW_APSU SG_ 1044 Trunk_TrnkTlgtSwSta 1500;
BA_REL_ "GenSigTimeoutTime" BU_SG_REL_ GW_RLPSU SG_ 1044 Trunk_TrnkTlgtSwSta 1500;
BA_REL_ "GenSigTimeoutTime" BU_SG_REL_ GW_RRPSU SG_ 1044 Trunk_TrnkTlgtSwSta 1500;
BA_REL_ "GenSigTimeoutTime" BU_SG_REL_ PFSU SG_ 1044 Trunk_TrnkTlgtSwSta 1500;
BA_REL_ "GenSigTimeoutTime" BU_SG_REL_ RLHV SG_ 1044 Trunk_TrnkTlgtSwSta 1500;
BA_REL_ "GenSigTimeoutTime" BU_SG_REL_ RRHV SG_ 1044 Trunk_TrnkTlgtSwSta 1500;
BA_REL_ "GenSigTimeoutTime" BU_SG_REL_ BLTN_CAM SG_ 1044 C_CrashUnlockState 1500;
BA_REL_ "GenSigTimeoutTime" BU_SG_REL_ BLTN_CAM SG_ 1186 C_PreCrankReq 0;
BA_REL_ "GenSigTimeoutTime" BU_SG_REL_ BLTN_CAM SG_ 1058 Wiper_PrkngPosSta 1500;
BA_REL_ "GenSigTimeoutTime" BU_SG_REL_ BLTN_CAM SG_ 1058 Wiper_RainSnsrSta 1500;
BA_REL_ "GenSigTimeoutTime" BU_SG_REL_ ALBCU SG_ 1195 CF_AVN_CluUSMReset 0;
BA_REL_ "GenSigTimeoutTime" BU_SG_REL_ ARS SG_ 1195 CF_AVN_CluUSMReset 0;
BA_REL_ "GenSigTimeoutTime" BU_SG_REL_ ASAU SG_ 1195 CF_AVN_CluUSMReset 0;
BA_REL_ "GenSigTimeoutTime" BU_SG_REL_ ATS SG_ 1195 CF_AVN_CluUSMReset 0;
BA_REL_ "GenSigTimeoutTime" BU_SG_REL_ BLTN_CAM SG_ 1195 CF_AVN_CluUSMReset 0;
BA_REL_ "GenSigTimeoutTime" BU_SG_REL_ DSAU SG_ 1195 CF_AVN_CluUSMReset 0;
BA_REL_ "GenSigTimeoutTime" BU_SG_REL_ GW_APSU SG_ 1195 CF_AVN_CluUSMReset 0;
BA_REL_ "GenSigTimeoutTime" BU_SG_REL_ GW_DLBCU SG_ 1195 CF_AVN_CluUSMReset 0;
BA_REL_ "GenSigTimeoutTime" BU_SG_REL_ GW_DPSU SG_ 1195 CF_AVN_CluUSMReset 0;
BA_REL_ "GenSigTimeoutTime" BU_SG_REL_ GW_RLPSU SG_ 1195 CF_AVN_CluUSMReset 0;
BA_REL_ "GenSigTimeoutTime" BU_SG_REL_ GW_RRPSU SG_ 1195 CF_AVN_CluUSMReset 0;
BA_REL_ "GenSigTimeoutTime" BU_SG_REL_ PFSU SG_ 1195 CF_AVN_CluUSMReset 0;
BA_REL_ "GenSigTimeoutTime" BU_SG_REL_ RCM SG_ 1195 CF_AVN_CluUSMReset 0;
BA_REL_ "GenSigTimeoutTime" BU_SG_REL_ RLHV SG_ 1195 CF_AVN_CluUSMReset 0;
BA_REL_ "GenSigTimeoutTime" BU_SG_REL_ RRHV SG_ 1195 CF_AVN_CluUSMReset 0;
BA_REL_ "GenSigTimeoutTime" BU_SG_REL_ RWPC SG_ 1195 CF_AVN_CluUSMReset 0;
BA_REL_ "GenSigTimeoutTime" BU_SG_REL_ SGU SG_ 1195 CF_AVN_CluUSMReset 0;
BA_REL_ "GenSigTimeoutTime" BU_SG_REL_ SHVU_FR SG_ 1195 CF_AVN_CluUSMReset 0;
BA_REL_ "GenSigTimeoutTime" BU_SG_REL_ SHVU_RR SG_ 1195 CF_AVN_CluUSMReset 0;
BA_REL_ "GenSigTimeoutTime" BU_SG_REL_ SLB SG_ 1195 CF_AVN_CluUSMReset 0;
BA_REL_ "GenSigTimeoutTime" BU_SG_REL_ WPC SG_ 1195 CF_AVN_CluUSMReset 0;
BA_REL_ "GenSigTimeoutTime" BU_SG_REL_ WPC2 SG_ 1195 CF_AVN_CluUSMReset 0;
BA_REL_ "GenSigTimeoutTime" BU_SG_REL_ BLTN_CAM SG_ 858 AST_CrashUnlockCmd 1500;
BA_REL_ "GenSigTimeoutTime" BU_SG_REL_ ALBCU SG_ 858 Warn_AsstDrSwSta_SBCM 1500;
BA_REL_ "GenSigTimeoutTime" BU_SG_REL_ ATS SG_ 858 Warn_AsstDrSwSta_SBCM 1500;
BA_REL_ "GenSigTimeoutTime" BU_SG_REL_ BLTN_CAM SG_ 858 Warn_AsstDrSwSta_SBCM 1500;
BA_REL_ "GenSigTimeoutTime" BU_SG_REL_ GW_APSU SG_ 858 Warn_AsstDrSwSta_SBCM 1500;
BA_REL_ "GenSigTimeoutTime" BU_SG_REL_ GW_RLPSU SG_ 858 Warn_AsstDrSwSta_SBCM 1500;
BA_REL_ "GenSigTimeoutTime" BU_SG_REL_ GW_RRPSU SG_ 858 Warn_AsstDrSwSta_SBCM 1500;
BA_REL_ "GenSigTimeoutTime" BU_SG_REL_ PSB SG_ 858 Warn_AsstDrSwSta_SBCM 1500;
BA_REL_ "GenSigTimeoutTime" BU_SG_REL_ RWPC SG_ 858 Warn_AsstDrSwSta_SBCM 1500;
BA_REL_ "GenSigTimeoutTime" BU_SG_REL_ WPC SG_ 858 Warn_AsstDrSwSta_SBCM 1500;
BA_REL_ "GenSigTimeoutTime" BU_SG_REL_ WPC2 SG_ 858 Warn_AsstDrSwSta_SBCM 1500;
BA_REL_ "GenSigTimeoutTime" BU_SG_REL_ BLTN_CAM SG_ 977 SMK_TrmnlCtrlGrpStaBDC 1500;
BA_REL_ "GenSigTimeoutTime" BU_SG_REL_ BLTN_CAM SG_ 977 SMK_TrmnlCtrlGrpStaBDCEV 1500;
BA_REL_ "GenSigTimeoutTime" BU_SG_REL_ BLTN_CAM SG_ 977 SMK_TrmnlCtrlStaBDCEV 1500;
BA_REL_ "GenSigTimeoutTime" BU_SG_REL_ BLTN_CAM SG_ 862 RL_CrashUnlockCmd 1500;
BA_REL_ "GenSigTimeoutTime" BU_SG_REL_ ATS SG_ 862 Warn_RrLftDrSwSta_SBCM 1500;
BA_REL_ "GenSigTimeoutTime" BU_SG_REL_ BLTN_CAM SG_ 862 Warn_RrLftDrSwSta_SBCM 1500;
BA_REL_ "GenSigTimeoutTime" BU_SG_REL_ GW_APSU SG_ 862 Warn_RrLftDrSwSta_SBCM 1500;
BA_REL_ "GenSigTimeoutTime" BU_SG_REL_ GW_RLPSU SG_ 862 Warn_RrLftDrSwSta_SBCM 1500;
BA_REL_ "GenSigTimeoutTime" BU_SG_REL_ GW_RRPSU SG_ 862 Warn_RrLftDrSwSta_SBCM 1500;
BA_REL_ "GenSigTimeoutTime" BU_SG_REL_ RWPC SG_ 862 Warn_RrLftDrSwSta_SBCM 1500;
BA_REL_ "GenSigTimeoutTime" BU_SG_REL_ WPC SG_ 862 Warn_RrLftDrSwSta_SBCM 1500;
BA_REL_ "GenSigTimeoutTime" BU_SG_REL_ WPC2 SG_ 862 Warn_RrLftDrSwSta_SBCM 1500;
BA_REL_ "GenSigTimeoutTime" BU_SG_REL_ CGW_CCU SG_ 983 BLTN_CAM_SWVerMajor 1500;
BA_REL_ "GenSigTimeoutTime" BU_SG_REL_ CGW_CCU SG_ 983 BLTN_CAM_SWVerMinor2 1500;
BA_REL_ "GenSigTimeoutTime" BU_SG_REL_ CGW_CCU SG_ 983 BLTN_CAM_SWVerMinor3 1500;
BA_REL_ "GenSigTimeoutTime" BU_SG_REL_ CGW_CCU SG_ 983 BLTN_CAM_SD_Card_Manufacturer 1500;
BA_REL_ "GenSigTimeoutTime" BU_SG_REL_ CGW_CCU SG_ 983 BLTN_CAM_SD_Card_Cap_Class 1500;
BA_REL_ "GenSigTimeoutTime" BU_SG_REL_ CGW_CCU SG_ 983 BLTN_CAM_SWVerMinor1 1500;
BA_REL_ "GenSigTimeoutTime" BU_SG_REL_ BLTN_CAM SG_ 721 HU_DR_Altitude 1500;
BA_REL_ "GenSigTimeoutTime" BU_SG_REL_ BLTN_CAM SG_ 722 HU_DR_Latitude 1500;
BA_REL_ "GenSigTimeoutTime" BU_SG_REL_ BLTN_CAM SG_ 722 HU_DR_Longitude 1500;
BA_REL_ "GenSigTimeoutTime" BU_SG_REL_ BLTN_CAM SG_ 723 HU_DR_Heading 1500;
BA_REL_ "GenSigTimeoutTime" BU_SG_REL_ BLTN_CAM SG_ 1079 CTM_TrailerAct 1500;
BA_REL_ "GenSigTimeoutTime" BU_SG_REL_ BLTN_CAM SG_ 1076 IAU_ProfileIDRVal 1500;
BA_REL_ "GenSigTimeoutTime" BU_SG_REL_ GW_DLBCU SG_ 1076 IAU_ProfileIDRVal 1500;
BA_REL_ "GenSigTimeoutTime" BU_SG_REL_ GW_DPSU SG_ 1076 IAU_ProfileIDRVal 1500;
BA_REL_ "GenSigTimeoutTime" BU_SG_REL_ RCM SG_ 1076 IAU_ProfileIDRVal 1500;
BA_REL_ "GenSigTimeoutTime" BU_SG_REL_ RWPC SG_ 1076 IAU_ProfileIDRVal 1500;
BA_REL_ "GenSigTimeoutTime" BU_SG_REL_ SGU SG_ 1076 IAU_ProfileIDRVal 1500;
BA_REL_ "GenSigTimeoutTime" BU_SG_REL_ WPC SG_ 1076 IAU_ProfileIDRVal 1500;
BA_REL_ "GenSigTimeoutTime" BU_SG_REL_ WPC2 SG_ 1076 IAU_ProfileIDRVal 1500;
VAL_ 2214658050 ENG_AccelPdlVal 0 "Accelerator Pedal not activated" 1022 "Accelerator Pedal fully activated" 1023 "Accelerator Pedal is defective (fail state) or Non-ETC system (APS is not installed), Error indicator" ;
VAL_ 2210462210 HCU_HevRdySta 0 "HEV not ready" 1 "HEV Drivable" 2 "Not used" 3 "Error Indicator" ;
VAL_ 1167 ICU_BattAutoCutPreWrng 0 "No Warning" 1 "Warning" 2 "Not Used" 3 "Invalid" ;
VAL_ 763 Warn_HoodSwSta_SBCM 0 "Off" 1 "On" 2 "RESERVED" 3 "Error Indicator" ;
VAL_ 763 Hood_TypeOption 0 "Off (Mechanical hood latch is applied)" 1 "On (E-Hood latch is applied)" 2 "RESERVED" 3 "Error Indicator" ;
VAL_ 1048 DriveTypeOption 0 "Left Handle Drive Type" 1 "Right Handle Drive Type" 2 "RESERVED" 3 "Error Indicator" ;
VAL_ 1048 ICU_PowerAutoCutModSta 0 "Factory Mode (default)" 1 "Dealer Mode" 2 "Customer Mode" 3 "Error Indicator" ;
VAL_ 1050 Lamp_ExtrnlTailLmpOnReq 0 "Off" 1 "On" 2 "Not Used" 3 "Error Indicator" ;
VAL_ 1002 BLTN_CAM_HU_UI_Mode 0 "HU UI mode." 1 "BLTN_CAM mode" 2 "Preparing BLTN_CAM Mode" 3 "BLTN_CAM Setting Mode" 4 "RESERVED" 5 "RESERVED" 6 "RESERVED" 7 "RESERVED" 8 "RESERVED" 9 "RESERVED" 10 "RESERVED" 11 "RESERVED" 12 "RESERVED" 13 "BLTN_CAM Not Ready to be HU UI Mode" 14 "BLTN_CAM is in Error mode." 15 "Invalid" ;
VAL_ 1002 BLTN_CAM_SD_Format_Op_State 0 "Default" 1 "Formatting" 2 "Format Complete." 3 "invalid" ;
VAL_ 1002 BLTN_CAM_PEV_Recorded 0 "Default" 1 "Off" 2 "Park Event Recorded" 3 "invalid" ;
VAL_ 1002 BLTN_CAM_PEV_Count 0 "0x0x0~0xC8:the number of the Park Event Record(0~200)" 200 "0x0x0~0xC8:the number of the Park Event Record(0~200)" 201 "Reserved" 202 "Reserved" 203 "Reserved" 204 "Reserved" 205 "Reserved" 206 "Reserved" 207 "Reserved" 208 "Reserved" 209 "Reserved" 210 "Reserved" 211 "Reserved" 212 "Reserved" 213 "Reserved" 214 "Reserved" 215 "Reserved" 216 "Reserved" 217 "Reserved" 218 "Reserved" 219 "Reserved" 220 "Reserved" 221 "Reserved" 222 "Reserved" 223 "Reserved" 224 "Reserved" 225 "Reserved" 226 "Reserved" 227 "Reserved" 228 "Reserved" 229 "Reserved" 230 "Reserved" 231 "Reserved" 232 "Reserved" 233 "Reserved" 234 "Reserved" 235 "Reserved" 236 "Reserved" 237 "Reserved" 238 "Reserved" 239 "Reserved" 240 "Reserved" 241 "Reserved" 242 "Reserved" 243 "Reserved" 244 "Reserved" 245 "Reserved" 246 "Reserved" 247 "Reserved" 248 "Reserved" 249 "Reserved" 250 "Reserved" 251 "Reserved" 252 "Reserved" 253 "Over than 200 count" 254 "the park event record is not recorded" 255 "invalid" ;
VAL_ 1002 BLTN_CAM_Ind_Req 0 "Default" 1 "Built-in Cam System or Camera Error" 2 "Manual Recording or Event Recording" 3 "Time-lapse Recording" 4 "Built-in Cam SD Card Replace Warning or SD Card Error" 5 "On while Driving Recording" 6 "On while Parked Recording" 7 "Smartphone Connected" 8 "RESERVED" 9 "RESERVED" 10 "RESERVED" 11 "RESERVED" 12 "RESERVED" 13 "RESERVED" 14 "RESERVED" 15 "RESERVED" 16 "RESERVED" 17 "RESERVED" 18 "RESERVED" 19 "RESERVED" 20 "RESERVED" 21 "RESERVED" 22 "RESERVED" 23 "RESERVED" 24 "RESERVED" 25 "RESERVED" 26 "RESERVED" 27 "RESERVED" 28 "RESERVED" 29 "RESERVED" 30 "RESERVED" 31 "Invalid" ;
VAL_ 1002 BLTN_CAM_LVDS_Mode_State 0 "Front and Rear Camera" 1 "Front Camera for AR Navi." 2 "Built-In Cam Engineer Mode" 3 "Reserved" ;
VAL_ 1002 BLTN_CAM_PrkOp_Termiate_Info 0 "Default" 1 "Park operation terminated earlier than user set because of Bat. SoC" 2 "Park operation terminated earlier than user set because of SD Card Problem" 3 "Park operation terminated earlier than user set because of Built-in Cam internal Error" 4 "Park operation terminated earlier than user set because of SD Card removed or not detected" 5 "Park operation started because of SD Card inserted" 6 "Park operation terminate on time which user set." 7 "Invalid" ;
VAL_ 1002 BLTN_CAM_DEV_Recorded 0 "Default" 1 "Off" 2 "Drive Event Recorded" 3 "Invalid" ;
VAL_ 1002 BLTN_CAM_DEV_Count 0 "0x0x0~0xC8:the number of the Drive Event Record(0~200)" 200 "0x0x0~0xC8:the number of the Drive Event Record(0~200)" 201 "RESERVED" 202 "RESERVED" 203 "RESERVED" 204 "RESERVED" 205 "RESERVED" 206 "RESERVED" 207 "RESERVED" 208 "RESERVED" 209 "RESERVED" 210 "RESERVED" 211 "RESERVED" 212 "RESERVED" 213 "RESERVED" 214 "RESERVED" 215 "RESERVED" 216 "RESERVED" 217 "RESERVED" 218 "RESERVED" 219 "RESERVED" 220 "RESERVED" 221 "RESERVED" 222 "RESERVED" 223 "RESERVED" 224 "RESERVED" 225 "RESERVED" 226 "RESERVED" 227 "RESERVED" 228 "RESERVED" 229 "RESERVED" 230 "RESERVED" 231 "RESERVED" 232 "RESERVED" 233 "RESERVED" 234 "RESERVED" 235 "RESERVED" 236 "RESERVED" 237 "RESERVED" 238 "RESERVED" 239 "RESERVED" 240 "RESERVED" 241 "RESERVED" 242 "RESERVED" 243 "RESERVED" 244 "RESERVED" 245 "RESERVED" 246 "RESERVED" 247 "RESERVED" 248 "RESERVED" 249 "RESERVED" 250 "RESERVED" 251 "RESERVED" 252 "RESERVED" 254 "the drive event record is not recordable" 255 "Invalid" ;
VAL_ 1002 BLTN_CAM_Display 0 "HU mode" 1 "Built-in Cam mode" 2 "popup mode" 3 "Built-in Cam mode Terminate Request by Home-button" 4 "Built-in Cam mode Terminate Request by Back-button" 5 "Built-in Cam update mode" 6 "Ready to update" 7 "Update complete" 8 "USB removed" 9 "Update fail (USB error)" 10 "Reserved" 11 "Reserved" 12 "Reserved" 13 "Reserved" 14 "Built-in Cam is in error mode" 15 "Invalid" ;
VAL_ 1002 BLTN_CAM_WiFi_State 0 "Off" 1 "On, Ready to Connect Mobile Phone." 2 "On, Mobile Phone Connected." 3 "Off - Password is not Set." 4 "Reserved" 5 "Reserved" 6 "Reserved" 7 "Reserved" 8 "Reserved" 9 "Reserved" 10 "Reserved" 11 "Reserved" 12 "Reserved" 13 "Reserved" 14 "Reserved" 15 "invalid" ;
VAL_ 1041 ICU_MtGearPosRSta 0 "Off" 1 "On" 2 "RESERVED" 3 "RESERVED" ;
VAL_ 1041 Warn_DrvDrSwSta 0 "Close" 1 "Open" 2 "Not Used" 3 "Error Indicator" ;
VAL_ 1041 Warn_AsstDrSwSta 0 "Close" 1 "Open" 2 "Not Used" 3 "Error Indicator" ;
VAL_ 1041 Warn_HoodSwSta 0 "Off" 1 "On" 2 "Not Used" 3 "Error Indicator" ;
VAL_ 1041 Warn_RrLftDrSwSta 0 "Close" 1 "Open" 2 "Not Used" 3 "Error Indicator" ;
VAL_ 1041 Warn_RrRtDrSwSta 0 "Close" 1 "Open" 2 "Not Used" 3 "Error Indicator" ;
VAL_ 992 BAlarm_BglrAlrmCurrentSta 0 "Off" 1 "DisArm" 2 "Arm" 3 "PreArm" 4 "ArmWait" 5 "ArmHold(Trunk)" 6 "ReArm" 7 "AutoLockTimer1" 8 "AutoLockTimer2" 9 "Alarm" 10 "Default" 11 "AutoLockTimer3(Tailgate)" 12 "Reserved" 13 "Reserved" 14 "Not Used" 15 "Error Indicator" ;
VAL_ 1040 ICU_BS2SoC 0 "0x0x00~0x64:0% ~ 100 %" 100 "0x0x00~0x64:0% ~ 100 %" 101 "0x65~0xFE:Invalid" 254 "0x65~0xFE:Invalid" 255 "Error" ;
VAL_ 1043 IntLamp_InlTailLmpSta 0 "Off" 1 "On" 2 "Not Used" 3 "Error Indicator" ;
VAL_ 1043 Lamp_TrnSigLmpLftOnReq 0 "Inactive" 1 "Active Off(Flasher Off)" 2 "Active On(Flasher On)" 3 "RESERVED" ;
VAL_ 1043 Lamp_TrnSigLmpRtOnReq 0 "Inactive" 1 "Active Off(Flasher Off)" 2 "Active On(Flasher On)" 3 "RESERVED" ;
VAL_ 1044 Trunk_TrnkTlgtSwSta 0 "Close(Full Lock)" 1 "Open(Not Full Lock)" 2 "Not Used" 3 "Error Indicator" ;
VAL_ 1044 C_CrashUnlockState 0 "Off" 1 "Unlock(Crash)" 2 "RESERVED" 3 "RESERVED" ;
VAL_ 1186 C_PreCrankReq 0 "Default" 1 "Req On" 2 "Not Support" 3 "Invalid" ;
VAL_ 1058 Wiper_PrkngPosSta 0 "else" 1 "Parking Position" 2 "Not Used" 3 "Error Indicator" ;
VAL_ 1058 Wiper_RainSnsrSta 0 "OFF" 1 "Rain Detected" 2 "Low" 3 "High" 4 "Fault 1" 5 "Reserved" 6 "Reserved" 7 "Reserved" 8 "Reserved" 9 "Reserved" 10 "Reserved" 11 "Reserved" 12 "Reserved" 13 "Reserved" 14 "Not Used" 15 "Error Indicator" ;
VAL_ 1195 CF_AVN_CluUSMReset 0 "Default" 1 "USM Reset" 2 "Reserved" 3 "Invalid" ;
VAL_ 858 AST_CrashUnlockCmd 0 "Off" 1 "Unlock (Crash)" ;
VAL_ 858 Warn_AsstDrSwSta_SBCM 0 "Close" 1 "Open" 2 "RESERVED" 3 "Error Indicator" ;
VAL_ 977 SMK_TrmnlCtrlGrpStaBDC 0 "Off" 1 "Acc" 2 "Ign" 3 "Cranking" 4 "Engine Running" 5 "RESERVED" 6 "RESERVED" 7 "Error Indicator" ;
VAL_ 977 SMK_TrmnlCtrlGrpStaBDCEV 0 "Off" 1 "Standby" 2 "Cranking" 3 "Ready" 4 "RESERVED" 5 "RESERVED" 6 "RESERVED" 7 "Error Indicator" ;
VAL_ 977 SMK_TrmnlCtrlStaBDCEV 0 "Off" 1 "Off_AuthWaiting" 2 "Off_CrankingAuthWaiting" 3 "Off_ESCLUnlockWaiting" 4 "Standby" 5 "Standby_ESCLUnlockWaiting" 6 "Standby_AuthWaiting" 7 "Standby_CrankingWait" 8 "Cranking" 9 "Ready" 10 "RESERVED" 11 "RESERVED" 12 "RESERVED" 13 "RESERVED" 14 "RESERVED" 15 "RESERVED" 16 "RESERVED" 17 "RESERVED" 18 "RESERVED" 19 "RESERVED" 20 "RESERVED" 21 "RESERVED" 22 "RESERVED" 23 "RESERVED" 24 "RESERVED" 25 "RESERVED" 26 "RESERVED" 27 "RESERVED" 28 "RESERVED" 29 "RESERVED" 30 "RESERVED" 31 "Error Indicator" ;
VAL_ 862 RL_CrashUnlockCmd 0 "Off" 1 "Unlock(Crash)" ;
VAL_ 862 Warn_RrLftDrSwSta_SBCM 0 "Close" 1 "Open" 2 "RESERVED" 3 "Error Indicator" ;
VAL_ 983 BLTN_CAM_SWVerMajor 0 "ASCII Code Value (HEX)" 1 "ASCII Code Value (HEX)" 2 "ASCII Code Value (HEX)" 3 "ASCII Code Value (HEX)" 4 "ASCII Code Value (HEX)" 5 "ASCII Code Value (HEX)" 6 "ASCII Code Value (HEX)" 7 "ASCII Code Value (HEX)" 8 "ASCII Code Value (HEX)" 9 "ASCII Code Value (HEX)" 10 "ASCII Code Value (HEX)" 11 "ASCII Code Value (HEX)" 12 "ASCII Code Value (HEX)" 13 "ASCII Code Value (HEX)" 14 "ASCII Code Value (HEX)" 15 "ASCII Code Value (HEX)" ;
VAL_ 983 BLTN_CAM_SWVerMinor2 0 "Minor2 verion, 0~99 dec" 1 "Minor2 verion, 0~99 dec" 2 "Minor2 verion, 0~99 dec" 3 "Minor2 verion, 0~99 dec" 4 "Minor2 verion, 0~99 dec" 5 "Minor2 verion, 0~99 dec" 6 "Minor2 verion, 0~99 dec" 7 "Minor2 verion, 0~99 dec" 8 "Minor2 verion, 0~99 dec" 9 "Minor2 verion, 0~99 dec" 10 "Minor2 verion, 0~99 dec" 11 "Minor2 verion, 0~99 dec" 12 "Minor2 verion, 0~99 dec" 13 "Minor2 verion, 0~99 dec" 14 "Minor2 verion, 0~99 dec" 15 "Minor2 verion, 0~99 dec" 16 "Minor2 verion, 0~99 dec" 17 "Minor2 verion, 0~99 dec" 18 "Minor2 verion, 0~99 dec" 19 "Minor2 verion, 0~99 dec" 20 "Minor2 verion, 0~99 dec" 21 "Minor2 verion, 0~99 dec" 22 "Minor2 verion, 0~99 dec" 23 "Minor2 verion, 0~99 dec" 24 "Minor2 verion, 0~99 dec" 25 "Minor2 verion, 0~99 dec" 26 "Minor2 verion, 0~99 dec" 27 "Minor2 verion, 0~99 dec" 28 "Minor2 verion, 0~99 dec" 29 "Minor2 verion, 0~99 dec" 30 "Minor2 verion, 0~99 dec" 31 "Minor2 verion, 0~99 dec" 32 "Minor2 verion, 0~99 dec" 33 "Minor2 verion, 0~99 dec" 34 "Minor2 verion, 0~99 dec" 35 "Minor2 verion, 0~99 dec" 36 "Minor2 verion, 0~99 dec" 37 "Minor2 verion, 0~99 dec" 38 "Minor2 verion, 0~99 dec" 39 "Minor2 verion, 0~99 dec" 40 "Minor2 verion, 0~99 dec" 41 "Minor2 verion, 0~99 dec" 42 "Minor2 verion, 0~99 dec" 43 "Minor2 verion, 0~99 dec" 44 "Minor2 verion, 0~99 dec" 45 "Minor2 verion, 0~99 dec" 46 "Minor2 verion, 0~99 dec" 47 "Minor2 verion, 0~99 dec" 48 "Minor2 verion, 0~99 dec" 49 "Minor2 verion, 0~99 dec" 50 "Minor2 verion, 0~99 dec" 51 "Minor2 verion, 0~99 dec" 52 "Minor2 verion, 0~99 dec" 53 "Minor2 verion, 0~99 dec" 54 "Minor2 verion, 0~99 dec" 55 "Minor2 verion, 0~99 dec" 56 "Minor2 verion, 0~99 dec" 57 "Minor2 verion, 0~99 dec" 58 "Minor2 verion, 0~99 dec" 59 "Minor2 verion, 0~99 dec" 60 "Minor2 verion, 0~99 dec" 61 "Minor2 verion, 0~99 dec" 62 "Minor2 verion, 0~99 dec" 63 "Minor2 verion, 0~99 dec" 64 "Minor2 verion, 0~99 dec" 65 "Minor2 verion, 0~99 dec" 66 "Minor2 verion, 0~99 dec" 67 "Minor2 verion, 0~99 dec" 68 "Minor2 verion, 0~99 dec" 69 "Minor2 verion, 0~99 dec" 70 "Minor2 verion, 0~99 dec" 71 "Minor2 verion, 0~99 dec" 72 "Minor2 verion, 0~99 dec" 73 "Minor2 verion, 0~99 dec" 74 "Minor2 verion, 0~99 dec" 75 "Minor2 verion, 0~99 dec" 76 "Minor2 verion, 0~99 dec" 77 "Minor2 verion, 0~99 dec" 78 "Minor2 verion, 0~99 dec" 79 "Minor2 verion, 0~99 dec" 80 "Minor2 verion, 0~99 dec" 81 "Minor2 verion, 0~99 dec" 82 "Minor2 verion, 0~99 dec" 83 "Minor2 verion, 0~99 dec" 84 "Minor2 verion, 0~99 dec" 85 "Minor2 verion, 0~99 dec" 86 "Minor2 verion, 0~99 dec" 87 "Minor2 verion, 0~99 dec" 88 "Minor2 verion, 0~99 dec" 89 "Minor2 verion, 0~99 dec" 90 "Minor2 verion, 0~99 dec" 91 "Minor2 verion, 0~99 dec" 92 "Minor2 verion, 0~99 dec" 93 "Minor2 verion, 0~99 dec" 94 "Minor2 verion, 0~99 dec" 95 "Minor2 verion, 0~99 dec" 96 "Minor2 verion, 0~99 dec" 97 "Minor2 verion, 0~99 dec" 98 "Minor2 verion, 0~99 dec" 99 "Minor2 verion, 0~99 dec" 100 "Reserved" 101 "Reserved" 102 "Reserved" 103 "Reserved" 104 "Reserved" 105 "Reserved" 106 "Reserved" 107 "Reserved" 108 "Reserved" 109 "Reserved" 110 "Reserved" 111 "Reserved" 112 "Reserved" 113 "Reserved" 114 "Reserved" 115 "Reserved" 116 "Reserved" 117 "Reserved" 118 "Reserved" 119 "Reserved" 120 "Reserved" 121 "Reserved" 122 "Reserved" 123 "Reserved" 124 "Reserved" 125 "Reserved" 126 "Reserved" 127 "Invalid" ;
VAL_ 983 BLTN_CAM_SWVerMinor3 0 "Minor3 version, 0~99 dec" 1 "Minor3 version, 0~99 dec" 2 "Minor3 version, 0~99 dec" 3 "Minor3 version, 0~99 dec" 4 "Minor3 version, 0~99 dec" 5 "Minor3 version, 0~99 dec" 6 "Minor3 version, 0~99 dec" 7 "Minor3 version, 0~99 dec" 8 "Minor3 version, 0~99 dec" 9 "Minor3 version, 0~99 dec" 10 "Minor3 version, 0~99 dec" 11 "Minor3 version, 0~99 dec" 12 "Minor3 version, 0~99 dec" 13 "Minor3 version, 0~99 dec" 14 "Minor3 version, 0~99 dec" 15 "Minor3 version, 0~99 dec" 16 "Minor3 version, 0~99 dec" 17 "Minor3 version, 0~99 dec" 18 "Minor3 version, 0~99 dec" 19 "Minor3 version, 0~99 dec" 20 "Minor3 version, 0~99 dec" 21 "Minor3 version, 0~99 dec" 22 "Minor3 version, 0~99 dec" 23 "Minor3 version, 0~99 dec" 24 "Minor3 version, 0~99 dec" 25 "Minor3 version, 0~99 dec" 26 "Minor3 version, 0~99 dec" 27 "Minor3 version, 0~99 dec" 28 "Minor3 version, 0~99 dec" 29 "Minor3 version, 0~99 dec" 30 "Minor3 version, 0~99 dec" 31 "Minor3 version, 0~99 dec" 32 "Minor3 version, 0~99 dec" 33 "Minor3 version, 0~99 dec" 34 "Minor3 version, 0~99 dec" 35 "Minor3 version, 0~99 dec" 36 "Minor3 version, 0~99 dec" 37 "Minor3 version, 0~99 dec" 38 "Minor3 version, 0~99 dec" 39 "Minor3 version, 0~99 dec" 40 "Minor3 version, 0~99 dec" 41 "Minor3 version, 0~99 dec" 42 "Minor3 version, 0~99 dec" 43 "Minor3 version, 0~99 dec" 44 "Minor3 version, 0~99 dec" 45 "Minor3 version, 0~99 dec" 46 "Minor3 version, 0~99 dec" 47 "Minor3 version, 0~99 dec" 48 "Minor3 version, 0~99 dec" 49 "Minor3 version, 0~99 dec" 50 "Minor3 version, 0~99 dec" 51 "Minor3 version, 0~99 dec" 52 "Minor3 version, 0~99 dec" 53 "Minor3 version, 0~99 dec" 54 "Minor3 version, 0~99 dec" 55 "Minor3 version, 0~99 dec" 56 "Minor3 version, 0~99 dec" 57 "Minor3 version, 0~99 dec" 58 "Minor3 version, 0~99 dec" 59 "Minor3 version, 0~99 dec" 60 "Minor3 version, 0~99 dec" 61 "Minor3 version, 0~99 dec" 62 "Minor3 version, 0~99 dec" 63 "Minor3 version, 0~99 dec" 64 "Minor3 version, 0~99 dec" 65 "Minor3 version, 0~99 dec" 66 "Minor3 version, 0~99 dec" 67 "Minor3 version, 0~99 dec" 68 "Minor3 version, 0~99 dec" 69 "Minor3 version, 0~99 dec" 70 "Minor3 version, 0~99 dec" 71 "Minor3 version, 0~99 dec" 72 "Minor3 version, 0~99 dec" 73 "Minor3 version, 0~99 dec" 74 "Minor3 version, 0~99 dec" 75 "Minor3 version, 0~99 dec" 76 "Minor3 version, 0~99 dec" 77 "Minor3 version, 0~99 dec" 78 "Minor3 version, 0~99 dec" 79 "Minor3 version, 0~99 dec" 80 "Minor3 version, 0~99 dec" 81 "Minor3 version, 0~99 dec" 82 "Minor3 version, 0~99 dec" 83 "Minor3 version, 0~99 dec" 84 "Minor3 version, 0~99 dec" 85 "Minor3 version, 0~99 dec" 86 "Minor3 version, 0~99 dec" 87 "Minor3 version, 0~99 dec" 88 "Minor3 version, 0~99 dec" 89 "Minor3 version, 0~99 dec" 90 "Minor3 version, 0~99 dec" 91 "Minor3 version, 0~99 dec" 92 "Minor3 version, 0~99 dec" 93 "Minor3 version, 0~99 dec" 94 "Minor3 version, 0~99 dec" 95 "Minor3 version, 0~99 dec" 96 "Minor3 version, 0~99 dec" 97 "Minor3 version, 0~99 dec" 98 "Minor3 version, 0~99 dec" 99 "Minor3 version, 0~99 dec" 100 "Reserved" 101 "Reserved" 102 "Reserved" 103 "Reserved" 104 "Reserved" 105 "Reserved" 106 "Reserved" 107 "Reserved" 108 "Reserved" 109 "Reserved" 110 "Reserved" 111 "Reserved" 112 "Reserved" 113 "Reserved" 114 "Reserved" 115 "Reserved" 116 "Reserved" 117 "Reserved" 118 "Reserved" 119 "Reserved" 120 "Reserved" 121 "Reserved" 122 "Reserved" 123 "Reserved" 124 "Reserved" 125 "Reserved" 126 "Reserved" 127 "Invalid" ;
VAL_ 983 BLTN_CAM_SD_Card_Manufacturer 0 "SD Card not found" 1 "Micron-Genuine part" 2 "RESERVED" 3 "RESERVED" 4 "RESERVED" 5 "RESERVED" 6 "Unknown" 7 "Invalid" ;
VAL_ 983 BLTN_CAM_SD_Card_Cap_Class 0 "SD Card not found" 1 "64Gbyte Class" 2 "128Gbyte Class" 3 "256Gbyte Class" 4 "512Gbyte Class" 5 "1Tbyte Class" 6 "2Tbyte Class" 7 "Invalid" ;
VAL_ 983 BLTN_CAM_SWVerMinor1 0 "Minor1 version, 0~99 dec" 1 "Minor1 version, 0~99 dec" 2 "Minor1 version, 0~99 dec" 3 "Minor1 version, 0~99 dec" 4 "Minor1 version, 0~99 dec" 5 "Minor1 version, 0~99 dec" 6 "Minor1 version, 0~99 dec" 7 "Minor1 version, 0~99 dec" 8 "Minor1 version, 0~99 dec" 9 "Minor1 version, 0~99 dec" 10 "Minor1 version, 0~99 dec" 11 "Minor1 version, 0~99 dec" 12 "Minor1 version, 0~99 dec" 13 "Minor1 version, 0~99 dec" 14 "Minor1 version, 0~99 dec" 15 "Minor1 version, 0~99 dec" 16 "Minor1 version, 0~99 dec" 17 "Minor1 version, 0~99 dec" 18 "Minor1 version, 0~99 dec" 19 "Minor1 version, 0~99 dec" 20 "Minor1 version, 0~99 dec" 21 "Minor1 version, 0~99 dec" 22 "Minor1 version, 0~99 dec" 23 "Minor1 version, 0~99 dec" 24 "Minor1 version, 0~99 dec" 25 "Minor1 version, 0~99 dec" 26 "Minor1 version, 0~99 dec" 27 "Minor1 version, 0~99 dec" 28 "Minor1 version, 0~99 dec" 29 "Minor1 version, 0~99 dec" 30 "Minor1 version, 0~99 dec" 31 "Minor1 version, 0~99 dec" 32 "Minor1 version, 0~99 dec" 33 "Minor1 version, 0~99 dec" 34 "Minor1 version, 0~99 dec" 35 "Minor1 version, 0~99 dec" 36 "Minor1 version, 0~99 dec" 37 "Minor1 version, 0~99 dec" 38 "Minor1 version, 0~99 dec" 39 "Minor1 version, 0~99 dec" 40 "Minor1 version, 0~99 dec" 41 "Minor1 version, 0~99 dec" 42 "Minor1 version, 0~99 dec" 43 "Minor1 version, 0~99 dec" 44 "Minor1 version, 0~99 dec" 45 "Minor1 version, 0~99 dec" 46 "Minor1 version, 0~99 dec" 47 "Minor1 version, 0~99 dec" 48 "Minor1 version, 0~99 dec" 49 "Minor1 version, 0~99 dec" 50 "Minor1 version, 0~99 dec" 51 "Minor1 version, 0~99 dec" 52 "Minor1 version, 0~99 dec" 53 "Minor1 version, 0~99 dec" 54 "Minor1 version, 0~99 dec" 55 "Minor1 version, 0~99 dec" 56 "Minor1 version, 0~99 dec" 57 "Minor1 version, 0~99 dec" 58 "Minor1 version, 0~99 dec" 59 "Minor1 version, 0~99 dec" 60 "Minor1 version, 0~99 dec" 61 "Minor1 version, 0~99 dec" 62 "Minor1 version, 0~99 dec" 63 "Minor1 version, 0~99 dec" 64 "Minor1 version, 0~99 dec" 65 "Minor1 version, 0~99 dec" 66 "Minor1 version, 0~99 dec" 67 "Minor1 version, 0~99 dec" 68 "Minor1 version, 0~99 dec" 69 "Minor1 version, 0~99 dec" 70 "Minor1 version, 0~99 dec" 71 "Minor1 version, 0~99 dec" 72 "Minor1 version, 0~99 dec" 73 "Minor1 version, 0~99 dec" 74 "Minor1 version, 0~99 dec" 75 "Minor1 version, 0~99 dec" 76 "Minor1 version, 0~99 dec" 77 "Minor1 version, 0~99 dec" 78 "Minor1 version, 0~99 dec" 79 "Minor1 version, 0~99 dec" 80 "Minor1 version, 0~99 dec" 81 "Minor1 version, 0~99 dec" 82 "Minor1 version, 0~99 dec" 83 "Minor1 version, 0~99 dec" 84 "Minor1 version, 0~99 dec" 85 "Minor1 version, 0~99 dec" 86 "Minor1 version, 0~99 dec" 87 "Minor1 version, 0~99 dec" 88 "Minor1 version, 0~99 dec" 89 "Minor1 version, 0~99 dec" 90 "Minor1 version, 0~99 dec" 91 "Minor1 version, 0~99 dec" 92 "Minor1 version, 0~99 dec" 93 "Minor1 version, 0~99 dec" 94 "Minor1 version, 0~99 dec" 95 "Minor1 version, 0~99 dec" 96 "Minor1 version, 0~99 dec" 97 "Minor1 version, 0~99 dec" 98 "Minor1 version, 0~99 dec" 99 "Minor1 version, 0~99 dec" 100 "Reserved" 101 "Reserved" 102 "Reserved" 103 "Reserved" 104 "Reserved" 105 "Reserved" 106 "Reserved" 107 "Reserved" 108 "Reserved" 109 "Reserved" 110 "Reserved" 111 "Reserved" 112 "Reserved" 113 "Reserved" 114 "Reserved" 115 "Reserved" 116 "Reserved" 117 "Reserved" 118 "Reserved" 119 "Reserved" 120 "Reserved" 121 "Reserved" 122 "Reserved" 123 "Reserved" 124 "Reserved" 125 "Reserved" 126 "Reserved" 127 "Invalid" ;
VAL_ 2160080132 VCU_GearPosStaDisp 0 "P" 1 "B" 2 "Not Used" 3 "Not Used" 4 "Not Used" 5 "D" 6 "N" 7 "R" 8 "Not Used" 9 "Not Display at Cluster" 10 "Reserved" 11 "Reserved" 12 "Manual Shift Mode on Retromode" 13 "Reserved" 14 "Intermediate Position" 15 "Fault" ;
VAL_ 2160080129 VCU_EvDrvRdySta 0 "None" 1 "EV Drivable" 2 "Not used" 3 "Error Indicator" ;
VAL_ 2160080129 VCU_GearPosSta 0 "P" 1 "B" 2 "Not Used" 3 "Not Used" 4 "Not Used" 5 "D" 6 "N" 7 "R" 8 "Not Used" 9 "Not Display at Cluster" 10 "Reserved" 11 "Reserved" 12 "Reserved" 13 "Reserved" 14 "Intermediate Position" 15 "Fault" ;
VAL_ 2160080129 VCU_AccPedDepVal 255 "Error Indicator" ;
VAL_ 1079 CTM_TrailerAct 0 "Not Connected" 1 "Connected" 2 "Reserved" 3 "Invaild" ;
VAL_ 2164278529 HTCU_GearSlctrDis 0 "P" 1 "L" 2 "2" 3 "3" 4 "DS Mode" 5 "D" 6 "N" 7 "R" 8 "Sports mode / Manual Shift" 9 "Not display at Cluster" 10 "Sub-Rom Communication" 11 "Sub-Rom Communication Error" 12 "Paddle shift (D-Position)" 13 "Not used" 14 "Intermediate Position" 15 "Fault" ;
VAL_ 1076 IAU_ProfileIDRVal 0 "Default" 1 "Guest" 2 "Profile1" 3 "Profile2" 4 "Profile3" 5 "Profile4" 6 "Profile5" 7 "Profile6" 8 "Profile7" 9 "Profile8" 10 "Profile9" 11 "RESERVED" 12 "RESERVED" 13 "RESERVED" 14 "RESERVED" 15 "INVALID" ;
VAL_ 1301 Destination_WPC2 0 "0x0x0~0xFF:NM Source Node ID" 255 "0x0x0~0xFF:NM Source Node ID" ;
VAL_ 1301 NMCommandCode_WPC2 1 "Alive" 2 "Ring" 3 "RESERVED" 4 "Limphome" 5 "0x5~0xFF:RESERVED" 255 "0x5~0xFF:RESERVED" ;
VAL_ 1301 NMSleepFlag_WPC2 0 "Alive" 1 "SleepInd" 2 "RESERVED" 3 "SleepAck" ;
VAL_ 1345 Destination_PSB 0 "0x0x0~0xFF:NM Source Node ID" 255 "0x0x0~0xFF:NM Source Node ID" ;
VAL_ 1345 NMCommandCode_PSB 1 "Alive" 2 "Ring" 3 "RESERVED" 4 "Limphome" 5 "0x5~0xFF:RESERVED" 255 "0x5~0xFF:RESERVED" ;
VAL_ 1345 NMSleepFlag_PSB 0 "Alive" 1 "SleepInd" 2 "RESERVED" 3 "SleepAck" ;
VAL_ 1323 Destination_SHVU_RR 0 "0x0x0~0xFF:NM Source Node ID" 255 "0x0x0~0xFF:NM Source Node ID" ;
VAL_ 1323 NMCommandCode_SHVU_RR 1 "Alive" 2 "Ring" 3 "RESERVED" 4 "Limphome" 5 "0x5~0xFF:RESERVED" 255 "0x5~0xFF:RESERVED" ;
VAL_ 1323 NMSleepFlag_SHVU_RR 0 "Alive" 1 "SleepInd" 2 "RESERVED" 3 "SleepAck" ;
VAL_ 1313 Destination_FCS 0 "0x0x0~0xFF:NM Source Node ID" 255 "0x0x0~0xFF:NM Source Node ID" ;
VAL_ 1313 NMCommandCode_FCS 1 "Alive" 2 "Ring" 3 "RESERVED" 4 "Limphome" 5 "0x5~0xFF:RESERVED" 255 "0x5~0xFF:RESERVED" ;
VAL_ 1313 NMSleepFlag_FCS 0 "Alive" 1 "SleepInd" 2 "RESERVED" 3 "SleepAck" ;
VAL_ 1297 Destination_EMCU 0 "0x0x0~0xFF:NM Source Node ID" 255 "0x0x0~0xFF:NM Source Node ID" ;
VAL_ 1297 NMCommandCode_EMCU 1 "Alive" 2 "Ring" 3 "RESERVED" 4 "Limphome" 5 "0x5~0xFF:RESERVED" 255 "0x5~0xFF:RESERVED" ;
VAL_ 1297 NMSleepFlag_EMCU 0 "Alive" 1 "SleepInd" 2 "RESERVED" 3 "SleepAck" ;
VAL_ 1307 Destination_SLB 0 "0x0x0~0xFF:NM Source Node ID" 255 "0x0x0~0xFF:NM Source Node ID" ;
VAL_ 1307 NMCommandCode_SLB 1 "Alive" 2 "Ring" 3 "RESERVED" 4 "Limphome" 5 "0x5~0xFF:RESERVED" 255 "0x5~0xFF:RESERVED" ;
VAL_ 1307 NMSleepFlag_SLB 0 "Alive" 1 "SleepInd" 2 "RESERVED" 3 "SleepAck" ;
VAL_ 1329 Destination_GW_APSU 0 "0x0x0~0xFF:NM Source Node ID" 255 "0x0x0~0xFF:NM Source Node ID" ;
VAL_ 1329 NMCommandCode_GW_APSU 1 "Alive" 2 "Ring" 3 "RESERVED" 4 "Limphome" 5 "0x5~0xFF:RESERVED" 255 "0x5~0xFF:RESERVED" ;
VAL_ 1329 NMSleepFlag_GW_APSU 0 "Alive" 1 "SleepInd" 2 "RESERVED" 3 "SleepAck" ;
VAL_ 1344 Destination_GW_DLBCU 0 "0x0x0~0xFF:NM Source Node ID" 255 "0x0x0~0xFF:NM Source Node ID" ;
VAL_ 1344 NMCommandCode_GW_DLBCU 1 "Alive" 2 "Ring" 3 "RESERVED" 4 "Limphome" 5 "0x5~0xFF:RESERVED" 255 "0x5~0xFF:RESERVED" ;
VAL_ 1344 NMSleepFlag_GW_DLBCU 0 "Alive" 1 "SleepInd" 2 "RESERVED" 3 "SleepAck" ;
VAL_ 1290 Destination_ARS 0 "0x0x0~0xFF:NM Source Node ID" 255 "0x0x0~0xFF:NM Source Node ID" ;
VAL_ 1290 NMCommandCode_ARS 1 "Alive" 2 "Ring" 3 "RESERVED" 4 "Limphome" 5 "0x5~0xFF:RESERVED" 255 "0x5~0xFF:RESERVED" ;
VAL_ 1290 NMSleepFlag_ARS 0 "Alive" 1 "SleepInd" 2 "RESERVED" 3 "SleepAck" ;
VAL_ 1341 Destination_RCM 0 "0x0x0~0xFF:NM Source Node ID" 255 "0x0x0~0xFF:NM Source Node ID" ;
VAL_ 1341 NMCommandCode_RCM 1 "Alive" 2 "Ring" 3 "RESERVED" 4 "Limphome" 5 "0x5~0xFF:RESERVED" 255 "0x5~0xFF:RESERVED" ;
VAL_ 1341 NMSleepFlag_RCM 0 "Alive" 1 "SleepInd" 2 "RESERVED" 3 "SleepAck" ;
VAL_ 1392 Destination_CGW_CCU 0 "0x0x0~0xFF:NM Source Node ID" 255 "0x0x0~0xFF:NM Source Node ID" ;
VAL_ 1392 NMCommandCode_CGW_CCU 1 "Alive" 2 "Ring" 3 "RESERVED" 4 "Limphome" 5 "0x5~0xFF:RESERVED" 255 "0x5~0xFF:RESERVED" ;
VAL_ 1392 NMSleepFlag_CGW_CCU 0 "Alive" 1 "SleepInd" 2 "RESERVED" 3 "SleepAck" ;
VAL_ 1308 Destination_GW_RLPSU 0 "0x0x0~0xFF:NM Source Node ID" 255 "0x0x0~0xFF:NM Source Node ID" ;
VAL_ 1308 NMCommandCode_GW_RLPSU 1 "Alive" 2 "Ring" 3 "RESERVED" 4 "Limphome" 5 "0x5~0xFF:RESERVED" 255 "0x5~0xFF:RESERVED" ;
VAL_ 1308 NMSleepFlag_GW_RLPSU 0 "Alive" 1 "SleepInd" 2 "RESERVED" 3 "SleepAck" ;
VAL_ 1360 Destination_ATS 0 "0x0x0~0xFF:NM Source Node ID" 255 "0x0x0~0xFF:NM Source Node ID" ;
VAL_ 1360 NMCommandCode_ATS 1 "Alive" 2 "Ring" 3 "RESERVED" 4 "Limphome" 5 "0x5~0xFF:RESERVED" 255 "0x5~0xFF:RESERVED" ;
VAL_ 1360 NMSleepFlag_ATS 0 "Alive" 1 "SleepInd" 2 "RESERVED" 3 "SleepAck" ;
VAL_ 1332 Destination_RLHV 0 "0x0x0~0xFF:NM Source Node ID" 255 "0x0x0~0xFF:NM Source Node ID" ;
VAL_ 1332 NMCommandCode_RLHV 1 "Alive" 2 "Ring" 3 "RESERVED" 4 "Limphome" 5 "0x5~0xFF:RESERVED" 255 "0x5~0xFF:RESERVED" ;
VAL_ 1332 NMSleepFlag_RLHV 0 "Alive" 1 "SleepInd" 2 "RESERVED" 3 "SleepAck" ;
VAL_ 1342 Destination_SGU 0 "0x0x0~0xFF:NM Source Node ID" 255 "0x0x0~0xFF:NM Source Node ID" ;
VAL_ 1342 NMCommandCode_SGU 1 "Alive" 2 "Ring" 3 "RESERVED" 4 "Limphome" 5 "0x5~0xFF:RESERVED" 255 "0x5~0xFF:RESERVED" ;
VAL_ 1342 NMSleepFlag_SGU 0 "Alive" 1 "SleepInd" 2 "RESERVED" 3 "SleepAck" ;
VAL_ 1325 Destination_PFSU 0 "0x0x0~0xFF:NM Source Node ID" 255 "0x0x0~0xFF:NM Source Node ID" ;
VAL_ 1325 NMCommandCode_PFSU 1 "Alive" 2 "Ring" 3 "RESERVED" 4 "Limphome" 5 "0x5~0xFF:RESERVED" 255 "0x5~0xFF:RESERVED" ;
VAL_ 1325 NMSleepFlag_PFSU 0 "Alive" 1 "SleepInd" 2 "RESERVED" 3 "SleepAck" ;
VAL_ 1348 Destination_ALBCU 0 "0x0x0~0xFF:NM Source Node ID" 255 "0x0x0~0xFF:NM Source Node ID" ;
VAL_ 1348 NMCommandCode_ALBCU 1 "Alive" 2 "Ring" 3 "RESERVED" 4 "Limphome" 5 "0x5~0xFF:RESERVED" 255 "0x5~0xFF:RESERVED" ;
VAL_ 1348 NMSleepFlag_ALBCU 0 "Alive" 1 "SleepInd" 2 "RESERVED" 3 "SleepAck" ;
VAL_ 1309 Destination_GW_RRPSU 0 "0x0x0~0xFF:NM Source Node ID" 255 "0x0x0~0xFF:NM Source Node ID" ;
VAL_ 1309 NMCommandCode_GW_RRPSU 1 "Alive" 2 "Ring" 3 "RESERVED" 4 "Limphome" 5 "0x5~0xFF:RESERVED" 255 "0x5~0xFF:RESERVED" ;
VAL_ 1309 NMSleepFlag_GW_RRPSU 0 "Alive" 1 "SleepInd" 2 "RESERVED" 3 "SleepAck" ;
VAL_ 1369 Destination_DSAU 0 "0x0x0~0xFF:NM Source Node ID" 255 "0x0x0~0xFF:NM Source Node ID" ;
VAL_ 1369 NMCommandCode_DSAU 1 "Alive" 2 "Ring" 3 "RESERVED" 4 "Limphome" 5 "0x5~0xFF:RESERVED" 255 "0x5~0xFF:RESERVED" ;
VAL_ 1369 NMSleepFlag_DSAU 0 "Alive" 1 "SleepInd" 2 "RESERVED" 3 "SleepAck" ;
VAL_ 1288 Destination_SWRC 0 "0x0x0~0xFF:NM Source Node ID" 255 "0x0x0~0xFF:NM Source Node ID" ;
VAL_ 1288 NMCommandCode_SWRC 1 "Alive" 2 "Ring" 3 "RESERVED" 4 "Limphome" 5 "0x5~0xFF:RESERVED" 255 "0x5~0xFF:RESERVED" ;
VAL_ 1288 NMSleepFlag_SWRC 0 "Alive" 1 "SleepInd" 2 "RESERVED" 3 "SleepAck" ;
VAL_ 1322 Destination_SHVU_FR 0 "0x0x0~0xFF:NM Source Node ID" 255 "0x0x0~0xFF:NM Source Node ID" ;
VAL_ 1322 NMCommandCode_SHVU_FR 1 "Alive" 2 "Ring" 3 "RESERVED" 4 "Limphome" 5 "0x5~0xFF:RESERVED" 255 "0x5~0xFF:RESERVED" ;
VAL_ 1322 NMSleepFlag_SHVU_FR 0 "Alive" 1 "SleepInd" 2 "RESERVED" 3 "SleepAck" ;
VAL_ 1350 Destination_RCS 0 "0x0x0~0xFF:NM Source Node ID" 255 "0x0x0~0xFF:NM Source Node ID" ;
VAL_ 1350 NMCommandCode_RCS 1 "Alive" 2 "Ring" 3 "RESERVED" 4 "Limphome" 5 "0x5~0xFF:RESERVED" 255 "0x5~0xFF:RESERVED" ;
VAL_ 1350 NMSleepFlag_RCS 0 "Alive" 1 "SleepInd" 2 "RESERVED" 3 "SleepAck" ;
VAL_ 1336 Destination_GW_DPSU 0 "0x0x0~0xFF:NM Source Node ID" 255 "0x0x0~0xFF:NM Source Node ID" ;
VAL_ 1336 NMCommandCode_GW_DPSU 1 "Alive" 2 "Ring" 3 "RESERVED" 4 "Limphome" 5 "0x5~0xFF:RESERVED" 255 "0x5~0xFF:RESERVED" ;
VAL_ 1336 NMSleepFlag_GW_DPSU 0 "Alive" 1 "SleepInd" 2 "RESERVED" 3 "SleepAck" ;
VAL_ 1352 Destination_BLTN_CAM 0 "0x0x0~0xFF:NM Source Node ID" 255 "0x0x0~0xFF:NM Source Node ID" ;
VAL_ 1352 NMCommandCode_BLTN_CAM 1 "Alive" 2 "Ring" 3 "RESERVED" 4 "Limphome" 5 "0x5~0xFF:RESERVED" 255 "0x5~0xFF:RESERVED" ;
VAL_ 1352 NMSleepFlag_BLTN_CAM 0 "Alive" 1 "SleepInd" 2 "RESERVED" 3 "SleepAck" ;
VAL_ 1287 Destination_SCM 0 "0x0x0~0xFF:NM Source Node ID" 255 "0x0x0~0xFF:NM Source Node ID" ;
VAL_ 1287 NMCommandCode_SCM 1 "Alive" 2 "Ring" 3 "RESERVED" 4 "Limphome" 5 "0x5~0xFF:RESERVED" 255 "0x5~0xFF:RESERVED" ;
VAL_ 1287 NMSleepFlag_SCM 0 "Alive" 1 "SleepInd" 2 "RESERVED" 3 "SleepAck" ;
VAL_ 1364 Destination_OHCL 0 "0x0x0~0xFF:NM Source Node ID" 255 "0x0x0~0xFF:NM Source Node ID" ;
VAL_ 1364 NMCommandCode_OHCL 1 "Alive" 2 "Ring" 3 "RESERVED" 4 "Limphome" 5 "0x5~0xFF:RESERVED" 255 "0x5~0xFF:RESERVED" ;
VAL_ 1364 NMSleepFlag_OHCL 0 "Alive" 1 "SleepInd" 2 "RESERVED" 3 "SleepAck" ;
VAL_ 1311 Destination_RWPC 0 "0x0x0~0xFF:NM Source Node ID" 255 "0x0x0~0xFF:NM Source Node ID" ;
VAL_ 1311 NMCommandCode_RWPC 1 "Alive" 2 "Ring" 3 "RESERVED" 4 "Limphome" 5 "0x5~0xFF:RESERVED" 255 "0x5~0xFF:RESERVED" ;
VAL_ 1311 NMSleepFlag_RWPC 0 "Alive" 1 "SleepInd" 2 "RESERVED" 3 "SleepAck" ;
VAL_ 1333 Destination_RRHV 0 "0x0x0~0xFF:NM Source Node ID" 255 "0x0x0~0xFF:NM Source Node ID" ;
VAL_ 1333 NMCommandCode_RRHV 1 "Alive" 2 "Ring" 3 "RESERVED" 4 "Limphome" 5 "0x5~0xFF:RESERVED" 255 "0x5~0xFF:RESERVED" ;
VAL_ 1333 NMSleepFlag_RRHV 0 "Alive" 1 "SleepInd" 2 "RESERVED" 3 "SleepAck" ;
VAL_ 1310 Destination_WPC 0 "0x0x0~0xFF:NM Source Node ID" 255 "0x0x0~0xFF:NM Source Node ID" ;
VAL_ 1310 NMCommandCode_WPC 1 "Alive" 2 "Ring" 3 "RESERVED" 4 "Limphome" 5 "0x5~0xFF:RESERVED" 255 "0x5~0xFF:RESERVED" ;
VAL_ 1310 NMSleepFlag_WPC 0 "Alive" 1 "SleepInd" 2 "RESERVED" 3 "SleepAck" ;
VAL_ 1354 Destination_HOD 0 "0x0x0~0xFF:NM Source Node ID" 255 "0x0x0~0xFF:NM Source Node ID" ;
VAL_ 1354 NMCommandCode_HOD 1 "Alive" 2 "Ring" 3 "RESERVED" 4 "Limphome" 5 "0x5~0xFF:RESERVED" 255 "0x5~0xFF:RESERVED" ;
VAL_ 1354 NMSleepFlag_HOD 0 "Alive" 1 "SleepInd" 2 "RESERVED" 3 "SleepAck" ;
VAL_ 1363 Destination_ASAU 0 "0x0x0~0xFF:NM Source Node ID" 255 "0x0x0~0xFF:NM Source Node ID" ;
VAL_ 1363 NMCommandCode_ASAU 1 "Alive" 2 "Ring" 3 "RESERVED" 4 "Limphome" 5 "0x5~0xFF:RESERVED" 255 "0x5~0xFF:RESERVED" ;
VAL_ 1363 NMSleepFlag_ASAU 0 "Alive" 1 "SleepInd" 2 "RESERVED" 3 "SleepAck" ;
